VERSION "HNNBNNNYNNNNNNNNNNNNNNNNNNNNNNNNNNNNNNNNNN/4/%%%/4/'%**4NNN///"

NS_ :

BS_:

BU_: BAP_Tester CGS Gateway Gateway_PAG HUD Kombi Kombi_LB Kombi_PAG Waehlhebel_SB

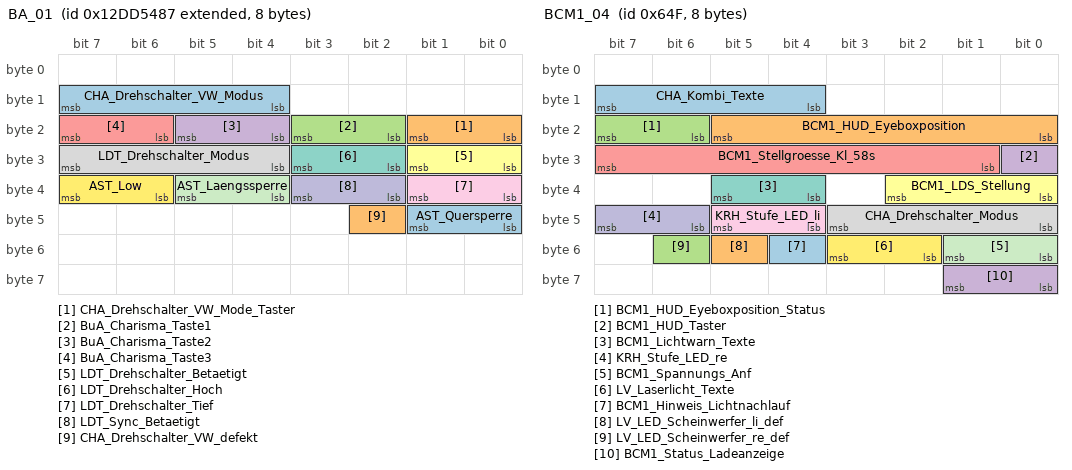
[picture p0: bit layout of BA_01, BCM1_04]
BO_ 2463978631 BA_01: 8 Kombi
 SG_ CHA_Drehschalter_VW_Modus : 12|4@1+ (1.0,0.0) [0.0|15] ""  Gateway,Gateway_PAG
 SG_ CHA_Drehschalter_VW_Mode_Taster : 16|2@1+ (1.0,0.0) [0.0|3] ""  Gateway,Gateway_PAG
 SG_ BuA_Charisma_Taste1 : 18|2@1+ (1.0,0.0) [0.0|3] ""  Gateway,Gateway_PAG
 SG_ BuA_Charisma_Taste2 : 20|2@1+ (1.0,0.0) [0.0|3] ""  Gateway,Gateway_PAG
 SG_ BuA_Charisma_Taste3 : 22|2@1+ (1.0,0.0) [0.0|3] ""  Gateway,Gateway_PAG
 SG_ LDT_Drehschalter_Betaetigt : 24|2@1+ (1.0,0.0) [0.0|3] ""  Gateway,Gateway_PAG
 SG_ LDT_Drehschalter_Hoch : 26|2@1+ (1.0,0.0) [0.0|3] ""  Gateway,Gateway_PAG
 SG_ LDT_Drehschalter_Modus : 28|4@1+ (1.0,0.0) [0.0|15] ""  Gateway,Gateway_PAG
 SG_ LDT_Drehschalter_Tief : 32|2@1+ (1.0,0.0) [0.0|3] ""  Gateway,Gateway_PAG
 SG_ LDT_Sync_Betaetigt : 34|2@1+ (1.0,0.0) [0.0|3] ""  Gateway,Gateway_PAG
 SG_ AST_Laengssperre : 36|2@1+ (1.0,0.0) [0.0|3] ""  Gateway,Gateway_PAG
 SG_ AST_Low : 38|2@1+ (1.0,0.0) [0.0|3] ""  Gateway,Gateway_PAG
 SG_ AST_Quersperre : 40|2@1+ (1.0,0.0) [0.0|3] ""  Gateway,Gateway_PAG
 SG_ CHA_Drehschalter_VW_defekt : 42|1@1+ (1.0,0.0) [0.0|1] ""  Gateway,Gateway_PAG

BO_ 2536703233 BAP_ACC_ASG_02: 8 Kombi
 SG_ BAP_ACC_ASG_02_Header : 0|8@1+ (1.0,0.0) [0.0|255] ""  Gateway,Gateway_PAG

BO_ 2536703248 BAP_ACC_FSG_01: 8 Gateway
 SG_ BAP_ACC_FSG_01_Header : 0|8@1+ (1.0,0.0) [0.0|255] ""  Kombi,Kombi_LB,Kombi_PAG

BO_ 2536722177 BAP_AHC_ASG_02: 8 Kombi_PAG
 SG_ BAP_AHC_ASG_02_Header : 0|8@1+ (1,0) [0|255] "Unit_None"  Gateway,Gateway_PAG

BO_ 2536722192 BAP_AHC_FSG_01: 8 Gateway
 SG_ BAP_AHC_FSG_01_Header : 0|8@1+ (1,0) [0|255] "Unit_None"  Kombi_PAG

BO_ 2536714496 BAP_Audio_ASG_01: 8 Kombi
 SG_ BAP_Audio_ASG_01_Header : 0|8@1+ (1.0,0.0) [0.0|255] ""  Gateway,Gateway_PAG

BO_ 2536714497 BAP_Audio_ASG_02: 8 Kombi
 SG_ BAP_Audio_ASG_02_Header : 0|8@1+ (1.0,0.0) [0.0|255] ""  Gateway,Gateway_PAG

BO_ 2536714498 BAP_Audio_ASG_03: 8 HUD
 SG_ BAP_Audio_ASG_03_Header : 0|8@1+ (1.0,0.0) [0.0|255] ""  Gateway,Gateway_PAG

BO_ 2536714499 BAP_Audio_ASG_04: 8 HUD
 SG_ BAP_Audio_ASG_04_Header : 0|8@1+ (1.0,0.0) [0.0|255] ""  Gateway,Gateway_PAG

BO_ 2536714512 BAP_Audio_FSG_01: 8 Gateway
 SG_ BAP_Audio_FSG_01_Header : 0|8@1+ (1.0,0.0) [0.0|255] ""  HUD,Kombi,Kombi_PAG

BO_ 2536714513 BAP_Audio_FSG_02: 8 Gateway
 SG_ BAP_Audio_FSG_02_Header : 0|8@1+ (1.0,0.0) [0.0|255] ""  HUD,Kombi,Kombi_PAG

BO_ 2536720385 BAP_AWC_ASG_02: 8 Kombi_PAG
 SG_ BAP_AWC_ASG_02_Header : 0|64@1+ (1.0,0.0) [0.0|18446744073709551615] ""  Gateway,Gateway_PAG

BO_ 2536720400 BAP_AWC_FSG_01: 8 Gateway
 SG_ BAP_AWC_FSG_01_Header : 0|8@1+ (1,0) [0|255] "Unit_None"  Kombi_PAG

BO_ 2536711426 BAP_BatteryControl_ASG_03: 8 Kombi
 SG_ BAP_BatteryControl_ASG_03_Header : 0|8@1+ (1.0,0.0) [0.0|255] ""  Gateway,Gateway_PAG

BO_ 2536711429 BAP_BatteryControl_ASG_06: 8 HUD
 SG_ BAP_BatteryControl_ASG_06_Header : 0|8@1+ (1.0,0.0) [0.0|255] ""  Gateway,Gateway_PAG

BO_ 2536711440 BAP_BatteryControl_FSG_01: 8 Gateway
 SG_ BAP_BatteryControl_FSG_01_Header : 0|8@1+ (1.0,0.0) [0.0|255] ""  HUD,Kombi,Kombi_LB,Kombi_PAG

BO_ 2536705792 BAP_BC_ASG_01: 8 Gateway
 SG_ BAP_BC_ASG_01_Header : 0|8@1+ (1.0,0.0) [0.0|255] ""  Kombi,Kombi_LB,Kombi_PAG

BO_ 2536705793 BAP_BC_ASG_02: 8 Gateway
 SG_ BAP_BC_ASG_02_Header : 0|8@1+ (1.0,0.0) [0.0|255] ""  Kombi,Kombi_LB,Kombi_PAG

BO_ 2536705794 BAP_BC_ASG_03: 8 Gateway
 SG_ BAP_BC_ASG_03_Header : 0|8@1+ (1.0,0.0) [0.0|255] ""  Kombi,Kombi_LB,Kombi_PAG

BO_ 2536705795 BAP_BC_ASG_04: 8 Gateway
 SG_ BAP_BC_ASG_04_Header : 0|8@1+ (1.0,0.0) [0.0|255] ""  Kombi,Kombi_LB,Kombi_PAG

BO_ 2536705796 BAP_BC_ASG_05: 8 Gateway_PAG
 SG_ BAP_BC_ASG_05_Header : 0|8@1+ (1,0) [0|255] "Unit_None"  Kombi_PAG

BO_ 2536705797 BAP_BC_ASG_06: 8 HUD
 SG_ BAP_BC_ASG_06_Header : 0|8@1+ (1,0) [0|255] "Unit_None"  Kombi_PAG

BO_ 2536705808 BAP_BC_FSG_01: 8 Kombi
 SG_ BAP_BC_FSG_01_Header : 0|8@1+ (1.0,0.0) [0.0|255] ""  Gateway,Gateway_PAG,HUD

BO_ 2536710912 BAP_BCmE_ASG_01: 8 Kombi
 SG_ BAP_BCmE_ASG_01_Header : 0|8@1+ (1.0,0.0) [0.0|255] ""  Gateway

BO_ 2536710928 BAP_BCmE_FSG_01: 8 Gateway
 SG_ BAP_BCmE_FSG_01_Header : 0|8@1+ (1.0,0.0) [0.0|255] ""  Kombi,Kombi_LB

BO_ 2536711680 BAP_Brake_ASG_01: 8 Gateway
 SG_ BAP_Brake_ASG_01_Header : 0|8@1+ (1.0,0.0) [0.0|255] ""  Kombi_PAG

BO_ 2536711696 BAP_Brake_FSG_01: 8 Kombi_PAG
 SG_ BAP_Brake_FSG_01_Header : 0|8@1+ (1.0,0.0) [0.0|255] ""  Gateway,Gateway_PAG

BO_ 2536707841 BAP_Charisma_ASG_02: 8 Kombi
 SG_ BAP_Charisma_ASG_02_Header : 0|8@1+ (1,0) [0|255] "Unit_None"  Gateway,Gateway_PAG

BO_ 2536707845 BAP_Charisma_ASG_06: 8 HUD
 SG_ BAP_Charisma_ASG_06_Header : 0|8@1+ (1.0,0.0) [0.0|255] ""  Gateway_PAG

BO_ 2536707856 BAP_Charisma_FSG_01: 8 Gateway
 SG_ BAP_Charisma_FSG_01_Header : 0|8@1+ (1.0,0.0) [0.0|255] ""  HUD,Kombi,Kombi_PAG

BO_ 2536767264 BAP_Debug_Cmd: 8 BAP_Tester
 SG_ BAP_Debug_Cmd : 0|16@1+ (1.0,0.0) [0.0|65535] ""  Gateway,Gateway_PAG,HUD,Kombi,Kombi_LB,Kombi_PAG

BO_ 2536767280 BAP_Debug_Data: 8 Gateway
 SG_ BAP_Debug_Data : 0|64@1+ (1.0,0.0) [0.0|18446744073709551615] ""  BAP_Tester

BO_ 2536719616 BAP_DisplayConfig_ASG_01: 8 Gateway
 SG_ BAP_DisplayConfig_ASG_01_Header : 0|8@1+ (1,0) [0|255] "Unit_None"  Kombi,Kombi_PAG

BO_ 2536719617 BAP_DisplayConfig_ASG_02: 8 Gateway
 SG_ BAP_DisplayConfig_ASG_02_Header : 0|64@1+ (1.0,0.0) [0.0|18446744073709551615] ""  Kombi,Kombi_PAG

BO_ 2536719632 BAP_DisplayConfig_FSG_01: 8 Kombi
 SG_ BAP_DisplayConfig_FSG_01_Header : 0|8@1+ (1,0) [0|255] "Unit_None"  Gateway,Gateway_PAG

BO_ 2536705282 BAP_Doorlocking_ASG_03: 8 Kombi
 SG_ BAP_Doorlocking_ASG_03_Header : 0|8@1+ (1.0,0.0) [0.0|255] ""  Gateway,Gateway_PAG

BO_ 2536705296 BAP_Doorlocking_FSG_01: 8 Gateway
 SG_ BAP_Doorlocking_FSG_01_Header : 0|8@1+ (1.0,0.0) [0.0|255] ""  Kombi,Kombi_LB,Kombi_PAG

BO_ 2536706816 BAP_Einheiten_ASG_01: 8 Gateway
 SG_ BAP_Einheiten_ASG_01_Header : 0|8@1+ (1.0,0.0) [0.0|255] ""  Kombi,Kombi_LB,Kombi_PAG

BO_ 2536706817 BAP_Einheiten_ASG_02: 8 Gateway
 SG_ BAP_Einheiten_ASG_02_Header : 0|8@1+ (1.0,0.0) [0.0|255] ""  Kombi_PAG

BO_ 2536706818 BAP_Einheiten_ASG_03: 8 Gateway
 SG_ BAP_Einheiten_ASG_03_Header : 0|8@1+ (1.0,0.0) [0.0|255] ""  Kombi,Kombi_LB,Kombi_PAG

BO_ 2536706819 BAP_Einheiten_ASG_04: 8 Gateway
 SG_ BAP_Einheiten_ASG_04_Header : 0|8@1+ (1,0) [0|255] "Unit_None"  Kombi,Kombi_LB,Kombi_PAG

BO_ 2536706832 BAP_Einheiten_FSG_01: 8 Kombi
 SG_ BAP_Einheiten_FSG_01_Header : 0|8@1+ (1.0,0.0) [0.0|255] ""  Gateway,Gateway_PAG

BO_ 2536702976 BAP_HUD_ASG_01: 8 Gateway
 SG_ BAP_HUD_ASG_01_Header : 0|8@1+ (1.0,0.0) [0.0|255] ""  HUD

BO_ 2536702977 BAP_HUD_ASG_02: 8 Kombi
 SG_ BAP_HUD_ASG_02_Header : 0|8@1+ (1,0) [0|255] "Unit_None"  HUD

BO_ 2536702978 BAP_HUD_ASG_03: 8 Gateway
 SG_ BAP_HUD_ASG_03_Header : 0|8@1+ (1,0) [0|255] "Unit_None"  HUD

BO_ 2536702992 BAP_HUD_FSG_01: 8 HUD
 SG_ BAP_HUD_FSG_01_Header : 0|8@1+ (1.0,0.0) [0.0|255] ""  Gateway,Gateway_PAG,Kombi,Kombi_PAG

BO_ 2536709121 BAP_Hybrid_ASG_02: 8 Kombi
 SG_ BAP_Hybrid_ASG_02_Header : 0|8@1+ (1.0,0.0) [0.0|255] ""  Gateway,Gateway_PAG

BO_ 2536709136 BAP_Hybrid_FSG_01: 8 Gateway
 SG_ BAP_Hybrid_FSG_01_Header : 0|8@1+ (1.0,0.0) [0.0|255] ""  Kombi,Kombi_LB,Kombi_PAG

BO_ 2536722945 BAP_IAA_PSO_ASG_02: 8 Kombi
 SG_ BAP_IAA_PSO_ASG_02_Header : 0|8@1+ (1,0) [0|255] "Unit_None"  Gateway

BO_ 2536722960 BAP_IAA_PSO_FSG_01: 8 Gateway
 SG_ BAP_IAA_PSO_FSG_01_Header : 0|8@1+ (1,0) [0|255] "Unit_None"  Kombi,Kombi_LB

BO_ 2536708353 BAP_LDW_ASG_02: 8 Kombi
 SG_ BAP_LDW_ASG_02_Header : 0|8@1+ (1.0,0.0) [0.0|255] ""  Gateway,Gateway_PAG

BO_ 2536708368 BAP_LDW_FSG_01: 8 Gateway
 SG_ BAP_LDW_FSG_01_Header : 0|8@1+ (1.0,0.0) [0.0|255] ""  Kombi,Kombi_LB,Kombi_PAG

BO_ 2536732672 BAP_LLCC_ASG_01: 8 Gateway
 SG_ BAP_LLCC_ASG_01_Header : 0|8@1+ (1,0) [0|255] "Unit_None"  Kombi_PAG

BO_ 2536732688 BAP_LLCC_FSG_01: 8 Kombi_PAG
 SG_ BAP_LLCC_FSG_01_Header : 0|8@1+ (1,0) [0|255] "Unit_None"  Gateway,Gateway_PAG

BO_ 2536715264 BAP_MFL_ASG_01: 8 Kombi
 SG_ BAP_MFL_ASG_01_Header : 0|8@1+ (1.0,0.0) [0.0|255] ""  Gateway,Gateway_PAG

BO_ 2536715280 BAP_MFL_FSG_01: 8 Gateway
 SG_ BAP_MFL_FSG_01_Header : 0|8@1+ (1.0,0.0) [0.0|255] ""  Kombi,Kombi_PAG

BO_ 2536714752 BAP_Navigation_ASG_01: 8 Kombi
 SG_ BAP_Navigation_ASG_01_Header : 0|8@1+ (1.0,0.0) [0.0|255] ""  Gateway,Gateway_PAG

BO_ 2536714753 BAP_Navigation_ASG_02: 8 Kombi
 SG_ BAP_Navigation_ASG_02_Header : 0|8@1+ (1.0,0.0) [0.0|255] ""  Gateway,Gateway_PAG

BO_ 2536714754 BAP_Navigation_ASG_03: 8 HUD
 SG_ BAP_Navigation_ASG_03_Header : 0|8@1+ (1.0,0.0) [0.0|255] ""  Gateway,Gateway_PAG

BO_ 2536714755 BAP_Navigation_ASG_04: 8 HUD
 SG_ BAP_Navigation_ASG_04_Header : 0|8@1+ (1.0,0.0) [0.0|255] ""  Gateway,Gateway_PAG

BO_ 2536714768 BAP_Navigation_FSG_01: 8 Gateway
 SG_ BAP_Navigation_FSG_01_Header : 0|8@1+ (1.0,0.0) [0.0|255] ""  HUD,Kombi,Kombi_PAG

BO_ 2536714769 BAP_Navigation_FSG_02: 8 Gateway
 SG_ BAP_Navigation_FSG_02_Header : 0|8@1+ (1.0,0.0) [0.0|255] ""  HUD,Kombi,Kombi_PAG

BO_ 2536708097 BAP_Nightvision_ASG_02: 8 Kombi
 SG_ BAP_Nightvision_ASG_02_Header : 0|8@1+ (1.0,0.0) [0.0|255] ""  Gateway,Gateway_PAG

BO_ 2536708112 BAP_Nightvision_FSG_01: 8 Gateway
 SG_ BAP_Nightvision_FSG_01_Header : 0|8@1+ (1.0,0.0) [0.0|255] ""  Kombi

BO_ 2536712704 BAP_OnlineFunctions_ASG_01: 8 Kombi
 SG_ BAP_OnlineFunction_ASG_01_Header : 0|8@1+ (1,0) [0|255] "Unit_None"  Gateway,Gateway_PAG

BO_ 2536712705 BAP_OnlineFunctions_ASG_02: 8 HUD
 SG_ BAP_OnlineFunction_ASG_02_Header : 0|8@1+ (1,0) [0|255] "Unit_None"  Gateway,Gateway_PAG

BO_ 2536712720 BAP_OnlineFunctions_FSG_01: 8 Gateway
 SG_ BAP_OnlineFunction_FSG_01_Header : 0|8@1+ (1,0) [0|255] "Unit_None"  HUD,Kombi,Kombi_PAG

BO_ 2536702723 BAP_ParkHeater_ASG_04: 8 Kombi_PAG
 SG_ BAP_ParkHeater_ASG_04_Header : 0|64@1+ (1.0,0.0) [0.0|18446744073709551615] ""  Gateway,Gateway_PAG

BO_ 2536702736 BAP_ParkHeater_FSG_01: 8 Gateway
 SG_ BAP_ParkHeater_FSG_01_Header : 0|8@1+ (1.0,0.0) [0.0|255] ""  Kombi_PAG

BO_ 2536703745 BAP_RDK_ASG_02: 8 Kombi
 SG_ BAP_RDK_ASG_02_Header : 0|8@1+ (1.0,0.0) [0.0|255] ""  Gateway,Gateway_PAG

BO_ 2536703760 BAP_RDK_FSG_01: 8 Gateway
 SG_ BAP_RDK_FSG_01_Header : 0|8@1+ (1.0,0.0) [0.0|255] ""  Kombi,Kombi_LB,Kombi_PAG

BO_ 2536709889 BAP_RGS_ASG_02: 8 Kombi
 SG_ BAP_RGS_ASG_02_Header : 0|8@1+ (1,0) [0|255] "Unit_None"  Gateway,Gateway_PAG

BO_ 2536709904 BAP_RGS_FSG_01: 8 Gateway
 SG_ BAP_RGS_FSG_01_Header : 0|8@1+ (1.0,0.0) [0.0|255] ""  Kombi,Kombi_LB

BO_ 2536719872 BAP_SDS_ASG_01: 8 Kombi
 SG_ BAP_SDS_ASG_01_Header : 0|8@1+ (1,0) [0|255] "Unit_None"  Gateway,Gateway_PAG

BO_ 2536719888 BAP_SDS_FSG_01: 8 Gateway
 SG_ BAP_SDS_FSG_01_Header : 0|8@1+ (1,0) [0|255] "Unit_None"  Kombi,Kombi_PAG

BO_ 2536706560 BAP_SIA_ASG_01: 8 Gateway
 SG_ BAP_SIA_ASG_01_Header : 0|8@1+ (1.0,0.0) [0.0|255] ""  Kombi,Kombi_LB,Kombi_PAG

BO_ 2536706561 BAP_SIA_ASG_02: 8 Gateway
 SG_ BAP_SIA_ASG_02_Header : 0|8@1+ (1.0,0.0) [0.0|255] ""  Kombi,Kombi_LB,Kombi_PAG

BO_ 2536706562 BAP_SIA_ASG_03: 8 Gateway
 SG_ BAP_SIA_ASG_03_Header : 0|8@1+ (1,0) [0|255] "Unit_None"  Kombi_PAG

BO_ 2536706576 BAP_SIA_FSG_01: 8 Kombi
 SG_ BAP_SIA_FSG_01_Header : 0|8@1+ (1.0,0.0) [0.0|255] ""  Gateway,Gateway_PAG

BO_ 2536720896 BAP_Statistics_ASG_01: 8 Gateway
 SG_ BAP_Statistics_ASG_01_Header : 0|8@1+ (1,0) [0|255] "Unit_None"  Kombi

BO_ 2536720912 BAP_Statistics_FSG_01: 8 Kombi
 SG_ BAP_Statistics_FSG_01_Header : 0|8@1+ (1,0) [0|255] "Unit_None"  Gateway,Gateway_PAG

BO_ 2536703489 BAP_SuspensionControl_ASG_02: 8 Kombi
 SG_ BAP_SuspensionControl_ASG_02_Hea : 0|8@1+ (1.0,0.0) [0.0|255] ""  Gateway,Gateway_PAG

BO_ 2536703504 BAP_SuspensionControl_FSG_01: 8 Gateway
 SG_ BAP_SuspensionControl_FSG_01_Hea : 0|8@1+ (1.0,0.0) [0.0|255] ""  Kombi,Kombi_PAG

BO_ 2536708609 BAP_SWA_ASG_02: 8 Kombi
 SG_ BAP_SWA_ASG_02_Header : 0|8@1+ (1.0,0.0) [0.0|255] ""  Gateway,Gateway_PAG

BO_ 2536708624 BAP_SWA_FSG_01: 8 Gateway
 SG_ BAP_SWA_FSG_01_Header : 0|8@1+ (1.0,0.0) [0.0|255] ""  Kombi,Kombi_LB

BO_ 2536712448 BAP_Telefon2_ASG_01: 8 Kombi
 SG_ BAP_Telefon2_ASG_01_Header : 0|8@1+ (1.0,0.0) [0.0|255] ""  Gateway,Gateway_PAG

BO_ 2536712449 BAP_Telefon2_ASG_02: 8 HUD
 SG_ BAP_Telefon2_ASG_02_Header : 0|8@1+ (1,0) [0|255] "Unit_None"  Gateway,Gateway_PAG

BO_ 2536712464 BAP_Telefon2_FSG_01: 8 Gateway
 SG_ BAP_Telefon2_FSG_01_Header : 0|8@1+ (1.0,0.0) [0.0|255] ""  HUD,Kombi,Kombi_PAG

BO_ 2536712465 BAP_Telefon2_FSG_02: 8 Gateway
 SG_ BAP_Telefon2_FSG_02_Header : 0|8@1+ (1,0) [0|255] "Unit_None"  HUD,Kombi,Kombi_PAG

BO_ 2536712192 BAP_Telefon_ASG_01: 8 Kombi
 SG_ BAP_Telefon_ASG_01_Header : 0|8@1+ (1.0,0.0) [0.0|255] ""  Gateway,Gateway_PAG

BO_ 2536712193 BAP_Telefon_ASG_02: 8 Kombi
 SG_ BAP_Telefon_ASG_02_Header : 0|8@1+ (1.0,0.0) [0.0|255] ""  Gateway,Gateway_PAG

BO_ 2536712194 BAP_Telefon_ASG_03: 8 HUD
 SG_ BAP_Telefon_ASG_03_Header : 0|8@1+ (1,0) [0|255] "Unit_None"  Gateway,Gateway_PAG

BO_ 2536712195 BAP_Telefon_ASG_04: 8 HUD
 SG_ BAP_Telefon_ASG_04_Header : 0|8@1+ (1,0) [0|255] "Unit_None"  Gateway,Gateway_PAG

BO_ 2536712208 BAP_Telefon_FSG_01: 8 Gateway
 SG_ BAP_Telefon_FSG_01_Header : 0|8@1+ (1.0,0.0) [0.0|255] ""  HUD,Kombi,Kombi_PAG

BO_ 2536712209 BAP_Telefon_FSG_02: 8 Gateway
 SG_ BAP_Telefon_FSG_02_Header : 0|8@1+ (1.0,0.0) [0.0|255] ""  HUD,Kombi,Kombi_PAG

BO_ 2536711169 BAP_TiltAngle_ASG_02: 8 Kombi
 SG_ BAP_TiltAngle_ASG_02_Header : 0|8@1+ (1.0,0.0) [0.0|255] ""  Gateway,Gateway_PAG

BO_ 2536711170 BAP_TiltAngle_ASG_03: 8 HUD
 SG_ BAP_TiltAngle_ASG_03_Header : 0|8@1+ (1,0) [0|255] "Unit_None"  Gateway,Gateway_PAG

BO_ 2536711184 BAP_TiltAngle_FSG_01: 8 Gateway
 SG_ BAP_TiltAngle_FSG_01_Header : 0|8@1+ (1.0,0.0) [0.0|255] ""  HUD,Kombi,Kombi_LB

BO_ 2536706304 BAP_Uhrzeit_ASG_01: 8 Gateway
 SG_ BAP_Uhrzeit_ASG_01_Header : 0|8@1+ (1.0,0.0) [0.0|255] ""  Kombi,Kombi_LB,Kombi_PAG

BO_ 2536706305 BAP_Uhrzeit_ASG_02: 8 Gateway
 SG_ BAP_Uhrzeit_ASG_02_Header : 0|8@1+ (1.0,0.0) [0.0|255] ""  Kombi,Kombi_LB,Kombi_PAG

BO_ 2536706306 BAP_Uhrzeit_ASG_03: 8 Gateway
 SG_ BAP_Uhrzeit_ASG_03_Header : 0|8@1+ (1.0,0.0) [0.0|255] ""  Kombi,Kombi_LB,Kombi_PAG

BO_ 2536706308 BAP_Uhrzeit_ASG_05: 8 Gateway
 SG_ BAP_Uhrzeit_ASG_05_Header : 0|8@1+ (1.0,0.0) [0.0|255] ""  Kombi,Kombi_LB,Kombi_PAG

BO_ 2536706309 BAP_Uhrzeit_ASG_06: 8 Gateway
 SG_ BAP_Uhrzeit_ASG_06_Header : 0|8@1+ (1.0,0.0) [0.0|255] ""  Kombi,Kombi_LB,Kombi_PAG

BO_ 2536706310 BAP_Uhrzeit_ASG_07: 8 Gateway
 SG_ BAP_Uhrzeit_ASG_07_Header : 0|64@1+ (1.0,0.0) [0.0|18446744073709551615] ""  Kombi_LB,Kombi_PAG

BO_ 2536706311 BAP_Uhrzeit_ASG_08: 8 HUD
 SG_ BAP_Uhrzeit_ASG_08_Header : 0|8@1+ (1,0) [0|255] "Unit_None"  Kombi_PAG

BO_ 2536706320 BAP_Uhrzeit_FSG_01: 8 Kombi
 SG_ BAP_Uhrzeit_FSG_01_Header : 0|8@1+ (1.0,0.0) [0.0|255] ""  Gateway,Gateway_PAG,HUD

BO_ 2536710401 BAP_VZA_ASG_02: 8 Kombi
 SG_ BAP_VZA_ASG_02_Header : 0|8@1+ (1.0,0.0) [0.0|255] ""  Gateway,Gateway_PAG

BO_ 2536710416 BAP_VZA_FSG_01: 8 Gateway
 SG_ BAP_VZA_FSG_01_Header : 0|8@1+ (1.0,0.0) [0.0|255] ""  Kombi,Kombi_LB,Kombi_PAG

BO_ 1615 BCM1_04: 8 Gateway
 SG_ CHA_Kombi_Texte : 12|4@1+ (1.0,0.0) [0.0|15] ""  Vector__XXX
 SG_ BCM1_HUD_Eyeboxposition : 16|6@1+ (1,0) [0|63] ""  HUD
 SG_ BCM1_HUD_Eyeboxposition_Status : 22|2@1+ (1.0,0.0) [0.0|3] ""  HUD
 SG_ BCM1_HUD_Taster : 24|1@1+ (1.0,0.0) [0.0|1] ""  HUD
 SG_ BCM1_Stellgroesse_Kl_58s : 25|7@1+ (1,0) [0|100] ""  HUD
 SG_ BCM1_LDS_Stellung : 32|3@1+ (1.0,0.0) [0.0|7] ""  Vector__XXX
 SG_ BCM1_Lichtwarn_Texte : 36|2@1+ (1.0,0.0) [0.0|3] ""  Vector__XXX
 SG_ CHA_Drehschalter_Modus : 40|4@1+ (1.0,0.0) [0.0|15] ""  Vector__XXX
 SG_ KRH_Stufe_LED_li : 44|2@1+ (1.0,0.0) [0.0|3] ""  Vector__XXX
 SG_ KRH_Stufe_LED_re : 46|2@1+ (1.0,0.0) [0.0|3] ""  Vector__XXX
 SG_ BCM1_Spannungs_Anf : 48|2@1+ (1.0,0.0) [0.0|3] ""  Vector__XXX
 SG_ LV_Laserlicht_Texte : 50|2@1+ (1.0,0.0) [0.0|3] ""  Kombi,Kombi_LB
 SG_ BCM1_Hinweis_Lichtnachlauf : 52|1@1+ (1.0,0.0) [0.0|1] ""  Vector__XXX
 SG_ LV_LED_Scheinwerfer_li_def : 53|1@1+ (1.0,0.0) [0.0|1] ""  Vector__XXX
 SG_ LV_LED_Scheinwerfer_re_def : 54|1@1+ (1.0,0.0) [0.0|1] ""  Vector__XXX
 SG_ BCM1_Status_Ladeanzeige : 56|2@1+ (1.0,0.0) [0.0|3] ""  Vector__XXX

BO_ 1626 BCM_01: 8 Gateway
 SG_ BCM_Bremsbelag_Sensor : 12|1@1+ (1.0,0.0) [0.0|1] ""  Kombi,Kombi_LB,Kombi_PAG
 SG_ BCM_Bremsfluessigkeit_Sensor : 13|1@1+ (1.0,0.0) [0.0|1] ""  Kombi,Kombi_LB,Kombi_PAG
 SG_ BCM1_Licht_Warn : 14|1@1+ (1.0,0.0) [0.0|1] ""  Vector__XXX
 SG_ BCM_Waschwasser_Sensor : 15|1@1+ (1.0,0.0) [0.0|1] ""  Kombi,Kombi_LB,Kombi_PAG
 SG_ BCM_Kuehlmittel_Sensor : 16|1@1+ (1.0,0.0) [0.0|1] ""  Kombi,Kombi_LB,Kombi_PAG
 SG_ BCM1_Kl_15_HW_erkannt : 17|1@1+ (1.0,0.0) [0.0|1] ""  Vector__XXX
 SG_ BCM1_Kl_15_Sig_HW_erkannt : 18|1@1+ (1.0,0.0) [0.0|1] ""  Vector__XXX
 SG_ BCM_Kuehlmittel_Sensor_02 : 19|1@1+ (1.0,0.0) [0.0|1] ""  Kombi,Kombi_LB,Kombi_PAG
 SG_ BCM1_Hinweis_Lichtnachlauf : 20|1@1+ (1.0,0.0) [0.0|1] ""  Kombi,Kombi_LB,Kombi_PAG
 SG_ BCM_Offroad_Taste : 21|1@1+ (1.0,0.0) [0.0|1] ""  Vector__XXX
 SG_ BCM_Hybrid_StSt_Taste_Fehler : 23|1@1+ (1.0,0.0) [0.0|1] ""  Vector__XXX
 SG_ BCM_Hybrid_StartStopp_Taste : 24|1@1+ (1.0,0.0) [0.0|1] ""  Vector__XXX
 SG_ BCM1_Warnblink_Taster : 25|1@1+ (1.0,0.0) [0.0|1] ""  Vector__XXX
 SG_ BCM1_Valet_Parking_Taster : 26|1@1+ (1.0,0.0) [0.0|1] ""  Vector__XXX
 SG_ BCM1_LDS_Stellung : 27|3@1+ (1.0,0.0) [0.0|7] ""  Vector__XXX
 SG_ BCM1_Rueckfahrlicht_Schalter : 30|1@1+ (1.0,0.0) [0.0|1] ""  Vector__XXX
 SG_ BCM1_MH_Schalter : 31|1@1+ (1.0,0.0) [0.0|1] ""  Kombi,Kombi_LB,Kombi_PAG
 SG_ BCM1_MH_WIV_Schalter : 32|1@1+ (1.0,0.0) [0.0|1] ""  Vector__XXX
 SG_ BCM_Eco_Charisma_Taste : 33|1@1+ (1.0,0.0) [0.0|1] ""  Vector__XXX
 SG_ BCM1_NV_Taster : 34|1@1+ (1.0,0.0) [0.0|1] ""  Kombi,Kombi_LB,Kombi_PAG
 SG_ BCM1_AFS_Lampe : 35|1@1+ (1.0,0.0) [0.0|1] ""  Kombi,Kombi_LB,Kombi_PAG
 SG_ BCM1_Reisemodus_Texte : 36|2@1+ (1.0,0.0) [0.0|3] ""  Kombi,Kombi_LB,Kombi_PAG
 SG_ BCM1_Lichtwarn_Texte : 38|2@1+ (1.0,0.0) [0.0|3] ""  Kombi,Kombi_LB,Kombi_PAG
 SG_ Gong_TFL_Umschaltung : 40|1@1+ (1.0,0.0) [0.0|1] ""  Vector__XXX
 SG_ UGDO_Function_01 : 41|3@1+ (1.0,0.0) [0.0|7] ""  Vector__XXX
 SG_ APS_Tongeber_defekt : 44|1@1+ (1.0,0.0) [0.0|1] ""  Vector__XXX
 SG_ BCM1_EasyEntry_Status : 45|1@1+ (1.0,0.0) [0.0|1] ""  Vector__XXX
 SG_ BCM1_Lenksaeule_aktiv : 46|1@1+ (1.0,0.0) [0.0|1] ""  Vector__XXX
 SG_ BCM1_St_SW_Diebstahl_links : 47|1@1+ (1.0,0.0) [0.0|1] ""  Vector__XXX
 SG_ BCM1_St_SW_Diebstahl_rechts : 48|1@1+ (1.0,0.0) [0.0|1] ""  Vector__XXX
 SG_ ISP_Dimmung_ASP_02 : 49|6@1+ (0.0226,0) [0.0000|1.4012] "Unit_Volt"  Vector__XXX
 SG_ BCM1_Schluesselsuche_Anf : 55|1@1+ (1.0,0.0) [0.0|1] ""  Vector__XXX
 SG_ BCM1_Fahrlicht_Hinweis : 62|1@1+ (1.0,0.0) [0.0|1] ""  Kombi,Kombi_LB,Kombi_PAG
 SG_ BCM_HDF_betaetigt : 63|1@1+ (1.0,0.0) [0.0|1] ""  Vector__XXX

BO_ 672 BCM_02: 8 Gateway
 SG_ BCM_02_CRC : 0|8@1+ (1,0) [0|255] ""  Kombi_PAG
 SG_ BCM_02_BZ : 8|4@1+ (1,0) [0|15] ""  Kombi_PAG
 SG_ BCM2_Crashfall_erkannt : 12|1@1+ (1.0,0.0) [0.0|1] ""  Vector__XXX
 SG_ ZZH_Endlage_oben : 13|1@1+ (1.0,0.0) [0.0|1] ""  Vector__XXX
 SG_ ZZH_Endlage_unplausibel : 14|1@1+ (1.0,0.0) [0.0|1] ""  Vector__XXX
 SG_ ZZH_Endlage_unten : 15|1@1+ (1.0,0.0) [0.0|1] ""  Vector__XXX
 SG_ BCM2_Unterdr_Zuendungsmeldung : 16|1@1+ (1.0,0.0) [0.0|1] ""  Vector__XXX
 SG_ BCM2_SST_gedrueckt : 17|1@1+ (1.0,0.0) [0.0|1] ""  Vector__XXX
 SG_ BCM_Waehlhebel_P_Hinweis : 18|1@1+ (1.0,0.0) [0.0|1] ""  Kombi,Kombi_LB,Kombi_PAG
 SG_ BCM_ValetTaster_Fkts_LED : 19|1@1+ (1.0,0.0) [0.0|1] ""  Kombi,Kombi_LB
 SG_ BCM2_KL15_Absch_FT : 20|1@1+ (1.0,0.0) [0.0|1] ""  Vector__XXX
 SG_ Heckwischer_Status : 21|2@1+ (1.0,0.0) [0.0|3] ""  Vector__XXX
 SG_ BCM2_P_verriegelt : 23|1@1+ (1.0,0.0) [0.0|1] ""  Vector__XXX
 SG_ FSH_LED : 24|1@1+ (1.0,0.0) [0.0|1] ""  Kombi_PAG
 SG_ HSH_LED : 25|1@1+ (1.0,0.0) [0.0|1] ""  Vector__XXX
 SG_ Niveausensor_VL_verbaut : 26|1@1+ (1.0,0.0) [0.0|1] ""  Vector__XXX
 SG_ Niveausensor_HL_verbaut : 27|1@1+ (1.0,0.0) [0.0|1] ""  Vector__XXX
 SG_ FA_Hoehenwert_VL_01 : 28|8@1+ (0.4,0) [0.0|100.0] "Unit_PerCent"  Vector__XXX
 SG_ FA_Hoehenwert_HL_01 : 36|8@1+ (0.4,0) [0.0|100.0] "Unit_PerCent"  Vector__XXX
 SG_ BCM_Anf_Aussenwarnung : 44|1@1+ (1.0,0.0) [0.0|1] ""  Vector__XXX
 SG_ BCM_Aussenwarnung_Konfig : 45|3@1+ (1.0,0.0) [0.0|7] ""  Vector__XXX
 SG_ BCM2_Freigabe_Kofferr_Innenentr : 48|1@1+ (1.0,0.0) [0.0|1] ""  Vector__XXX
 SG_ BCM_RLU_Wakeup_Anforderung : 49|1@1+ (1.0,0.0) [0.0|1] ""  Vector__XXX
 SG_ Heckrollo_Privacy_aktiv : 50|1@1+ (1.0,0.0) [0.0|1] ""  Vector__XXX
 SG_ Heckrollo_Verfahrrichtung : 51|3@1+ (1.0,0.0) [0.0|7] ""  Vector__XXX
 SG_ BCM2_TrunkEntrapment_Warn : 54|1@1+ (1.0,0.0) [0.0|1] ""  Kombi,Kombi_LB,Kombi_PAG
 SG_ BCM2_Quittierung_Warnton_aktiv : 55|1@1+ (1.0,0.0) [0.0|1] ""  Vector__XXX
 SG_ BCM_Handbremse_Hinweis : 56|1@1+ (1.0,0.0) [0.0|1] ""  Kombi,Kombi_LB,Kombi_PAG
 SG_ Remote_Rollo_HBFS_hoch : 57|1@1+ (1.0,0.0) [0.0|1] ""  Vector__XXX
 SG_ Remote_Rollo_HBFS_tief : 58|1@1+ (1.0,0.0) [0.0|1] ""  Vector__XXX
 SG_ Remote_Rollo_HFS_hoch : 59|1@1+ (1.0,0.0) [0.0|1] ""  Vector__XXX
 SG_ Remote_Rollo_HFS_tief : 60|1@1+ (1.0,0.0) [0.0|1] ""  Vector__XXX
 SG_ BCM2_T_Deckel_Vorne : 61|1@1+ (1.0,0.0) [0.0|1] ""  Vector__XXX

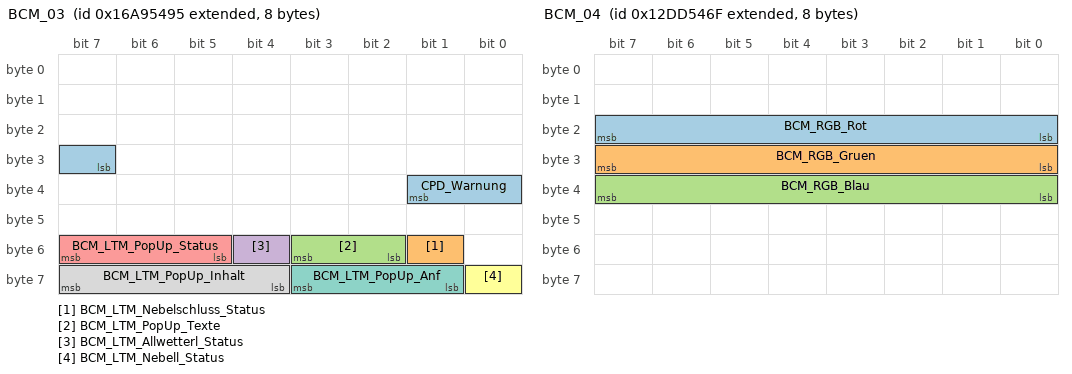
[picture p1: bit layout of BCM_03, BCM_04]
BO_ 2527679637 BCM_03: 8 Gateway
 SG_ CPD_Warnung : 31|3@1+ (1.0,0.0) [0.0|7] ""  Kombi,Kombi_LB,Kombi_PAG
 SG_ BCM_LTM_Nebelschluss_Status : 49|1@1+ (1.0,0.0) [0.0|1] ""  Kombi,Kombi_LB,Kombi_PAG
 SG_ BCM_LTM_PopUp_Texte : 50|2@1+ (1.0,0.0) [0.0|3] ""  Kombi_PAG
 SG_ BCM_LTM_Allwetterl_Status : 52|1@1+ (1.0,0.0) [0.0|1] ""  Kombi,Kombi_LB,Kombi_PAG
 SG_ BCM_LTM_PopUp_Status : 53|3@1+ (1.0,0.0) [0.0|7] ""  Kombi,Kombi_LB,Kombi_PAG
 SG_ BCM_LTM_Nebell_Status : 56|1@1+ (1.0,0.0) [0.0|1] ""  Kombi,Kombi_LB,Kombi_PAG
 SG_ BCM_LTM_PopUp_Anf : 57|3@1+ (1.0,0.0) [0.0|7] ""  Kombi,Kombi_LB,Kombi_PAG
 SG_ BCM_LTM_PopUp_Inhalt : 60|4@1+ (1.0,0.0) [0.0|15] ""  Kombi,Kombi_LB,Kombi_PAG

BO_ 2463978607 BCM_04: 8 Gateway
 SG_ BCM_RGB_Rot : 16|8@1+ (1,0) [0|255] ""  Kombi
 SG_ BCM_RGB_Gruen : 24|8@1+ (1,0) [0|255] ""  Kombi,Kombi_LB
 SG_ BCM_RGB_Blau : 32|8@1+ (1,0) [0|255] ""  Kombi,Kombi_LB

BO_ 870 Blinkmodi_02: 8 Gateway
 SG_ BM_ZV_auf : 12|1@1+ (1.0,0.0) [0.0|1] ""  Vector__XXX
 SG_ BM_ZV_zu : 13|1@1+ (1.0,0.0) [0.0|1] ""  Vector__XXX
 SG_ BM_DWA_ein : 14|1@1+ (1.0,0.0) [0.0|1] ""  Vector__XXX
 SG_ BM_DWA_Alarm : 15|1@1+ (1.0,0.0) [0.0|1] ""  Vector__XXX
 SG_ BM_Crash : 16|1@1+ (1.0,0.0) [0.0|1] ""  Vector__XXX
 SG_ BM_Panik : 17|1@1+ (1.0,0.0) [0.0|1] ""  Vector__XXX
 SG_ BM_Not_Bremsung : 18|1@1+ (1.0,0.0) [0.0|1] ""  Vector__XXX
 SG_ BM_GDO : 19|1@1+ (1.0,0.0) [0.0|1] ""  Vector__XXX
 SG_ BM_Warnblinken : 20|1@1+ (1.0,0.0) [0.0|1] ""  Kombi,Kombi_LB
 SG_ BM_Taxi_Notalarm : 21|1@1+ (1.0,0.0) [0.0|1] ""  Vector__XXX
 SG_ BM_Telematik : 22|1@1+ (1.0,0.0) [0.0|1] ""  Vector__XXX
 SG_ BM_links : 23|1@1+ (1.0,0.0) [0.0|1] ""  Vector__XXX
 SG_ BM_rechts : 24|1@1+ (1.0,0.0) [0.0|1] ""  Vector__XXX
 SG_ Blinken_li_Fzg_Takt : 25|1@1+ (1.0,0.0) [0.0|1] ""  Vector__XXX
 SG_ Blinken_re_Fzg_Takt : 26|1@1+ (1.0,0.0) [0.0|1] ""  Vector__XXX
 SG_ Blinken_li_Kombi_Takt : 27|1@1+ (1.0,0.0) [0.0|1] ""  Kombi,Kombi_LB,Kombi_PAG
 SG_ Blinken_re_Kombi_Takt : 28|1@1+ (1.0,0.0) [0.0|1] ""  Kombi,Kombi_LB,Kombi_PAG
 SG_ BM_NBA_n_codiert_n_aktiv : 29|1@1+ (1.0,0.0) [0.0|1] ""  Vector__XXX
 SG_ BM_NBA_Status : 30|2@1+ (1.0,0.0) [0.0|3] ""  Vector__XXX
 SG_ BM_WBT_Beleuchtung : 32|1@1+ (1.0,0.0) [0.0|1] ""  Vector__XXX
 SG_ BM_HD_Oeffnung_angelernt : 33|1@1+ (1.0,0.0) [0.0|1] ""  Vector__XXX
 SG_ BM_Autobahn : 34|1@1+ (1.0,0.0) [0.0|1] ""  Vector__XXX
 SG_ BM_Rollenmodus_Blinken : 35|1@1+ (1.0,0.0) [0.0|1] ""  Vector__XXX
 SG_ BM_Recas : 36|1@1+ (1.0,0.0) [0.0|1] ""  Vector__XXX
 SG_ BM_Wischblinken : 37|1@1+ (1.0,0.0) [0.0|1] ""  Vector__XXX
 SG_ BM_Telematik_Abbruchgrund : 38|6@1+ (1.0,0.0) [0.0|63] ""  Vector__XXX
 SG_ BM_PiloPa : 44|1@1+ (1.0,0.0) [0.0|1] ""  Vector__XXX
 SG_ DWA_Alarmquelle : 59|5@1+ (1.0,0.0) [0.0|31] ""  Vector__XXX

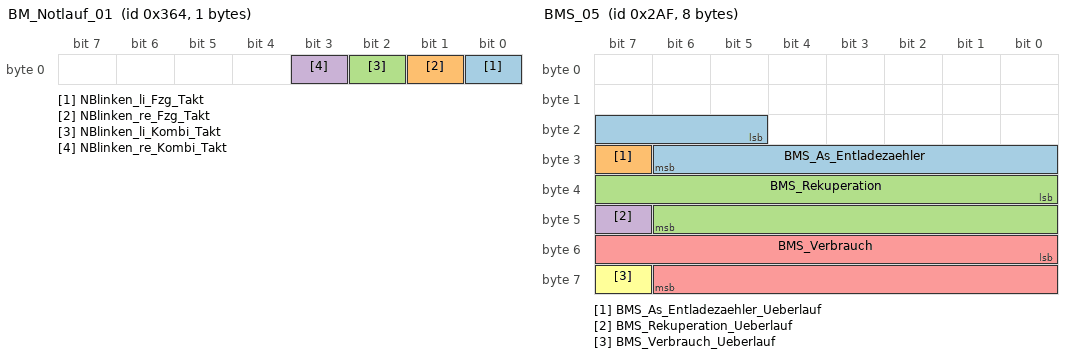
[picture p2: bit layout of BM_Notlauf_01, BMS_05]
BO_ 868 BM_Notlauf_01: 1 Gateway
 SG_ NBlinken_li_Fzg_Takt : 0|1@1+ (1.0,0.0) [0.0|1] ""  Vector__XXX
 SG_ NBlinken_re_Fzg_Takt : 1|1@1+ (1.0,0.0) [0.0|1] ""  Vector__XXX
 SG_ NBlinken_li_Kombi_Takt : 2|1@1+ (1.0,0.0) [0.0|1] ""  Kombi,Kombi_LB,Kombi_PAG
 SG_ NBlinken_re_Kombi_Takt : 3|1@1+ (1.0,0.0) [0.0|1] ""  Kombi,Kombi_LB,Kombi_PAG

BO_ 687 BMS_05: 8 Gateway
 SG_ BMS_As_Entladezaehler : 21|10@1+ (1,0) [0|1023] "Unit_AmperSecon"  Kombi,Kombi_LB,Kombi_PAG
 SG_ BMS_As_Entladezaehler_Ueberlauf : 31|1@1+ (1.0,0.0) [0.0|1] ""  Kombi,Kombi_LB,Kombi_PAG
 SG_ BMS_Rekuperation : 32|15@1+ (10,0) [0|327670] "Unit_WattSecond"  Kombi,Kombi_LB,Kombi_PAG
 SG_ BMS_Rekuperation_Ueberlauf : 47|1@1+ (1.0,0.0) [0.0|1] ""  Kombi,Kombi_LB,Kombi_PAG
 SG_ BMS_Verbrauch : 48|15@1+ (10,0) [0|327670] "Unit_WattSecond"  Kombi,Kombi_LB,Kombi_PAG
 SG_ BMS_Verbrauch_Ueberlauf : 63|1@1+ (1.0,0.0) [0.0|1] ""  Kombi,Kombi_LB,Kombi_PAG

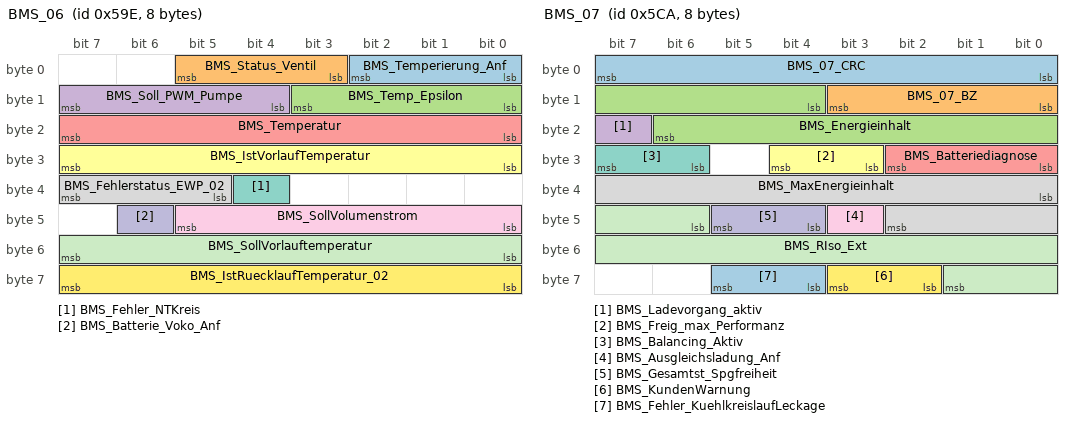
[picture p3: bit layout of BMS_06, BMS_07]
BO_ 1438 BMS_06: 8 Gateway
 SG_ BMS_Temperierung_Anf : 0|3@1+ (1.0,0.0) [0.0|7] ""  Vector__XXX
 SG_ BMS_Status_Ventil : 3|3@1+ (1.0,0.0) [0.0|7] ""  Vector__XXX
 SG_ BMS_Temp_Epsilon : 8|4@1+ (1,-15) [-15|0] "Unit_DegreCelsi"  Vector__XXX
 SG_ BMS_Soll_PWM_Pumpe : 12|4@1+ (10,0) [0|100] "Unit_PerCent"  Vector__XXX
 SG_ BMS_Temperatur : 16|8@1+ (0.5,-40) [-40.0|86.5] "Unit_DegreCelsi"  Kombi,Kombi_LB,Kombi_PAG
 SG_ BMS_IstVorlaufTemperatur : 24|8@1+ (0.5,-40) [-40.0|86.5] "Unit_DegreCelsi"  Vector__XXX
 SG_ BMS_Fehler_NTKreis : 36|1@1+ (1.0,0.0) [0.0|1] ""  Vector__XXX
 SG_ BMS_Fehlerstatus_EWP_02 : 37|3@1+ (1.0,0.0) [0.0|7] ""  Vector__XXX
 SG_ BMS_SollVolumenstrom : 40|6@1+ (1,0) [0|61] "Unit_LiterPerMinut"  Vector__XXX
 SG_ BMS_Batterie_Voko_Anf : 46|1@1+ (1.0,0.0) [0.0|1] ""  Vector__XXX
 SG_ BMS_SollVorlauftemperatur : 48|8@1+ (0.5,-40) [-40.0|86.5] "Unit_DegreCelsi"  Vector__XXX
 SG_ BMS_IstRuecklaufTemperatur_02 : 56|8@1+ (0.5,-40) [-40.0|86.5] "Unit_DegreCelsi"  Vector__XXX

BO_ 1482 BMS_07: 8 Gateway
 SG_ BMS_07_CRC : 0|8@1+ (1,0) [0|255] ""  Vector__XXX
 SG_ BMS_07_BZ : 8|4@1+ (1,0) [0|15] ""  Vector__XXX
 SG_ BMS_Energieinhalt : 12|11@1+ (50,0) [0|102250] "Unit_WattHour"  Kombi,Kombi_LB,Kombi_PAG
 SG_ BMS_Ladevorgang_aktiv : 23|1@1+ (1.0,0.0) [0.0|1] ""  Kombi,Kombi_LB,Kombi_PAG
 SG_ BMS_Batteriediagnose : 24|3@1+ (1.0,0.0) [0.0|7] ""  Kombi,Kombi_LB,Kombi_PAG
 SG_ BMS_Freig_max_Performanz : 27|2@1+ (1.0,0.0) [0.0|3] ""  Vector__XXX
 SG_ BMS_Balancing_Aktiv : 30|2@1+ (1.0,0.0) [0.0|3] ""  Vector__XXX
 SG_ BMS_MaxEnergieinhalt : 32|11@1+ (50,0) [0|102250] "Unit_WattHour"  Kombi,Kombi_LB,Kombi_PAG
 SG_ BMS_Ausgleichsladung_Anf : 43|1@1+ (1.0,0.0) [0.0|1] ""  Vector__XXX
 SG_ BMS_Gesamtst_Spgfreiheit : 44|2@1+ (1.0,0.0) [0.0|3] ""  Vector__XXX
 SG_ BMS_RIso_Ext : 46|12@1+ (5,0) [0|20465] "Unit_KiloOhm"  Vector__XXX
 SG_ BMS_KundenWarnung : 58|2@1+ (1.0,0.0) [0.0|3] ""  Kombi,Kombi_LB,Kombi_PAG
 SG_ BMS_Fehler_KuehlkreislaufLeckage : 60|2@1+ (1.0,0.0) [0.0|3] ""  Vector__XXX

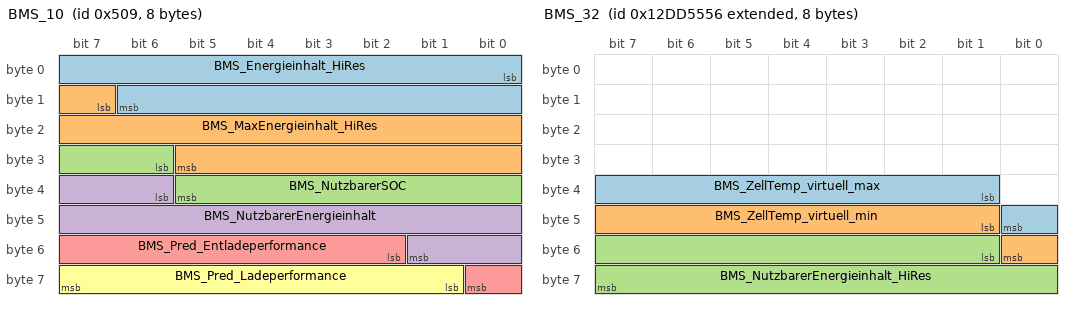
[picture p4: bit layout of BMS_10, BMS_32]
BO_ 1289 BMS_10: 8 Gateway
 SG_ BMS_Energieinhalt_HiRes : 0|15@1+ (4,0) [0|131060] "Unit_WattHour"  Vector__XXX
 SG_ BMS_MaxEnergieinhalt_HiRes : 15|15@1+ (4,0) [0|131060] "Unit_WattHour"  Vector__XXX
 SG_ BMS_NutzbarerSOC : 30|8@1+ (0.5,0) [0.0|100.0] "Unit_PerCent"  Kombi,Kombi_LB,Kombi_PAG
 SG_ BMS_NutzbarerEnergieinhalt : 38|12@1+ (25,0) [0|102325] "Unit_WattHour"  Kombi,Kombi_LB,Kombi_PAG
 SG_ BMS_Pred_Entladeperformance : 50|7@1+ (1,0) [0|100] "Unit_PerCent"  Vector__XXX
 SG_ BMS_Pred_Ladeperformance : 57|7@1+ (1,0) [0|100] "Unit_PerCent"  Vector__XXX

BO_ 2463978838 BMS_32: 8 Gateway
 SG_ BMS_ZellTemp_virtuell_max : 33|8@1+ (0.5,-40) [-40.0|86.0] "Unit_DegreCelsi"  Vector__XXX
 SG_ BMS_ZellTemp_virtuell_min : 41|8@1+ (0.5,-40) [-40.0|86.0] "Unit_DegreCelsi"  Vector__XXX
 SG_ BMS_NutzbarerEnergieinhalt_HiRes : 49|15@1+ (4,-4) [0|131056] "Unit_WattHour"  Kombi,Kombi_LB

BO_ 2589284070 BMS_36: 8 Gateway
 SG_ BMS_ExtLadeleistung : 12|10@1+ (1,0) [0|818] "Unit_KiloWatt"  Kombi,Kombi_PAG

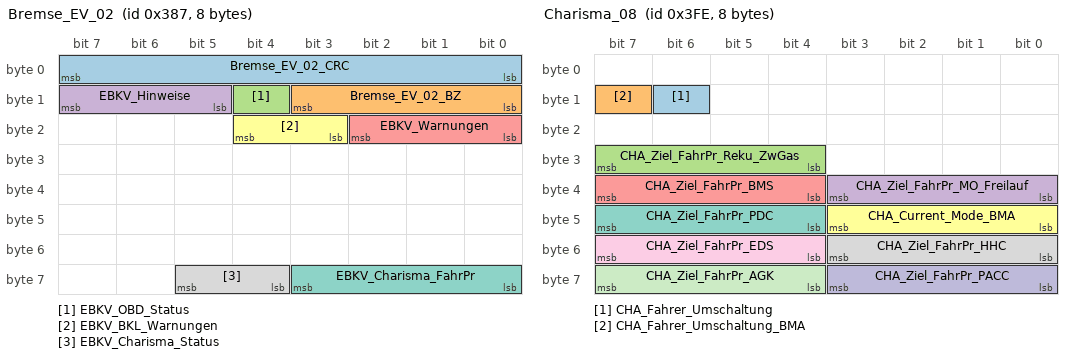
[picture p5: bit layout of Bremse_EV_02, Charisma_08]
BO_ 903 Bremse_EV_02: 8 Gateway
 SG_ Bremse_EV_02_CRC : 0|8@1+ (1,0) [0|255] ""  Kombi,Kombi_LB,Kombi_PAG
 SG_ Bremse_EV_02_BZ : 8|4@1+ (1,0) [0|15] ""  Kombi,Kombi_LB,Kombi_PAG
 SG_ EBKV_OBD_Status : 12|1@1+ (1.0,0.0) [0.0|1] ""  Vector__XXX
 SG_ EBKV_Hinweise : 13|3@1+ (1.0,0.0) [0.0|7] ""  Kombi,Kombi_LB,Kombi_PAG
 SG_ EBKV_Warnungen : 16|3@1+ (1.0,0.0) [0.0|7] ""  Kombi,Kombi_LB,Kombi_PAG
 SG_ EBKV_BKL_Warnungen : 19|2@1+ (1.0,0.0) [0.0|3] ""  Kombi,Kombi_LB,Kombi_PAG
 SG_ EBKV_Charisma_FahrPr : 56|4@1+ (1.0,0.0) [0.0|15] ""  Vector__XXX
 SG_ EBKV_Charisma_Status : 60|2@1+ (1.0,0.0) [0.0|3] ""  Vector__XXX

BO_ 902 Charisma_03: 8 Gateway
 SG_ CHA_Drive_Select1_LED : 10|2@1+ (1.0,0.0) [0.0|3] ""  Vector__XXX
 SG_ CHA_Eco_Charisma_LED : 12|2@1+ (1.0,0.0) [0.0|3] ""  Vector__XXX
 SG_ CHA_Fahrer_Umschaltung : 14|1@1+ (1.0,0.0) [0.0|1] ""  Vector__XXX
 SG_ CHA_EV_LED : 15|1@1+ (1.0,0.0) [0.0|1] ""  Vector__XXX
 SG_ CHA_Ziel_FahrPr_AMB : 16|4@1+ (1.0,0.0) [0.0|15] ""  Vector__XXX
 SG_ CHA_Ziel_FahrPr_IVB : 20|4@1+ (1.0,0.0) [0.0|15] ""  Vector__XXX
 SG_ CHA_Kombi_Texte : 24|4@1+ (1.0,0.0) [0.0|15] ""  Kombi,Kombi_LB,Kombi_PAG
 SG_ CHA_Ziel_FahrPr_KL : 28|4@1+ (1.0,0.0) [0.0|15] ""  Vector__XXX
 SG_ CHA_Ziel_FahrPr_HSP : 32|4@1+ (1.0,0.0) [0.0|15] ""  Vector__XXX
 SG_ CHA_Drehschalter_Istmodus : 36|4@1+ (1.0,0.0) [0.0|15] ""  Vector__XXX
 SG_ CHA_Ziel_FahrPr_RWB : 40|4@1+ (1.0,0.0) [0.0|15] ""  Kombi,Kombi_LB,Kombi_PAG
 SG_ CHA_Ziel_FahrPr_03_01 : 44|4@1+ (1.0,0.0) [0.0|15] ""  Vector__XXX
 SG_ CHA_Ziel_FahrPr_03_02 : 48|4@1+ (1.0,0.0) [0.0|15] ""  Vector__XXX
 SG_ CHA_Current_Mode : 52|4@1+ (1.0,0.0) [0.0|15] ""  HUD,Kombi,Kombi_LB,Kombi_PAG
 SG_ CHA_Charge_LED : 57|1@1+ (1.0,0.0) [0.0|1] ""  Vector__XXX
 SG_ CHA_Offroad_LED : 58|2@1+ (1.0,0.0) [0.0|3] ""  Kombi,Kombi_LB,Kombi_PAG
 SG_ CHA_Kombi_Texte_02 : 60|4@1+ (1.0,0.0) [0.0|15] ""  Kombi,Kombi_LB,Kombi_PAG

BO_ 1022 Charisma_08: 8 Gateway
 SG_ CHA_Fahrer_Umschaltung : 14|1@1+ (1.0,0.0) [0.0|1] ""  Vector__XXX
 SG_ CHA_Fahrer_Umschaltung_BMA : 15|1@1+ (1.0,0.0) [0.0|1] ""  Vector__XXX
 SG_ CHA_Ziel_FahrPr_Reku_ZwGas : 28|4@1+ (1.0,0.0) [0.0|15] ""  Vector__XXX
 SG_ CHA_Ziel_FahrPr_MO_Freilauf : 32|4@1+ (1.0,0.0) [0.0|15] ""  Vector__XXX
 SG_ CHA_Ziel_FahrPr_BMS : 36|4@1+ (1.0,0.0) [0.0|15] ""  Vector__XXX
 SG_ CHA_Current_Mode_BMA : 40|4@1+ (1.0,0.0) [0.0|15] ""  Kombi,Kombi_LB,Kombi_PAG
 SG_ CHA_Ziel_FahrPr_PDC : 44|4@1+ (1.0,0.0) [0.0|15] ""  Vector__XXX
 SG_ CHA_Ziel_FahrPr_HHC : 48|4@1+ (1.0,0.0) [0.0|15] ""  Vector__XXX
 SG_ CHA_Ziel_FahrPr_EDS : 52|4@1+ (1.0,0.0) [0.0|15] ""  Vector__XXX
 SG_ CHA_Ziel_FahrPr_PACC : 56|4@1+ (1.0,0.0) [0.0|15] ""  Vector__XXX
 SG_ CHA_Ziel_FahrPr_AGK : 60|4@1+ (1.0,0.0) [0.0|15] ""  Vector__XXX

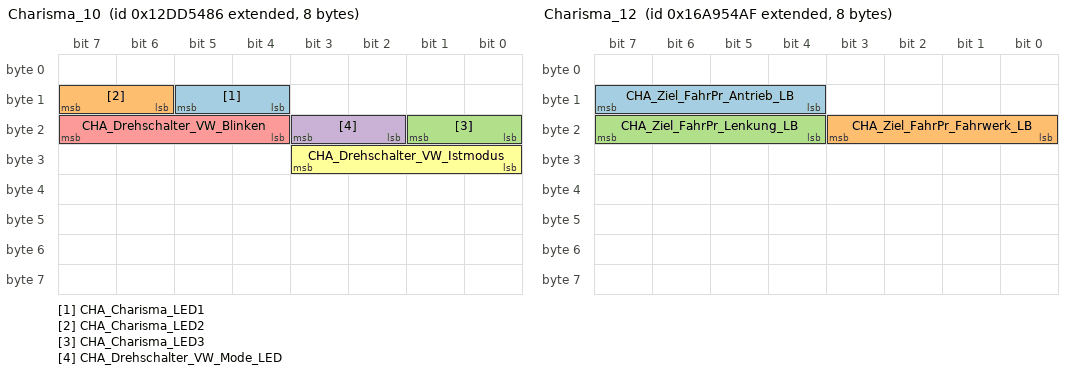
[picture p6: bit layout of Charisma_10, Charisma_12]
BO_ 2463978630 Charisma_10: 8 Gateway
 SG_ CHA_Charisma_LED1 : 12|2@1+ (1.0,0.0) [0.0|3] ""  Kombi
 SG_ CHA_Charisma_LED2 : 14|2@1+ (1.0,0.0) [0.0|3] ""  Kombi
 SG_ CHA_Charisma_LED3 : 16|2@1+ (1.0,0.0) [0.0|3] ""  Kombi
 SG_ CHA_Drehschalter_VW_Mode_LED : 18|2@1+ (1.0,0.0) [0.0|3] ""  Kombi
 SG_ CHA_Drehschalter_VW_Blinken : 20|4@1+ (1.0,0.0) [0.0|15] ""  Kombi
 SG_ CHA_Drehschalter_VW_Istmodus : 24|4@1+ (1.0,0.0) [0.0|15] ""  Kombi

BO_ 2527679663 Charisma_12: 8 Gateway
 SG_ CHA_Ziel_FahrPr_Antrieb_LB : 12|4@1+ (1.0,0.0) [0.0|15] ""  Kombi,Kombi_LB
 SG_ CHA_Ziel_FahrPr_Fahrwerk_LB : 16|4@1+ (1.0,0.0) [0.0|15] ""  Kombi,Kombi_LB
 SG_ CHA_Ziel_FahrPr_Lenkung_LB : 20|4@1+ (1.0,0.0) [0.0|15] ""  Kombi,Kombi_LB

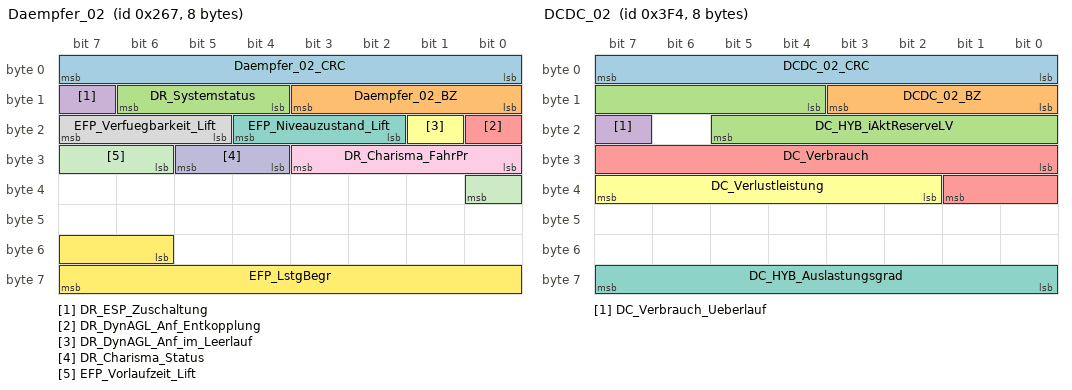
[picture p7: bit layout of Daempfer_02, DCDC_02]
BO_ 615 Daempfer_02: 8 Gateway
 SG_ Daempfer_02_CRC : 0|8@1+ (1,0) [0|255] ""  Vector__XXX
 SG_ Daempfer_02_BZ : 8|4@1+ (1,0) [0|15] ""  Vector__XXX
 SG_ DR_Systemstatus : 12|3@1+ (1.0,0.0) [0.0|7] ""  Kombi_LB
 SG_ DR_ESP_Zuschaltung : 15|1@1+ (1.0,0.0) [0.0|1] ""  Vector__XXX
 SG_ DR_DynAGL_Anf_Entkopplung : 16|1@1+ (1.0,0.0) [0.0|1] ""  Vector__XXX
 SG_ DR_DynAGL_Anf_im_Leerlauf : 17|1@1+ (1.0,0.0) [0.0|1] ""  Vector__XXX
 SG_ EFP_Niveauzustand_Lift : 18|3@1+ (1.0,0.0) [0.0|7] ""  Vector__XXX
 SG_ EFP_Verfuegbarkeit_Lift : 21|3@1+ (1.0,0.0) [0.0|7] ""  Vector__XXX
 SG_ DR_Charisma_FahrPr : 24|4@1+ (1.0,0.0) [0.0|15] ""  Vector__XXX
 SG_ DR_Charisma_Status : 28|2@1+ (1.0,0.0) [0.0|3] ""  Vector__XXX
 SG_ EFP_Vorlaufzeit_Lift : 30|3@1+ (1,3) [3|8] "Unit_Secon"  Vector__XXX
 SG_ EFP_LstgBegr : 54|10@1+ (1,0) [0|1000] "Unit_KiloWatt"  Vector__XXX

BO_ 1012 DCDC_02: 8 Gateway
 SG_ DCDC_02_CRC : 0|8@1+ (1,0) [0|255] ""  Vector__XXX
 SG_ DCDC_02_BZ : 8|4@1+ (1,0) [0|15] ""  Vector__XXX
 SG_ DC_HYB_iAktReserveLV : 12|10@1+ (1,-511) [-511|510] "Unit_Amper"  Vector__XXX
 SG_ DC_Verbrauch_Ueberlauf : 23|1@1+ (1.0,0.0) [0.0|1] ""  Kombi,Kombi_LB,Kombi_PAG
 SG_ DC_Verbrauch : 24|10@1+ (1,0) [0|1023] "Unit_WattSecond"  Kombi,Kombi_LB,Kombi_PAG
 SG_ DC_Verlustleistung : 34|6@1+ (5,0) [0|305] "Unit_Watt"  Vector__XXX
 SG_ DC_HYB_Auslastungsgrad : 56|8@1+ (0.4,0) [0.0|100.0] "Unit_PerCent"  Vector__XXX

BO_ 2617039360 DEV_HUD_Resp_00: 8 HUD
 SG_ DEV_HUD_Resp_00_Data : 0|64@1+ (1.0,0.0) [0.0|18446744073709551615] ""  Vector__XXX

BO_ 2617039615 DEV_HUD_Resp_FF: 8 HUD
 SG_ DEV_HUD_Resp_FF_Data : 0|64@1+ (1.0,0.0) [0.0|18446744073709551615] ""  Vector__XXX

BO_ 2617025024 DEV_Kombi_Resp_00: 8 Kombi
 SG_ DEV_Kombi_Resp_00_Data : 0|64@1+ (1.0,0.0) [0.0|18446744073709551615] ""  Vector__XXX

BO_ 2617025279 DEV_Kombi_Resp_FF: 8 Kombi
 SG_ DEV_Kombi_Resp_FF_Data : 0|64@1+ (1.0,0.0) [0.0|18446744073709551615] ""  Vector__XXX

BO_ 2617154048 DEV_Waehlhebel_Resp_00: 8 CGS
 SG_ DEV_Waehlhebel_Resp_00_Data : 0|64@1+ (1.0,0.0) [0.0|18446744073709551615] ""  Vector__XXX

BO_ 2617154303 DEV_Waehlhebel_Resp_FF: 8 CGS
 SG_ DEV_Waehlhebel_Resp_FF_Data : 0|64@1+ (1.0,0.0) [0.0|18446744073709551615] ""  Vector__XXX

BO_ 2549880747 DIA_SAAM_Req: 8 Gateway
 SG_ DIA_SAAM_Req_Data : 0|64@1+ (1.0,0.0) [0.0|18446744073709551615] ""  Waehlhebel_SB

BO_ 2550011819 DIA_SAAM_Resp: 8 Waehlhebel_SB
 SG_ DIA_SAAM_Resp_Data : 0|64@1+ (1.0,0.0) [0.0|18446744073709551615] ""  Gateway,Gateway_PAG

BO_ 2549880434 DIA_UHR_Req: 8 Gateway
 SG_ DIA_UHR_Req_Data : 0|64@1+ (1.0,0.0) [0.0|18446744073709551615] ""  Kombi_PAG

BO_ 2550011506 DIA_UHR_Resp: 8 Kombi_PAG
 SG_ DIA_UHR_Resp_Data : 0|64@1+ (1.0,0.0) [0.0|18446744073709551615] ""  Gateway,Gateway_PAG

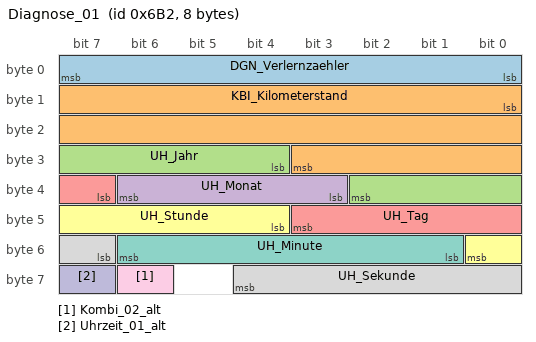
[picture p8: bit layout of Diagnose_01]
BO_ 1714 Diagnose_01: 8 Gateway
 SG_ DGN_Verlernzaehler : 0|8@1+ (1,0) [0|254] ""  CGS,HUD,Kombi,Kombi_LB,Kombi_PAG,Waehlhebel_SB
 SG_ KBI_Kilometerstand : 8|20@1+ (1,0) [0|1048573] "Unit_KiloMeter"  CGS,HUD,Kombi,Kombi_LB,Kombi_PAG,Waehlhebel_SB
 SG_ UH_Jahr : 28|7@1+ (1,2000) [2000|2127] "Unit_Year"  CGS,HUD,Kombi,Kombi_LB,Kombi_PAG,Waehlhebel_SB
 SG_ UH_Monat : 35|4@1+ (1,0) [1|12] "Unit_Month"  CGS,HUD,Kombi,Kombi_LB,Kombi_PAG,Waehlhebel_SB
 SG_ UH_Tag : 39|5@1+ (1,0) [1|31] "Unit_Day"  CGS,HUD,Kombi,Kombi_LB,Kombi_PAG,Waehlhebel_SB
 SG_ UH_Stunde : 44|5@1+ (1,0) [0|23] "Unit_Hours"  CGS,HUD,Kombi,Kombi_LB,Kombi_PAG,Waehlhebel_SB
 SG_ UH_Minute : 49|6@1+ (1,0) [0|59] "Unit_Minut"  CGS,HUD,Kombi,Kombi_LB,Kombi_PAG,Waehlhebel_SB
 SG_ UH_Sekunde : 55|6@1+ (1,0) [0|59] "Unit_Secon"  CGS,HUD,Kombi,Kombi_LB,Kombi_PAG,Waehlhebel_SB
 SG_ Kombi_02_alt : 62|1@1+ (1.0,0.0) [0.0|1] ""  Vector__XXX
 SG_ Uhrzeit_01_alt : 63|1@1+ (1.0,0.0) [0.0|1] ""  Vector__XXX

BO_TX_BU_ 2536703233 :Kombi,Kombi_LB,Kombi_PAG;
BO_TX_BU_ 2536703248 :Gateway,Gateway_PAG;
BO_TX_BU_ 2536722192 :Gateway,Gateway_PAG;
BO_TX_BU_ 2536714496 :Kombi,Kombi_PAG;
BO_TX_BU_ 2536714497 :Kombi,Kombi_PAG;
BO_TX_BU_ 2536714512 :Gateway,Gateway_PAG;
BO_TX_BU_ 2536714513 :Gateway,Gateway_PAG;
BO_TX_BU_ 2536720400 :Gateway,Gateway_PAG;
BO_TX_BU_ 2536711426 :Kombi,Kombi_LB,Kombi_PAG;
BO_TX_BU_ 2536711440 :Gateway,Gateway_PAG;
BO_TX_BU_ 2536705792 :Gateway,Gateway_PAG;
BO_TX_BU_ 2536705793 :Gateway,Gateway_PAG;
BO_TX_BU_ 2536705794 :Gateway,Gateway_PAG;
BO_TX_BU_ 2536705795 :Gateway,Gateway_PAG;
BO_TX_BU_ 2536705808 :Kombi,Kombi_LB,Kombi_PAG;
BO_TX_BU_ 2536710912 :Kombi,Kombi_LB;
BO_TX_BU_ 2536711680 :Gateway,Gateway_PAG;
BO_TX_BU_ 2536707841 :Kombi,Kombi_LB,Kombi_PAG;
BO_TX_BU_ 2536707856 :Gateway,Gateway_PAG;
BO_TX_BU_ 2536767280 :Gateway,Gateway_PAG,HUD,Kombi,Kombi_LB,Kombi_PAG;
BO_TX_BU_ 2536719616 :Gateway,Gateway_PAG;
BO_TX_BU_ 2536719617 :Gateway,Gateway_PAG;
BO_TX_BU_ 2536719632 :Kombi,Kombi_PAG;
BO_TX_BU_ 2536705282 :Kombi,Kombi_LB,Kombi_PAG;
BO_TX_BU_ 2536705296 :Gateway,Gateway_PAG;
BO_TX_BU_ 2536706816 :Gateway,Gateway_PAG;
BO_TX_BU_ 2536706817 :Gateway,Gateway_PAG;
BO_TX_BU_ 2536706818 :Gateway,Gateway_PAG;
BO_TX_BU_ 2536706819 :Gateway,Gateway_PAG;
BO_TX_BU_ 2536706832 :Kombi,Kombi_LB,Kombi_PAG;
BO_TX_BU_ 2536702976 :Gateway,Gateway_PAG;
BO_TX_BU_ 2536702977 :Kombi,Kombi_PAG;
BO_TX_BU_ 2536702978 :Gateway,Gateway_PAG;
BO_TX_BU_ 2536709121 :Kombi,Kombi_LB,Kombi_PAG;
BO_TX_BU_ 2536709136 :Gateway,Gateway_PAG;
BO_TX_BU_ 2536722945 :Kombi,Kombi_LB;
BO_TX_BU_ 2536722960 :Gateway,Gateway_PAG;
BO_TX_BU_ 2536708353 :Kombi,Kombi_LB,Kombi_PAG;
BO_TX_BU_ 2536708368 :Gateway,Gateway_PAG;
BO_TX_BU_ 2536732672 :Gateway,Gateway_PAG;
BO_TX_BU_ 2536715264 :Kombi,Kombi_PAG;
BO_TX_BU_ 2536715280 :Gateway,Gateway_PAG;
BO_TX_BU_ 2536714752 :Kombi,Kombi_PAG;
BO_TX_BU_ 2536714753 :Kombi,Kombi_PAG;
BO_TX_BU_ 2536714768 :Gateway,Gateway_PAG;
BO_TX_BU_ 2536714769 :Gateway,Gateway_PAG;
BO_TX_BU_ 2536708112 :Gateway,Gateway_PAG;
BO_TX_BU_ 2536712704 :Kombi,Kombi_PAG;
BO_TX_BU_ 2536712720 :Gateway,Gateway_PAG;
BO_TX_BU_ 2536702736 :Gateway,Gateway_PAG;
BO_TX_BU_ 2536703745 :Kombi,Kombi_LB,Kombi_PAG;
BO_TX_BU_ 2536703760 :Gateway,Gateway_PAG;
BO_TX_BU_ 2536709889 :Kombi,Kombi_LB;
BO_TX_BU_ 2536709904 :Gateway,Gateway_PAG;
BO_TX_BU_ 2536719872 :Kombi,Kombi_PAG;
BO_TX_BU_ 2536719888 :Gateway,Gateway_PAG;
BO_TX_BU_ 2536706560 :Gateway,Gateway_PAG;
BO_TX_BU_ 2536706561 :Gateway,Gateway_PAG;
BO_TX_BU_ 2536706562 :Gateway,Gateway_PAG;
BO_TX_BU_ 2536706576 :Kombi,Kombi_LB,Kombi_PAG;
BO_TX_BU_ 2536720896 :Gateway,Gateway_PAG;
BO_TX_BU_ 2536703489 :Kombi,Kombi_PAG;
BO_TX_BU_ 2536703504 :Gateway,Gateway_PAG;
BO_TX_BU_ 2536708609 :Kombi,Kombi_LB;
BO_TX_BU_ 2536708624 :Gateway,Gateway_PAG;
BO_TX_BU_ 2536712448 :Kombi,Kombi_PAG;
BO_TX_BU_ 2536712464 :Gateway,Gateway_PAG;
BO_TX_BU_ 2536712465 :Gateway,Gateway_PAG;
BO_TX_BU_ 2536712192 :Kombi,Kombi_PAG;
BO_TX_BU_ 2536712193 :Kombi,Kombi_PAG;
BO_TX_BU_ 2536712208 :Gateway,Gateway_PAG;
BO_TX_BU_ 2536712209 :Gateway,Gateway_PAG;
BO_TX_BU_ 2536711169 :Kombi,Kombi_LB;
BO_TX_BU_ 2536711184 :Gateway,Gateway_PAG;
BO_TX_BU_ 2536706304 :Gateway,Gateway_PAG;
BO_TX_BU_ 2536706305 :Gateway,Gateway_PAG;
BO_TX_BU_ 2536706306 :Gateway,Gateway_PAG;
BO_TX_BU_ 2536706308 :Gateway,Gateway_PAG;
BO_TX_BU_ 2536706309 :Gateway,Gateway_PAG;
BO_TX_BU_ 2536706310 :Gateway,Gateway_PAG;
BO_TX_BU_ 2536706320 :Kombi,Kombi_LB,Kombi_PAG;
BO_TX_BU_ 2536710401 :Kombi,Kombi_LB,Kombi_PAG;
BO_TX_BU_ 2536710416 :Gateway,Gateway_PAG;
BO_TX_BU_ 1615 :Gateway,Gateway_PAG;
BO_TX_BU_ 1626 :Gateway,Gateway_PAG;
BO_TX_BU_ 672 :Gateway,Gateway_PAG;
BO_TX_BU_ 2527679637 :Gateway,Gateway_PAG;
BO_TX_BU_ 2463978607 :Gateway,Gateway_PAG;
BO_TX_BU_ 870 :Gateway,Gateway_PAG;
BO_TX_BU_ 868 :Gateway,Gateway_PAG;
BO_TX_BU_ 687 :Gateway,Gateway_PAG;
BO_TX_BU_ 1438 :Gateway,Gateway_PAG;
BO_TX_BU_ 1482 :Gateway,Gateway_PAG;
BO_TX_BU_ 1289 :Gateway,Gateway_PAG;
BO_TX_BU_ 2463978838 :Gateway,Gateway_PAG;
BO_TX_BU_ 2589284070 :Gateway,Gateway_PAG;
BO_TX_BU_ 903 :Gateway,Gateway_PAG;
BO_TX_BU_ 902 :Gateway,Gateway_PAG;
BO_TX_BU_ 1022 :Gateway,Gateway_PAG;
BO_TX_BU_ 2463978630 :Gateway,Gateway_PAG;
BO_TX_BU_ 2527679663 :Gateway,Gateway_PAG;
BO_TX_BU_ 615 :Gateway,Gateway_PAG;
BO_TX_BU_ 1012 :Gateway,Gateway_PAG;
BO_TX_BU_ 2617025024 :Kombi,Kombi_LB,Kombi_PAG;
BO_TX_BU_ 2617025279 :Kombi,Kombi_LB,Kombi_PAG;
BO_TX_BU_ 2617154048 :CGS,Waehlhebel_SB;
BO_TX_BU_ 2617154303 :CGS,Waehlhebel_SB;
BO_TX_BU_ 2549880747 :Gateway,Gateway_PAG;
BO_TX_BU_ 2549880434 :Gateway,Gateway_PAG;
BO_TX_BU_ 1714 :Gateway,Gateway_PAG;
CM_ BO_ 2536711169 "CAN message for location on I-CAN MLBevo.
BAP connection between BCM and IC (ASG)";
CM_ BO_ 2536711170 "CAN message for location on I-CAN MLBevo.
BAP connection between BCM and IC (ASG)";
CM_ BO_ 870 "Nur die Kombination des statischen und toggelnden Signals ergibt den Blinktakt für die Hell & Dunkelphase";
CM_ BO_ 868 "Botschaft wird vom BCM1 gesendet, wenn BCM2 ausfällt (Fail-Safe) und die Funktion 'Blinken' aktiv ist
";
CM_ BO_ 903 "Schnittstelle EBKV - Kombi";
CM_ BO_ 902 "ab MQB 7.2.1";
CM_ BO_ 2527679663 "Charisma-Signale für Tamburo in Lambo Urus";
CM_ BO_ 2549880747 "DK2F Flash Diagnosezugriff";
CM_ BO_ 2550011819 "DK2F Flash Diagnosezugriff";
CM_ BO_ 2549880434 "LIN Flashen UHR (DK2F)";
CM_ BO_ 2550011506 "LIN Flashen UHR (DK2F)";

CM_ SG_ 2463978631 AST_Laengssperre "Information, ob die Längssperren-Taste des AllradSperrenTasters betätigt wurde

Toggeltaste: 
Bei gesperrter Längssperre führt das Aktivieren zu einem Entsperren
Bei entsperrter Längssperre führt das Aktivieren zu einem Sperren

Ein Zustandswechsel ";
CM_ SG_ 2463978631 AST_Low "Information, ob die Low-Taste des AllradSperrenTasters betätigt wurde

Toggeltaste: 
In Low führt das Aktivieren zu einem Schalten nach High
In High führt das Aktivieren zu einem Schalten nach Low

Ein Zustandswechsel wird für mindestens 3Botschafte";
CM_ SG_ 2463978631 AST_Quersperre "Information, ob die Quersperren-Taste des AllradSperrenTasters betätigt wurde

Toggeltaste: 
Bei gesperrter Quersperre führt das Aktivieren zu einem Entsperren
Bei entsperrter Quersperre führt das Aktivieren zu einem Sperren

Ein Zustandswechsel wir";
CM_ SG_ 2463978631 BuA_Charisma_Taste1 "Information, ob die Taste1 des 3-Taster-Moduls für die Funktion Charisma betätigt wurde.";
CM_ SG_ 2463978631 BuA_Charisma_Taste2 "Information, ob die Taste2 des 3-Taster-Moduls für die Funktion Charisma betätigt wurde.";
CM_ SG_ 2463978631 BuA_Charisma_Taste3 "Information, ob die Taste3 des 3-Taster-Moduls für die Funktion Charisma betätigt wurde.";
CM_ SG_ 2463978631 CHA_Drehschalter_VW_defekt "Slave defekt";
CM_ SG_ 2463978631 CHA_Drehschalter_VW_Mode_Taster "Status Mode Taster";
CM_ SG_ 2463978631 CHA_Drehschalter_VW_Modus "Charisma Drehschalter Modus";
CM_ SG_ 2463978631 LDT_Drehschalter_Betaetigt "Status Betätigung LDT Drehschalter";
CM_ SG_ 2463978631 LDT_Drehschalter_Hoch "Tastersignal zum Anheben des Fahrzeugs bei höhenverstellbaren Fahrzeugen";
CM_ SG_ 2463978631 LDT_Drehschalter_Modus "Sollmodus des Luftfederdrehschalters";
CM_ SG_ 2463978631 LDT_Drehschalter_Tief "Tastersignal zum Absenken des Fahrzeugs bei höhenverstellbaren Fahrzeugen";
CM_ SG_ 2463978631 LDT_Sync_Betaetigt "Status Betätigung LDT Sync Taster";

CM_ SG_ 2536722177 BAP_AHC_ASG_02_Header "Automatic Headlamp Setting. Funktion auf zFAS";

CM_ SG_ 2536722192 BAP_AHC_FSG_01_Header "Automatic Headlamp Setting. Funktion auf zFAS";

CM_ SG_ 2536720385 BAP_AWC_ASG_02_Header "AWC Anzeigesteuergerät (ASG BAP Strecke)";

CM_ SG_ 2536720400 BAP_AWC_FSG_01_Header "AWC Funktionssteuergeraet";

CM_ SG_ 2536711429 BAP_BatteryControl_ASG_06_Header "BatteryControl Anzeigesteuergerät Head-Up Display";

CM_ SG_ 2536705796 BAP_BC_ASG_05_Header "BC Anzeigesteuergeraet";

CM_ SG_ 2536705797 BAP_BC_ASG_06_Header "BAP_BC_MFA  Signal für BAP Strecke zum HUD";

CM_ SG_ 2536707841 BAP_Charisma_ASG_02_Header "Charisma2 Anzeigesteuergeraet";

CM_ SG_ 2536707845 BAP_Charisma_ASG_06_Header "Charisma Anzeigesteuergerät Head-Up Display";

CM_ SG_ 2536719616 BAP_DisplayConfig_ASG_01_Header "Display Config Anzeigesteuergeraet";

CM_ SG_ 2536719617 BAP_DisplayConfig_ASG_02_Header "Display Config Anzeigesteuergeraet";

CM_ SG_ 2536719632 BAP_DisplayConfig_FSG_01_Header "Display Konfiguration Funktionssteuergeraet Kombi";

CM_ SG_ 2536706819 BAP_Einheiten_ASG_04_Header "Einheiten Anzeigesteuergeraet";

CM_ SG_ 2536702977 BAP_HUD_ASG_02_Header "HUD Anzeigesteuergeraet";

CM_ SG_ 2536702978 BAP_HUD_ASG_03_Header "HUD Anzeigesteuergeraet 3";

CM_ SG_ 2536722945 BAP_IAA_PSO_ASG_02_Header "BAP Strecke für IAA & PSO
Anzeigesteuergeräte KI";

CM_ SG_ 2536722960 BAP_IAA_PSO_FSG_01_Header "BAP Strecke für IAA & PSO";

CM_ SG_ 2536732672 BAP_LLCC_ASG_01_Header "Longitudinal and lateral control coordinator (LLCC) Anzeigesteuergeraet";

CM_ SG_ 2536732688 BAP_LLCC_FSG_01_Header "Longitudinal and lateral control coordinator (LLCC) Funktionssteuergeraet";

CM_ SG_ 2536712704 BAP_OnlineFunction_ASG_01_Header "OnlineFunctions Anzeigesteuergeraet";

CM_ SG_ 2536712705 BAP_OnlineFunction_ASG_02_Header "OnlineFunctions Anzeigesteuergeraet";

CM_ SG_ 2536712720 BAP_OnlineFunction_FSG_01_Header "OnlineFunctions Funktionssteuergeraet";

CM_ SG_ 2536702723 BAP_ParkHeater_ASG_04_Header "ParkHeater Anzeigesteuergeraet";

CM_ SG_ 2536709889 BAP_RGS_ASG_02_Header "RGS Anzeigesteuergerät Kombi";

CM_ SG_ 2536719872 BAP_SDS_ASG_01_Header "Sprach-Dialog-System Anzeigesteuergeraet";

CM_ SG_ 2536719888 BAP_SDS_FSG_01_Header "Sprach-Dialog-System
Funktionssteuergeraet";

CM_ SG_ 2536706562 BAP_SIA_ASG_03_Header "SIA Anzeigesteuergeraet 3";

CM_ SG_ 2536720896 BAP_Statistics_ASG_01_Header "Statistics Anzeigesteuergeraet";

CM_ SG_ 2536720912 BAP_Statistics_FSG_01_Header "Statistics Funktionssteuergeraet";

CM_ SG_ 2536703489 BAP_SuspensionControl_ASG_02_Hea "SuspensionControl Anzeigesteuergeraet";

CM_ SG_ 2536712448 BAP_Telefon2_ASG_01_Header "MQB AUDI: keine Verwendung im ZR Entry";

CM_ SG_ 2536712449 BAP_Telefon2_ASG_02_Header "Telefon2 Anzeigesteuergeraet
MMI <-> Head-Up Display";

CM_ SG_ 2536712464 BAP_Telefon2_FSG_01_Header "MQB AUDI: keine Verwendung im ZR Entry";

CM_ SG_ 2536712465 BAP_Telefon2_FSG_02_Header "BAP Strecke Telefon zum Kombi";

CM_ SG_ 2536712192 BAP_Telefon_ASG_01_Header "MQB AUDI: keine Verwendung im ZR Entry";

CM_ SG_ 2536712193 BAP_Telefon_ASG_02_Header "MQB AUDI: keine Verwendung im ZR Entry";

CM_ SG_ 2536712194 BAP_Telefon_ASG_03_Header "Telefon Anzeigesteuergeraet
Head-Up";

CM_ SG_ 2536712195 BAP_Telefon_ASG_04_Header "Telefon Anzeigesteuergeraet
MMI<->Head-Up Display";

CM_ SG_ 2536712208 BAP_Telefon_FSG_01_Header "MQB AUDI: keine Verwendung im ZR Entry";

CM_ SG_ 2536712209 BAP_Telefon_FSG_02_Header "MQB AUDI: keine Verwendung im ZR Entry";

CM_ SG_ 2536711169 BAP_TiltAngle_ASG_02_Header "BAP dummy signal used for communication between BCM (FSG) and IC (ASG)";

CM_ SG_ 2536711170 BAP_TiltAngle_ASG_03_Header "BAP_TiltAngle  Signal für BAP Strecke zum HUD";

CM_ SG_ 2536706310 BAP_Uhrzeit_ASG_07_Header "Uhrzeit Anzeigesteuergeraet AWC";

CM_ SG_ 2536706311 BAP_Uhrzeit_ASG_08_Header "Uhrzeit Anzeigesteuergeraet HUD";

CM_ SG_ 1615 BCM1_Hinweis_Lichtnachlauf "Signal dient der Anzeige eines aktiven Lichtnachlaufes beim automatischen Abschalten der Klemme S und Klemme 15. Der Lichtnachlauf wird gestartet, wenn die Klemme 15 bei aktivem Fahrlicht deaktiviert wird.";
CM_ SG_ 1615 BCM1_HUD_Eyeboxposition "Position des Eyebox Drehgebers";
CM_ SG_ 1615 BCM1_HUD_Eyeboxposition_Status "Status Eyebox Drehgeber";
CM_ SG_ 1615 BCM1_HUD_Taster "Status HUD Taster";
CM_ SG_ 1615 BCM1_LDS_Stellung "Das Signal wird vom AFS / LWR Steuergerät empfangen und dient der Verifizierung der Lichtdrehschalterstellung. Intelligente Lichtfunktionen wie dyn. KL und gleitende Leuchtweite (GLW) nur bei LDS = 'AUTO'.";
CM_ SG_ 1615 BCM1_Lichtwarn_Texte "Anforderung von Lichtwarnungen vom BCM1 zum Kombi
MLB: nur Werte 0..2";
CM_ SG_ 1615 BCM1_Spannungs_Anf "Forderung des BCM1-SG's zur Spannungsanhebung.";
CM_ SG_ 1615 BCM1_Status_Ladeanzeige "Leuchtenstatus zur Anzeige von ChargeCheck
Sendeart = Cyclic, Zykluszeit = 100ms anlog des Signals im MQB (Licht_hinten_01/BCM_Status_Ladeanzeige) auf dem ACAN";
CM_ SG_ 1615 BCM1_Stellgroesse_Kl_58s "Rohwert Dimmpoti";
CM_ SG_ 1615 CHA_Drehschalter_Modus "Charisma Drehschalter Modus";
CM_ SG_ 1615 CHA_Kombi_Texte "Anzeige des aktuellen Charisma-Fahrprofiles im Kombi.
Die Texte werden HUT-Spezifisch in einem Schnittstellen-LAH definiert.";
CM_ SG_ 1615 KRH_Stufe_LED_li "Statusmeldung Kopfraumheizung links";
CM_ SG_ 1615 KRH_Stufe_LED_re "Statusmeldung Kopfraumheizung rechts";
CM_ SG_ 1615 LV_Laserlicht_Texte "Anforderung Kombi-Texte bezüglich Laser-Fernlicht";
CM_ SG_ 1615 LV_LED_Scheinwerfer_li_def "Fehlerstatus LED-Scheinwerfer links
";
CM_ SG_ 1615 LV_LED_Scheinwerfer_re_def "Fehlerstatus LED-Scheinwerfer rechts";

CM_ SG_ 1626 APS_Tongeber_defekt "Status APS-Tongeber zur HMI-Ansteuerng der RCTA-Funktion";
CM_ SG_ 1626 BCM1_AFS_Lampe "Ansteuerung der AFS-Fehlermeldung im Kombi";
CM_ SG_ 1626 BCM1_EasyEntry_Status "Status EasyEntry für Lenksäule (wird auch von IVB verwendet)";
CM_ SG_ 1626 BCM1_Fahrlicht_Hinweis "Signal zum Kombi um den Hinweis 'Bitte Fahrlicht einschalten' anzufordern";
CM_ SG_ 1626 BCM1_Hinweis_Lichtnachlauf "Signal dient der Anzeige eines aktiven Lichtnachlaufes beim automatischen Abschalten der Klemme S und Klemme 15. Der Lichtnachlauf wird gestartet, wenn die Klemme 15 bei aktivem Fahrlicht deaktiviert wird.";
CM_ SG_ 1626 BCM1_Kl_15_HW_erkannt "Erkennung Klemme 15 (Hardware) vom BCM1
";
CM_ SG_ 1626 BCM1_Kl_15_Sig_HW_erkannt "Erkennung Klemme 15 Signal (Hardware) vom BCM1";
CM_ SG_ 1626 BCM1_LDS_Stellung "Das Signal wird vom AFS / LWR Steuergerät empfangen und dient der Verifizierung der Lichtdrehschalterstellung. Intelligente Lichtfunktionen wie dyn. KL und gleitende Leuchtweite (GLW) nur bei LDS = 'AUTO'.";
CM_ SG_ 1626 BCM1_Lenksaeule_aktiv "Lenksaeulenverstellung aktiv";
CM_ SG_ 1626 BCM1_Licht_Warn "Lichtwarnung";
CM_ SG_ 1626 BCM1_Lichtwarn_Texte "Anforderung von Lichtwarnungen vom BCM1 zum Kombi
MLB: nur Werte 0..2";
CM_ SG_ 1626 BCM1_MH_Schalter "Motorhaubenkontakt";
CM_ SG_ 1626 BCM1_MH_WIV_Schalter "Bewerteter Motorhaubenkontakt fuer WIV";
CM_ SG_ 1626 BCM1_NV_Taster "BCM1_NV_Taster gibt an, ob der NightVision-Taster im Lichtdrehschalter-Modul aktuell betaetigt wird.";
CM_ SG_ 1626 BCM1_Reisemodus_Texte "Ansteuerung der Reisemodus-Texte im Kombi";
CM_ SG_ 1626 BCM1_Rueckfahrlicht_Schalter "Rückfahrlichtschalter
ab MQB/ MLBevo: Die Ganginformation wird unentprellt übertragen, im AT-Getriebe wird evtl. kurzzeitig der R-Gang angezeigt. Eine Entprellung muß im Empfänger erfolgen (typisch 400ms).";
CM_ SG_ 1626 BCM1_Schluesselsuche_Anf "Anforderung von BCM1 an BCM2:
Schlüsselpolling aktivieren

Nötig bei z.B. aktiviertem Annäherungslicht";
CM_ SG_ 1626 BCM1_St_SW_Diebstahl_links "Signal zur Anzeige, dass der linke Scheinwerfer gestohlen wurde";
CM_ SG_ 1626 BCM1_St_SW_Diebstahl_rechts "Signal zur Anzeige, dass der rechte Scheinwerfer gestohlen wurde";
CM_ SG_ 1626 BCM1_Valet_Parking_Taster "Valet Parking Taster ";
CM_ SG_ 1626 BCM1_Warnblink_Taster "Warnblinktaster";
CM_ SG_ 1626 BCM_Bremsbelag_Sensor "Sensorsignal der Stromschleife  für Bremsbelagverschleiß aktuell, entstört, unbewertet";
CM_ SG_ 1626 BCM_Bremsfluessigkeit_Sensor "Kontaktsignal des Sensorschalters für die Bremsflüssigkeitsreserve aktuell, entstört, unbewertet";
CM_ SG_ 1626 BCM_Eco_Charisma_Taste "Betätigung Taster ECO alias BlueKey oder Charisma";
CM_ SG_ 1626 BCM_HDF_betaetigt "Betätigung Taster für Heckdeckelfernentriegelung in Mittelkonsole";
CM_ SG_ 1626 BCM_Hybrid_StartStopp_Taste "Betaetigung Taster 'Hybrid' oder alternativ Taster 'Start/Stopp Deaktivierung', je nach Verbau";
CM_ SG_ 1626 BCM_Hybrid_StSt_Taste_Fehler "Fehlerflag, wenn Tasterdiagnose im BCM für den StSt-Taster anschlägt.";
CM_ SG_ 1626 BCM_Kuehlmittel_Sensor "Signal der Sensorelektroden für die Kühlmittelreserve aktuell, entstört, bewertet (OK/Mangel)";
CM_ SG_ 1626 BCM_Kuehlmittel_Sensor_02 "Signal der zweiten Sensorelektroden für die Kühlmittelreserve aktuell, entstört, bewertet (OK/Mangel)";
CM_ SG_ 1626 BCM_Offroad_Taste "Betätigung der Offroad-Taste";
CM_ SG_ 1626 BCM_Waschwasser_Sensor "Signal der Sensorelektroden für die Waschwasserreserve aktuell, entstört, bewertet (OK/Mangel)";
CM_ SG_ 1626 Gong_TFL_Umschaltung "Aktivierung / Deaktivierung des TFL per Affengriff wird mit einem Gong im Kombi quittiert.";
CM_ SG_ 1626 ISP_Dimmung_ASP_02 "Dimmwertvorgabe für Aussenspiegel
Es wird 1:1 die Spannung am Innenspiegel nach außen übertragen.";
CM_ SG_ 1626 UGDO_Function_01 "UGDO_Sender = LIN-Slave BCM1
bei Kl.15 AUS wird für 4s noch der letzte Wert gesendet, danach wird der Wert 7 (= Fehler gesendet)";

CM_ SG_ 672 BCM2_Crashfall_erkannt "Crasherkennung BCM2";
CM_ SG_ 672 BCM2_Freigabe_Kofferr_Innenentr "Freigabe Kofferraum-Innenentriegelung (TrunkEntrapment)

Das iEZS prüft als 2. Instanz die Geschwindigkeit und kann die Ansteuerung der Sekundärverriegelung freigeben (FUSI-Anforderungen).
Das Signal muss über eine E2E-Absicherung verfügen.";
CM_ SG_ 672 BCM2_KL15_Absch_FT "Signalisierung, dass die KL15 über das Verlassen des Fahrzeuges deaktiviert wurde (über Fahrertürtrigger).";
CM_ SG_ 672 BCM2_P_verriegelt "Nicht plausibilisiertes Rohsignal des P-Verriegeltschalters vom Wählhebel zur exklusiven Nutzung für Getriebesteuergeräte:
";
CM_ SG_ 672 BCM2_Quittierung_Warnton_aktiv "Quittierungs-/Warnton Sounder/Einfachhorn aktiv

Info:
- Ausgelöst durch akustische Rückmeldung der Zentralverriegelung
- Aussenwarnung KlSt
- Akustische Rückmeldung bei offenem Alarmkontakt 
- etc.";
CM_ SG_ 672 BCM2_SST_gedrueckt "Betätigung Start-Stop-Taster (Kessy-Fahrzeug)";
CM_ SG_ 672 BCM2_T_Deckel_Vorne "Taster Deckel vorne betätigt";
CM_ SG_ 672 BCM2_TrunkEntrapment_Warn "Das Signal triggert eine Warnmeldung im Kombi zur Anzeige von diagnostizierten schleichenden Fehlern an den Aktoren oder Sensoren von TrunkEntrapment.";
CM_ SG_ 672 BCM2_Unterdr_Zuendungsmeldung "Bei aktivem Signal soll die Zündungsmeldung durch das Kombi unterdrückt werden.";
CM_ SG_ 672 BCM_02_BZ "4bit Botschaftszaehler; wird in jeder Sendebotschaft inkrementiert";
CM_ SG_ 672 BCM_02_CRC "Für MLB:
'Berechnung siehe Lastenheft 'Kommunikationsabsicherung für FlexRay und CAN''

Ab MQB und MLBevo:
'Berechnung siehe Lastenheft 'End-to-End Kommunikationsabsicherung''

Endwerte siehe Begleitdokument 'S-PDU Kennungsfolgen'
";
CM_ SG_ 672 BCM_Anf_Aussenwarnung "Anforderung einer akustischen Aussenwarnung über Hupe an das BCM1";
CM_ SG_ 672 BCM_Aussenwarnung_Konfig "Konfigurationsbyte für die Aussenwarnung
0: Anforderungssignal wird 1:1 übernommen
1..6: Anzahl der Warntöne
7: Sequenz des BCM1 wird solange wiederholt, wie das Anforderungssignal ansteht ";
CM_ SG_ 672 BCM_Handbremse_Hinweis "Infotext fuer das Kombiinstrument zur Oeffnung der elektr. Heckklappe.";
CM_ SG_ 672 BCM_RLU_Wakeup_Anforderung "Anforderung an MIB das Telefonmodul zu aktivieren. Funktion Remote Lock Unlock";
CM_ SG_ 672 BCM_ValetTaster_Fkts_LED "Im MQB beschreibt das Signal nur den Zustand der Funktion Valet Parking (aktiv/ inaktiv)
Im MLBevo wird über das Signal zusätzlich die ValetTaster_Fkts_LED (an/ aus) gesteuert";
CM_ SG_ 672 BCM_Waehlhebel_P_Hinweis "Infotext NAR für die Vorbedingung 'Waehlhebel in P' für Öffnen der Heckklappe über den Fahrerrauminnentaster.";
CM_ SG_ 672 FA_Hoehenwert_HL_01 "Aktueller Höhenwert (Rohwerte) Hinten Links; ungefiltertes Signal
Einheit, Offset und Faktor sind abhänig von 'FA_Hoehenwert_kalibriert'";
CM_ SG_ 672 FA_Hoehenwert_VL_01 "Aktueller Höhenwert (Rohwerte) Vorne Links; ungefiltertes Signal
Einheit, Offset und Faktor sind abhänig von 'FA_Hoehenwert_kalibriert'";
CM_ SG_ 672 FSH_LED "LED Ansteuerung Frontscheibenheizung";
CM_ SG_ 672 Heckrollo_Privacy_aktiv "Anzeige einer aktivierten  Privacy Rollo Funktion";
CM_ SG_ 672 Heckrollo_Verfahrrichtung "Anzeige der aktuellen Heckrolloverfahrrichtung oder der erreichten Endlage.";
CM_ SG_ 672 Heckwischer_Status "Diagnosestatus des Heckwischerausgangs";
CM_ SG_ 672 HSH_LED "LED Ansteuerung Heckscheibenheizung";
CM_ SG_ 672 Niveausensor_HL_verbaut "Signal wird gesetzt, wenn Niveausensor_hinten codiert wird.";
CM_ SG_ 672 Niveausensor_VL_verbaut "Signal wird gesetzt, wenn Niveausensor_vorne codiert wird.";
CM_ SG_ 672 Remote_Rollo_HBFS_hoch "Anforderung für Seitenrollo HBFS in Richtung hoch zu verfahren";
CM_ SG_ 672 Remote_Rollo_HBFS_tief "Anforderung für Seitenrollo HBFS in Richtung tief zu verfahren";
CM_ SG_ 672 Remote_Rollo_HFS_hoch "Anforderung für Seitenrollo HFS in Richtung hoch zu verfahren";
CM_ SG_ 672 Remote_Rollo_HFS_tief "Anforderung für Seitenrollo HFS in Richtung tief zu verfahren";
CM_ SG_ 672 ZZH_Endlage_oben "obere Endlagenerkennung ZZH
";
CM_ SG_ 672 ZZH_Endlage_unplausibel "Erkennungung unplausible Endlage ZZH
";
CM_ SG_ 672 ZZH_Endlage_unten "untere Endlagenerkennung ZZH
";

CM_ SG_ 2527679637 BCM_LTM_Allwetterl_Status "Allwetterlicht Status zur Anzeige im Allwetterlicht-PopUp";
CM_ SG_ 2527679637 BCM_LTM_Nebell_Status "Nebellicht Status zur Anzeige im Nebellicht-PopUp";
CM_ SG_ 2527679637 BCM_LTM_Nebelschluss_Status "Nebelschlusslicht Status zur Anzeige im Nebelschlusslicht-PopUp";
CM_ SG_ 2527679637 BCM_LTM_PopUp_Anf "Anforderung der entsprechenden Anzeige im Kombi bei Aussenlichtsteuerung über LTM (LichtTastenModul)";
CM_ SG_ 2527679637 BCM_LTM_PopUp_Inhalt "Definition Inhalt des PopUps zur Aussenlichtbedienung";
CM_ SG_ 2527679637 BCM_LTM_PopUp_Status "Auswahl der aktiven Aussenlichtfunktion im LTM PopUp";
CM_ SG_ 2527679637 BCM_LTM_PopUp_Texte "Anforderung Kombi-Texte bei Bedienung Aussenlicht über LTM (LichtTastenModul)";
CM_ SG_ 2527679637 CPD_Warnung "Ansteuerung einer Warnung im Kombi/ iID mit Ton oder ohne Ton durch die Fkt. ChildPresenceDetection";

CM_ SG_ 2463978607 BCM_RGB_Blau "Farbanteil 'Blau'";
CM_ SG_ 2463978607 BCM_RGB_Gruen "Farbanteil 'Grün'";
CM_ SG_ 2463978607 BCM_RGB_Rot "Farbanteil 'Rot'";

CM_ SG_ 870 Blinken_li_Fzg_Takt "Fzg-Takt Blinker links

";
CM_ SG_ 870 Blinken_li_Kombi_Takt "Kombi-Takt Blinker links

";
CM_ SG_ 870 Blinken_re_Fzg_Takt "Fzg-Takt Blinker rechts

";
CM_ SG_ 870 Blinken_re_Kombi_Takt "Kombi-Takt Blinker rechts

";
CM_ SG_ 870 BM_Autobahn "Status Autobahnblinken
";
CM_ SG_ 870 BM_Crash "Status Crashblinken
";
CM_ SG_ 870 BM_DWA_Alarm "Status DWA-Alarmblinken
";
CM_ SG_ 870 BM_DWA_ein "Status Quittierungsblinken DWA";
CM_ SG_ 870 BM_GDO "Blinken bei UGDO anlernen

";
CM_ SG_ 870 BM_HD_Oeffnung_angelernt "HD_Rueckmeld_prog eine Blinkerquittierung wird beim BCM2 angefordert.
Wenn die Geschwindigkeit kleiner einer vorgegebenen Schwelle (default 2km/h) ist wird das Signal BM_HD_Öffnung_angelernt versendet und die Blinkerquittierung ausgelöst";
CM_ SG_ 870 BM_links "Richtungsblinken links

";
CM_ SG_ 870 BM_NBA_n_codiert_n_aktiv "Notbremsanzeige nicht codiert/nicht aktiv (Fehler)";
CM_ SG_ 870 BM_NBA_Status "Notbremsanzeige Status nicht aktiv / BRL Dunkelphase / BRL Hellphase";
CM_ SG_ 870 BM_Not_Bremsung "Das Signal BM_Not_Bremsung  zeigt an,  ob ein Warnblinken aufgrund einer vom Bremssystem signalisierten Notbremsung aktiv ist.";
CM_ SG_ 870 BM_Panik "Panikblinken
";
CM_ SG_ 870 BM_PiloPa "Quittierungsblinken bei pilotierten Parkvorgängen";
CM_ SG_ 870 BM_Recas "Blinkermodus RECAS  (RearEndCollisionAlertSignal)";
CM_ SG_ 870 BM_rechts "Richtungsblinken rechts

";
CM_ SG_ 870 BM_Rollenmodus_Blinken "Das Signal wird statisch gesetzt, wenn die Blinkerart Rollenmodus_Blinken aktiv ist.";
CM_ SG_ 870 BM_Taxi_Notalarm "Blinken bei Taxi-Not-Alarm

";
CM_ SG_ 870 BM_Telematik "Telematikblinken
";
CM_ SG_ 870 BM_Telematik_Abbruchgrund "Gibt bei erwaretem aber ausbleibendem Flankenanstieg der BM_Telematik an wieso die Ausführung verhindert wurde. Bei Flankenabfall der BM_Telematik wird angegeben wieso die Ausführung beendet wurde.

Bei nicht bereitem Sender soll 'init' gesendet werden,";
CM_ SG_ 870 BM_Warnblinken "Warnblinken

";
CM_ SG_ 870 BM_WBT_Beleuchtung "Aktivierung Warnblinktasterfunktionsbeleuchtung
Warnblinktasterfunktionsbeleuchtung soll aktiviert werden (statisch auf 1)";
CM_ SG_ 870 BM_Wischblinken "Blinkermodus Wisch_Blinken";
CM_ SG_ 870 BM_ZV_auf "Blinken bei ZV auf

";
CM_ SG_ 870 BM_ZV_zu "Blinken bei ZV zu

";
CM_ SG_ 870 DWA_Alarmquelle "Signalisiert den Auslösegrund der DWA";

CM_ SG_ 868 NBlinken_li_Fzg_Takt "Notlaufblinken, Fhzg-Takt links

";
CM_ SG_ 868 NBlinken_li_Kombi_Takt "Notlaufblinken, Blinkerkontrolllampe links

";
CM_ SG_ 868 NBlinken_re_Fzg_Takt "Notlaufblinken, Fhzg-Takt rechts
";
CM_ SG_ 868 NBlinken_re_Kombi_Takt "Notlaufblinken, Blinkerkontrolllampe rechts

";

CM_ SG_ 687 BMS_As_Entladezaehler "Signal zur Berechnung des Lastprofils durch die RWB";
CM_ SG_ 687 BMS_As_Entladezaehler_Ueberlauf "Wird beim ersten Überlauf von BMS_As_Entladezahler auf 1 gesetzt. Reset über KL15-Wechsel";
CM_ SG_ 687 BMS_Rekuperation "Zähler: Anzeigesignal: Energiezufuhr in die HV-Batterie (Reku). Darf nicht durch Laden der Batterie bedatet werden";
CM_ SG_ 687 BMS_Rekuperation_Ueberlauf "Rekuperationleistungssignal BMS_Rekuperation mindest 1x übergelaufen";
CM_ SG_ 687 BMS_Verbrauch "Zähler: Energieentnahme aus der HV-Batterie";
CM_ SG_ 687 BMS_Verbrauch_Ueberlauf "Verbrauchssignal mindest 1x übergelaufen";

CM_ SG_ 1438 BMS_Batterie_Voko_Anf "Anforderung des BMC die Bauteilvorkonditionierung der HV-Batterie durchzuführen.";
CM_ SG_ 1438 BMS_Fehler_NTKreis "Fehler im NTKreis, HV-Batterie wird nicht klimatisiert
(Fehler, Fehlerfrei) ";
CM_ SG_ 1438 BMS_Fehlerstatus_EWP_02 "Fehlerstatus der elektrischen Wasserpumpe der HV-Batterie";
CM_ SG_ 1438 BMS_IstRuecklaufTemperatur_02 "Aktuelle Ruecklauftemperatur der Batterie";
CM_ SG_ 1438 BMS_IstVorlaufTemperatur "Aktuelle Vorlauftemperatur der Batterie";
CM_ SG_ 1438 BMS_Soll_PWM_Pumpe "Ansteuerungs-Sollwert der Batterie-Kühlmittelpumpe. 
Speziell im MQB PHEV: Istwert der Pumpenansteuerung (Batterie steuert Pumpe selbständig an).";
CM_ SG_ 1438 BMS_SollVolumenstrom "Soll Volumenstrom für Kühlkreislauf Batterie";
CM_ SG_ 1438 BMS_SollVorlauftemperatur "Soll_Vorlauftemperatur_Kühlmedium in °C";
CM_ SG_ 1438 BMS_Status_Ventil "Status des 3-2-Wege-Ventils (betätigt/unbetätigt/Fehler)";
CM_ SG_ 1438 BMS_Temp_Epsilon "Das Signal beschreibt die Differenz zwischen Batterie Soll-Temperatur und Batterie Ist-Temperatur.";
CM_ SG_ 1438 BMS_Temperatur "battery temperature / Momentanwert: Temperatur der Traktionsbatterie";
CM_ SG_ 1438 BMS_Temperierung_Anf "Temperierungsbedarf der HV-Batterie";

CM_ SG_ 1482 BMS_07_CRC "Für MLB:
'Berechnung siehe Lastenheft 'Kommunikationsabsicherung für FlexRay und CAN''

Ab MQB und MLBevo:
'Berechnung siehe Lastenheft 'End-to-End Kommunikationsabsicherung''

Endwerte siehe Begleitdokument 'S-PDU Kennungsfolgen'";
CM_ SG_ 1482 BMS_Ausgleichsladung_Anf "BMS wünscht eine Ausgleichsladung
Flag derzeit ungenutzt, da BalancingModus im Detail noch nicht geklärt.";
CM_ SG_ 1482 BMS_Balancing_Aktiv "Signal zeigt an, ob mindestens eine Zelle der HV Batterie balanciert wird";
CM_ SG_ 1482 BMS_Batteriediagnose "Anzeige von Textwarnungen";
CM_ SG_ 1482 BMS_Energieinhalt "aktuell nutzbarer Energieinhalt der HV-Batterie
(bezogen auf ein definiertes mittleres Belastungsprofil)";
CM_ SG_ 1482 BMS_Fehler_KuehlkreislaufLeckage "Bei einer Leckage im Kühlkreislauf wird dieser Fehler gesetzt.";
CM_ SG_ 1482 BMS_Freig_max_Performanz "Freigabe der Komponente, dass eine maximale Leistung zur Verfügung gestellt werden kann.";
CM_ SG_ 1482 BMS_Gesamtst_Spgfreiheit "0 = Funktion nicht aktiviert
1 = HV-System spannungsfrei (U_Zwkr von BMS, LE und Ladegerät < 20V, DCLadestecker nicht gesteckt und Service Disconnect entriegelt)
2 = HV-System nicht spannungsfrei (U_Zwkr von BMS, LE und Ladegerät >= 20V, Ladestecker ges";
CM_ SG_ 1482 BMS_KundenWarnung "Kunden Warnung aufgrund eines Batteriefehlers";
CM_ SG_ 1482 BMS_Ladevorgang_aktiv "Signalisiert aktiven Ladevorgang, Ladegerät und DC/DC aktiv.
Signal bleibt nach Kl.15 ein aktiv, bis ESP_Stillstandsflag gelöscht.

Abhängigkeit zu BMS_Energieinhalt";
CM_ SG_ 1482 BMS_MaxEnergieinhalt "maximaler nutzbarer Energieinhalt der HV-Batterie (bezogen auf Last KBI_RWDS_Lastprofil bei SOC=100%)
Abhängig von KBI_RWDS_Lastprofil";
CM_ SG_ 1482 BMS_RIso_Ext "Minimum des Isolationswiderstands zwischen Batteriegehäuse und HV+ bzw. Batteriegehäuse und HV- bei geschlossenen Schützen (externe Iso Messung)";

CM_ SG_ 1289 BMS_Energieinhalt_HiRes "aktuell nutzbarer Energieinhalt der HV-Batterie
(bezogen auf ein definiertes mittleres Belastungsprofil)";
CM_ SG_ 1289 BMS_MaxEnergieinhalt_HiRes "maximal nutzbarer Energieinhalt der HV-Batterie
(bezogen auf ein definiertes mittleres Belastungsprofil)";
CM_ SG_ 1289 BMS_NutzbarerEnergieinhalt "Restenergieinhalt der Traktionsbatterie, bezogen auf die Betriebsstrategiegrenzen";
CM_ SG_ 1289 BMS_NutzbarerSOC "Aktueller relativer Ladezustand der HV-Batterie";
CM_ SG_ 1289 BMS_Pred_Entladeperformance "Indikator Stromintegral in Entladerichtung. 
0%     = Start abrampen Peak-Entladestromgrenze auf Dauer-Entladestromgrenze.
100% = Voller Peak-Entladestrom verfügbar";
CM_ SG_ 1289 BMS_Pred_Ladeperformance "Indikator Stromintegral in Laderichtung. 
0%     = Start abrampen Peak-Ladestromgrenze auf Dauer-Ladestromgrenze.
100% = Voller Peak-Ladestrom verfügbar";

CM_ SG_ 2463978838 BMS_NutzbarerEnergieinhalt_HiRes "Restenergieinhalt der Traktionsbatterie, bezogen auf die Betriebsstrategiegrenzen";
CM_ SG_ 2463978838 BMS_ZellTemp_virtuell_max "Maximaler Wert der Zelltemperatur der HVB, Berechnung über Thermomodell";
CM_ SG_ 2463978838 BMS_ZellTemp_virtuell_min "Minimaler Wert der Zelltemperatur der HVB, Berechnung über Thermomodell";

CM_ SG_ 2589284070 BMS_ExtLadeleistung "Prognostizierte Ladeleistung während er Fahrt und im Stand die bei der aktuellen HVB-Temperatur und aktuellem SOC theoretisch maximal möglich ist.";

CM_ SG_ 903 Bremse_EV_02_CRC "Für MLB:
'Berechnung siehe Lastenheft 'Kommunikationsabsicherung für FlexRay und CAN''

Ab MQB und MLBevo:
'Berechnung siehe Lastenheft 'End-to-End Kommunikationsabsicherung''

Endwerte siehe Begleitdokument 'S-PDU Kennungsfolgen'";
CM_ SG_ 903 EBKV_BKL_Warnungen "Ansteuerung der BKL-Lampe";
CM_ SG_ 903 EBKV_Charisma_FahrPr "Aktuell eingestellte Kennlinie EBKV";
CM_ SG_ 903 EBKV_Charisma_Status "Systemstatus des FPA-Teilnehmers EBKV";
CM_ SG_ 903 EBKV_Hinweise "Ansteuerung der Textanzeige";
CM_ SG_ 903 EBKV_OBD_Status "Ansteuerung der MIL-Lampe über den MIL-Master (Motorsteuergerät)";
CM_ SG_ 903 EBKV_Warnungen "Ansteuerung Kombi zur Fahrerwarnung";

CM_ SG_ 902 CHA_Charge_LED "Ansteuerung der LED am Charge-Taster durch Charisma im PHEV";
CM_ SG_ 902 CHA_Current_Mode "Aktuell eingestelltes Charisma Fahrprogramm";
CM_ SG_ 902 CHA_Drehschalter_Istmodus "Aktuell eingestellte Vorgabe für Schalterposition des CHA-Drehschalters";
CM_ SG_ 902 CHA_Drive_Select1_LED "CHA Ansteuer Signal der Funktions LED";
CM_ SG_ 902 CHA_Eco_Charisma_LED "Ansteuerung der Funktions-LED der ECO alias Bluekey Taste bzw. Charisma-Taste.
Der Master der Fahrmodus-Funktion soll die Funktionsleuchte ansteuern, in der MQB Architektur ist der Master im Gateway untergebracht.";
CM_ SG_ 902 CHA_EV_LED "Ansteuerung der LED am EV-Taster durch Charisma im PHEV";
CM_ SG_ 902 CHA_Fahrer_Umschaltung "Die manuelle Umschaltung durch den Fahrer soll signalisiert werden, um zu automatischen Umschaltungen (z.B. Retries) differenzieren zu können.";
CM_ SG_ 902 CHA_Kombi_Texte "Anzeige des aktuellen Charisma-Fahrprofiles im Kombi.
Die Texte werden HUT-Spezifisch in einem Schnittstellen-LAH definiert.";
CM_ SG_ 902 CHA_Kombi_Texte_02 "Anzeige von Hinweistexten bzgl. Charismaumschaltungen im Kombi.
Die Texte werden HUT-Spezifisch in einem Schnittstellen-LAH definiert.";
CM_ SG_ 902 CHA_Offroad_LED "Ansteuerung der Offroad-LED";
CM_ SG_ 902 CHA_Ziel_FahrPr_03_01 "reserviert für Anforderung Ziel-Fahrprogramm";
CM_ SG_ 902 CHA_Ziel_FahrPr_03_02 "reserviert für Anforderung Ziel-Fahrprogramm";
CM_ SG_ 902 CHA_Ziel_FahrPr_AMB "Anforderung Ziel-Fahrprogramm Ambientelichtmodul";
CM_ SG_ 902 CHA_Ziel_FahrPr_HSP "Anforderung Ziel-Fahrprogramm Heckspoiler";
CM_ SG_ 902 CHA_Ziel_FahrPr_IVB "Anforderung Ziel-Fahrprogramm IVB";
CM_ SG_ 902 CHA_Ziel_FahrPr_KL "Anforderung Ziel-Fahrprogramm Klima";
CM_ SG_ 902 CHA_Ziel_FahrPr_RWB "Anforderung Zielfahrprogramm Reichweitenberechnung (RWB)";

CM_ SG_ 1022 CHA_Current_Mode_BMA "Aktuell eingestellter Charisma Betriebsmodus";
CM_ SG_ 1022 CHA_Fahrer_Umschaltung "Die manuelle Umschaltung durch den Fahrer soll signalisiert werden, um zu automatischen Umschaltungen (z.B. Retries) differenzieren zu können.";
CM_ SG_ 1022 CHA_Fahrer_Umschaltung_BMA "Die manuelle Umschaltung der Betriebsmodusauswahl durch den Fahrer soll signalisiert werden, um zu automatischen Umschaltungen (z.B. Retries) differenzieren zu können.";
CM_ SG_ 1022 CHA_Ziel_FahrPr_AGK "Signal zur Ansteuerung des Teilnehmers Abgasklappen durch den Charisma-Koordinator über das Motor-SG";
CM_ SG_ 1022 CHA_Ziel_FahrPr_BMS "Anforderung Ziel-Fahrprogramm BMS (nähere Spezifikation siehe Charisma-LH PAG)";
CM_ SG_ 1022 CHA_Ziel_FahrPr_EDS "Anforderung Ziel-Fahrprogramm Elektronische Differentialsperre";
CM_ SG_ 1022 CHA_Ziel_FahrPr_HHC "Anforderung Ziel-Fahrprogramm Hill Hold Control";
CM_ SG_ 1022 CHA_Ziel_FahrPr_MO_Freilauf "Anforderung Ziel-Fahrprogramm Funktion Freilauf Motor aus";
CM_ SG_ 1022 CHA_Ziel_FahrPr_PACC "Anforderung Ziel-Fahrprogramm InnoDrive (PACCh)";
CM_ SG_ 1022 CHA_Ziel_FahrPr_PDC "Signal zur Ansteuerung des PDC/PLA durch den Charisma-Koordinator";
CM_ SG_ 1022 CHA_Ziel_FahrPr_Reku_ZwGas "Anforderung Ziel-Fahrprogramm für Rekuperation oder Zwischengas";

CM_ SG_ 2463978630 CHA_Charisma_LED1 "Ausleuchtungsvorgabe an Taste1 des 3-Tasten-Moduls für die Funktion Charisma";
CM_ SG_ 2463978630 CHA_Charisma_LED2 "Ausleuchtungsvorgabe an Taste2 des 3-Tasten-Moduls für die Funktion Charisma";
CM_ SG_ 2463978630 CHA_Charisma_LED3 "Ausleuchtungsvorgabe an Taste3 des 3-Tasten-Moduls für die Funktion Charisma";
CM_ SG_ 2463978630 CHA_Drehschalter_VW_Blinken "Ansteuerung der blinkenden Mode-LED im Charisma Drehschalter";
CM_ SG_ 2463978630 CHA_Drehschalter_VW_Istmodus "Aktuell eingestellte Vorgabe für Schalterposition des CHA-Drehschalters";
CM_ SG_ 2463978630 CHA_Drehschalter_VW_Mode_LED "Ansteuerung der Funktions-LED im Charisma Drehschalter";

CM_ SG_ 2527679663 CHA_Ziel_FahrPr_Antrieb_LB "Anzeige der Individual (EGO) Gruppe Antrieb im FPK.";
CM_ SG_ 2527679663 CHA_Ziel_FahrPr_Fahrwerk_LB "Anzeige der Individual (EGO) Gruppe Fahrwerk im FPK.";
CM_ SG_ 2527679663 CHA_Ziel_FahrPr_Lenkung_LB "Anzeige der Individual (EGO) Gruppe Lenkung im FPK.";

CM_ SG_ 615 Daempfer_02_CRC "Für MLB:
'Berechnung siehe Lastenheft 'Kommunikationsabsicherung für FlexRay und CAN''

Ab MQB und MLBevo:
'Berechnung siehe Lastenheft 'End-to-End Kommunikationsabsicherung''

Endwerte siehe Begleitdokument 'S-PDU Kennungsfolgen'";
CM_ SG_ 615 DR_Charisma_FahrPr "MLBevo: Aktuelles Fahrprogramm des Charisma-Teilnehmers (siehe Systemlastenheft Drive Select)
MQB: Istwert der Kennlinie (siehe Systemlastenheft MQB FPA)";
CM_ SG_ 615 DR_Charisma_Status "Charisma Systemstatus des Charisma-Teilnehmers

Wert 0x3 ist nur für Fahrzeuge ab MQB relevant";
CM_ SG_ 615 DR_DynAGL_Anf_Entkopplung "Nur PO44x
Dynamische Aggregatelagerung
Anforderung zusätzliche Entkopplung für Getriebelager";
CM_ SG_ 615 DR_DynAGL_Anf_im_Leerlauf "Nur PO44x
Anforderung zusätzliche Entkopplung des Motorlagers im Leerlauf";
CM_ SG_ 615 DR_ESP_Zuschaltung "Zwangsweise Aktivierung ESP-Funktionalität durch die Dämpferregelung, Anforderung erfolgt auch bei Passivtastung.";
CM_ SG_ 615 DR_Systemstatus "Bei Statusänderung wird der Soll-Zustand ausgegeben. Der Status beschreibt einen Parametersatz: Temporäre Änderung der Dämpfereinstellungen werden hier nicht abgebildet. 
";
CM_ SG_ 615 EFP_LstgBegr "Anzeige der aktuell maximal zur Verfuegung stehend Antriebsleistung bei Eingriff durch Bauteilschutz Bremse";
CM_ SG_ 615 EFP_Niveauzustand_Lift "Rückmeldung Niveauzustand Liftfunktionalität";
CM_ SG_ 615 EFP_Verfuegbarkeit_Lift "Verfuegbarkeit der Liftfunktionalitaet";
CM_ SG_ 615 EFP_Vorlaufzeit_Lift "Vorlaufzeit Heben für Smartlift";

CM_ SG_ 1012 DC_HYB_Auslastungsgrad "Momentanwert: Auslastung DC/DC (DFM Signal), entspricht I_akt / I_max
(Vorhalt für MQB)";
CM_ SG_ 1012 DC_HYB_iAktReserveLV "Momentanwert: Stromreserve vom DC/DC-Wandler in Richtung 12V-Bordnetz
Im MLBevo nur positiver Bereich genutzt

Tiefsetzen - positiv
Hochsetzen - negativ";
CM_ SG_ 1012 DC_Verbrauch "Energieverbrauch vom DCDC für Versorgung 12V-Bordnetz inkl. seines eigenen Wirkungsgrads (bspw.: HV_Strom*HV_Spannung*t)";
CM_ SG_ 1012 DC_Verbrauch_Ueberlauf "Überlauf-Bit für das Signal DC_Verbrauch";
CM_ SG_ 1012 DC_Verlustleistung "Aktuelle Verlustleistung des DC/DC-Wandlers.";
CM_ SG_ 1012 DCDC_02_CRC "Für MLB:
'Berechnung siehe Lastenheft 'Kommunikationsabsicherung für FlexRay und CAN''

Ab MQB und MLBevo:
'Berechnung siehe Lastenheft 'End-to-End Kommunikationsabsicherung''

Endwerte siehe Begleitdokument 'S-PDU Kennungsfolgen'";

CM_ SG_ 2549880747 DIA_SAAM_Req_Data "Diagnose Request Flashen SAAM";

CM_ SG_ 2550011819 DIA_SAAM_Resp_Data "Diagnose Response Flashen SAAM";

CM_ SG_ 2549880434 DIA_UHR_Req_Data "Diagnose Request Flashen UHR";

CM_ SG_ 2550011506 DIA_UHR_Resp_Data "Diagnose Response Flashen UHR";

CM_ SG_ 1714 DGN_Verlernzaehler "wrap around 254 --> 0";
CM_ SG_ 1714 KBI_Kilometerstand "Fehler wird ausgegeben, falls Kilometerstand nicht restaurierbar
";
CM_ SG_ 1714 UH_Minute "0x3C- 0x3f = Werte ungültig";
CM_ SG_ 1714 UH_Monat "0x0D, 0xF =  Werte ungültig
0x0E = Relatives Datum (nur VW)";
CM_ SG_ 1714 UH_Sekunde "0x3C- 0x3f = Werte ungültig";
CM_ SG_ 1714 UH_Stunde "0x18 - 0x1F = Werte ungültig";
CM_ SG_ 1714 UH_Tag "0x0: reserviert bei VW";
CM_ SG_ 1714 Uhrzeit_01_alt "
";
BA_DEF_REL_ BU_SG_REL_  "GenSigTimeoutTime" INT 0 65535;
BA_DEF_ BO_  "DiagRequest" ENUM "No", "Yes";
BA_DEF_ BO_  "DiagResponse" ENUM "No", "Yes";
BA_DEF_ BO_  "DiagState" ENUM "No", "Yes";
BA_DEF_ BO_  "GenMsgChkConstant" HEX 0 4095;
BA_DEF_ BO_  "GenMsgCycleTime" INT 0 65535;
BA_DEF_ BO_  "GenMsgCycleTimeFast" INT 0 65535;
BA_DEF_ BO_  "GenMsgDelayTime" INT 0 100000;
BA_DEF_ BO_  "GenMsgILSupport" ENUM "No", "Yes";
BA_DEF_ BO_  "GenMsgNrOfRepetition" INT 0 100;
BA_DEF_ BO_  "GenMsgPDUConstants" STRING;
BA_DEF_ BO_  "GenMsgSendType" ENUM "Cyclic", "not_used", "not_used", "not_used", "not_used", "not_used", "not_used", "IfActive", "NoMsgSendType";
BA_DEF_ BO_  "GenMsgStartDelayTime" INT 0 100000;
BA_DEF_ BO_  "NmMessage" ENUM "No", "Yes";
BA_DEF_ BO_  "NmhMessage" ENUM "No", "Yes";
BA_DEF_ BO_  "MsgType" ENUM "Application", "NM ", "NMH", "TP2.0", "ISO-TP ", "BAP", "EID", "KS", "XCP_PRE_CONFIGURED", "XCP_RUNTIME_CONFIGURED";
BA_DEF_ BO_  "VAGTP20_API" HEX 0 255;
BA_DEF_ BO_  "VAGTP20_DynConnection" ENUM "No", "Yes";
BA_DEF_ BO_  "VAGTP20_DynSetup" ENUM "No", "Yes";
BA_DEF_ BO_  "VAGTP20_StatConnection" ENUM "No", "Yes";
BA_DEF_ SG_  "GenSigActiveRepetitions" INT -2147483648 2147483647;
BA_DEF_ SG_  "GenSigInactiveValue" INT -2147483648 2147483647;
BA_DEF_ SG_  "GenSigSendType" ENUM "Cyclic", "OnWrite", "OnWriteWithRepetition", "OnChange", "OnChangeWithRepetition", "IfActive", "IfActiveWithRepetition", "NoSigSendType", "OnChangeAndIfActive", "OnChangeAndIfActiveWithRepetition";
BA_DEF_ SG_  "GenSigStartValue" INT -2147483648 2147483647;
BA_DEF_ SG_  "NWM-WakeupAllowed" ENUM "No", "Yes";
BA_DEF_ SG_  "GenSigFuncType" ENUM "NoFunction", "MsgCounter", "CRC-8", "XOR", "XOR-2", "DatedBit", "SW-Kl15", "CHK", "Constant", "Protocol", "CRC-8-SAE_J1850", "CRC-32", "DataLength", "DataID", "MsgCounter16", "SOK-Signatur", "Cluster";
BA_DEF_ SG_  "GenSigSwitchedByIgnition" ENUM "No", "Yes";
BA_DEF_ SG_  "Fehlerwert" HEX 0 2147483647;
BA_DEF_ SG_  "GenSigMissingSourceValue" HEX 0 2147483647;
BA_DEF_DEF_REL_  "GenSigTimeoutTime" 0;
BA_DEF_DEF_  "DiagRequest" "No";
BA_DEF_DEF_  "DiagResponse" "No";
BA_DEF_DEF_  "DiagState" "No";
BA_DEF_DEF_  "GenMsgChkConstant" 0;
BA_DEF_DEF_  "GenMsgCycleTime" 0;
BA_DEF_DEF_  "GenMsgCycleTimeFast" 0;
BA_DEF_DEF_  "GenMsgDelayTime" 0;
BA_DEF_DEF_  "GenMsgILSupport" "No";
BA_DEF_DEF_  "GenMsgNrOfRepetition" 0;
BA_DEF_DEF_  "GenMsgPDUConstants" "";
BA_DEF_DEF_  "GenMsgSendType" "NoMsgSendType";
BA_DEF_DEF_  "GenMsgStartDelayTime" 0;
BA_DEF_DEF_  "NmMessage" "No";
BA_DEF_DEF_  "NmhMessage" "No";
BA_DEF_DEF_  "MsgType" "Application";
BA_DEF_DEF_  "VAGTP20_API" 0;
BA_DEF_DEF_  "VAGTP20_DynConnection" "No";
BA_DEF_DEF_  "VAGTP20_DynSetup" "No";
BA_DEF_DEF_  "VAGTP20_StatConnection" "No";
BA_DEF_DEF_  "GenSigActiveRepetitions" 0;
BA_DEF_DEF_  "GenSigInactiveValue" 0;
BA_DEF_DEF_  "GenSigSendType" "NoSigSendType";
BA_DEF_DEF_  "GenSigStartValue" 0;
BA_DEF_DEF_  "NWM-WakeupAllowed" "No";
BA_DEF_DEF_  "GenSigFuncType" "NoFunction";
BA_DEF_DEF_  "GenSigSwitchedByIgnition" "Yes";
BA_DEF_DEF_  "Fehlerwert" 0;
BA_DEF_DEF_  "GenSigMissingSourceValue" 0;
BA_ "GenMsgCycleTime" BO_ 2463978631 1000;
BA_ "GenMsgDelayTime" BO_ 2463978631 50;
BA_ "GenMsgILSupport" BO_ 2463978631 1;
BA_ "GenMsgSendType" BO_ 2463978631 0;
BA_ "GenMsgStartDelayTime" BO_ 2463978631 50;
BA_ "MsgType" BO_ 2536703233 5;
BA_ "MsgType" BO_ 2536703248 5;
BA_ "MsgType" BO_ 2536722177 5;
BA_ "MsgType" BO_ 2536722192 5;
BA_ "MsgType" BO_ 2536714496 5;
BA_ "MsgType" BO_ 2536714497 5;
BA_ "MsgType" BO_ 2536714498 5;
BA_ "MsgType" BO_ 2536714499 5;
BA_ "MsgType" BO_ 2536714512 5;
BA_ "MsgType" BO_ 2536714513 5;
BA_ "MsgType" BO_ 2536720385 5;
BA_ "MsgType" BO_ 2536720400 5;
BA_ "MsgType" BO_ 2536711426 5;
BA_ "MsgType" BO_ 2536711429 5;
BA_ "MsgType" BO_ 2536711440 5;
BA_ "MsgType" BO_ 2536705792 5;
BA_ "MsgType" BO_ 2536705793 5;
BA_ "MsgType" BO_ 2536705794 5;
BA_ "MsgType" BO_ 2536705795 5;
BA_ "MsgType" BO_ 2536705796 5;
BA_ "MsgType" BO_ 2536705797 5;
BA_ "MsgType" BO_ 2536705808 5;
BA_ "MsgType" BO_ 2536710912 5;
BA_ "MsgType" BO_ 2536710928 5;
BA_ "MsgType" BO_ 2536711680 5;
BA_ "MsgType" BO_ 2536711696 5;
BA_ "MsgType" BO_ 2536707841 5;
BA_ "MsgType" BO_ 2536707845 5;
BA_ "MsgType" BO_ 2536707856 5;
BA_ "MsgType" BO_ 2536767264 5;
BA_ "MsgType" BO_ 2536767280 5;
BA_ "MsgType" BO_ 2536719616 5;
BA_ "MsgType" BO_ 2536719617 5;
BA_ "MsgType" BO_ 2536719632 5;
BA_ "MsgType" BO_ 2536705282 5;
BA_ "MsgType" BO_ 2536705296 5;
BA_ "MsgType" BO_ 2536706816 5;
BA_ "MsgType" BO_ 2536706817 5;
BA_ "MsgType" BO_ 2536706818 5;
BA_ "MsgType" BO_ 2536706819 5;
BA_ "MsgType" BO_ 2536706832 5;
BA_ "MsgType" BO_ 2536702976 5;
BA_ "MsgType" BO_ 2536702977 5;
BA_ "MsgType" BO_ 2536702978 5;
BA_ "MsgType" BO_ 2536702992 5;
BA_ "MsgType" BO_ 2536709121 5;
BA_ "MsgType" BO_ 2536709136 5;
BA_ "MsgType" BO_ 2536722945 5;
BA_ "MsgType" BO_ 2536722960 5;
BA_ "MsgType" BO_ 2536708353 5;
BA_ "MsgType" BO_ 2536708368 5;
BA_ "MsgType" BO_ 2536732672 5;
BA_ "MsgType" BO_ 2536732688 5;
BA_ "MsgType" BO_ 2536715264 5;
BA_ "MsgType" BO_ 2536715280 5;
BA_ "MsgType" BO_ 2536714752 5;
BA_ "MsgType" BO_ 2536714753 5;
BA_ "MsgType" BO_ 2536714754 5;
BA_ "MsgType" BO_ 2536714755 5;
BA_ "MsgType" BO_ 2536714768 5;
BA_ "MsgType" BO_ 2536714769 5;
BA_ "MsgType" BO_ 2536708097 5;
BA_ "MsgType" BO_ 2536708112 5;
BA_ "MsgType" BO_ 2536712704 5;
BA_ "MsgType" BO_ 2536712705 5;
BA_ "MsgType" BO_ 2536712720 5;
BA_ "MsgType" BO_ 2536702723 5;
BA_ "MsgType" BO_ 2536702736 5;
BA_ "MsgType" BO_ 2536703745 5;
BA_ "MsgType" BO_ 2536703760 5;
BA_ "MsgType" BO_ 2536709889 5;
BA_ "MsgType" BO_ 2536709904 5;
BA_ "MsgType" BO_ 2536719872 5;
BA_ "MsgType" BO_ 2536719888 5;
BA_ "MsgType" BO_ 2536706560 5;
BA_ "MsgType" BO_ 2536706561 5;
BA_ "MsgType" BO_ 2536706562 5;
BA_ "MsgType" BO_ 2536706576 5;
BA_ "MsgType" BO_ 2536720896 5;
BA_ "MsgType" BO_ 2536720912 5;
BA_ "MsgType" BO_ 2536703489 5;
BA_ "MsgType" BO_ 2536703504 5;
BA_ "MsgType" BO_ 2536708609 5;
BA_ "MsgType" BO_ 2536708624 5;
BA_ "MsgType" BO_ 2536712448 5;
BA_ "MsgType" BO_ 2536712449 5;
BA_ "MsgType" BO_ 2536712464 5;
BA_ "MsgType" BO_ 2536712465 5;
BA_ "MsgType" BO_ 2536712192 5;
BA_ "MsgType" BO_ 2536712193 5;
BA_ "MsgType" BO_ 2536712194 5;
BA_ "MsgType" BO_ 2536712195 5;
BA_ "MsgType" BO_ 2536712208 5;
BA_ "MsgType" BO_ 2536712209 5;
BA_ "MsgType" BO_ 2536711169 5;
BA_ "MsgType" BO_ 2536711170 5;
BA_ "MsgType" BO_ 2536711184 5;
BA_ "MsgType" BO_ 2536706304 5;
BA_ "MsgType" BO_ 2536706305 5;
BA_ "MsgType" BO_ 2536706306 5;
BA_ "MsgType" BO_ 2536706308 5;
BA_ "MsgType" BO_ 2536706309 5;
BA_ "MsgType" BO_ 2536706310 5;
BA_ "MsgType" BO_ 2536706311 5;
BA_ "MsgType" BO_ 2536706320 5;
BA_ "MsgType" BO_ 2536710401 5;
BA_ "MsgType" BO_ 2536710416 5;
BA_ "GenMsgCycleTime" BO_ 1615 1000;
BA_ "GenMsgDelayTime" BO_ 1615 40;
BA_ "GenMsgILSupport" BO_ 1615 1;
BA_ "GenMsgSendType" BO_ 1615 0;
BA_ "GenMsgCycleTime" BO_ 1626 1000;
BA_ "GenMsgCycleTimeFast" BO_ 1626 100;
BA_ "GenMsgDelayTime" BO_ 1626 50;
BA_ "GenMsgILSupport" BO_ 1626 1;
BA_ "GenMsgNrOfRepetition" BO_ 1626 10;
BA_ "GenMsgSendType" BO_ 1626 0;
BA_ "GenMsgCycleTime" BO_ 672 200;
BA_ "GenMsgCycleTimeFast" BO_ 672 20;
BA_ "GenMsgDelayTime" BO_ 672 20;
BA_ "GenMsgILSupport" BO_ 672 1;
BA_ "GenMsgNrOfRepetition" BO_ 672 5;
BA_ "GenMsgPDUConstants" BO_ 672 "0x6a,0x65,0x16,0x26,0xd9,0x99,0xd1,0x84,0xf3,0x9c,0xa4,0xaa,0x07,0xea,0xc2,0xcb";
BA_ "GenMsgSendType" BO_ 672 0;
BA_ "GenMsgCycleTime" BO_ 2527679637 1000;
BA_ "GenMsgDelayTime" BO_ 2527679637 50;
BA_ "GenMsgILSupport" BO_ 2527679637 1;
BA_ "GenMsgSendType" BO_ 2527679637 0;
BA_ "GenMsgCycleTime" BO_ 2463978607 200;
BA_ "GenMsgDelayTime" BO_ 2463978607 20;
BA_ "GenMsgILSupport" BO_ 2463978607 1;
BA_ "GenMsgSendType" BO_ 2463978607 0;
BA_ "GenMsgCycleTime" BO_ 870 1000;
BA_ "GenMsgCycleTimeFast" BO_ 870 50;
BA_ "GenMsgDelayTime" BO_ 870 10;
BA_ "GenMsgILSupport" BO_ 870 1;
BA_ "GenMsgNrOfRepetition" BO_ 870 5;
BA_ "GenMsgSendType" BO_ 870 0;
BA_ "GenMsgCycleTimeFast" BO_ 868 50;
BA_ "GenMsgDelayTime" BO_ 868 5;
BA_ "GenMsgILSupport" BO_ 868 1;
BA_ "GenMsgNrOfRepetition" BO_ 868 5;
BA_ "GenMsgSendType" BO_ 868 7;
BA_ "GenMsgCycleTime" BO_ 687 50;
BA_ "GenMsgILSupport" BO_ 687 1;
BA_ "GenMsgSendType" BO_ 687 0;
BA_ "GenMsgCycleTime" BO_ 1438 500;
BA_ "GenMsgILSupport" BO_ 1438 1;
BA_ "GenMsgSendType" BO_ 1438 0;
BA_ "GenMsgChkConstant" BO_ 1482 67;
BA_ "GenMsgCycleTime" BO_ 1482 500;
BA_ "GenMsgDelayTime" BO_ 1482 50;
BA_ "GenMsgILSupport" BO_ 1482 1;
BA_ "GenMsgPDUConstants" BO_ 1482 "0x43,0x43,0x43,0x43,0x43,0x43,0x43,0x43,0x43,0x43,0x43,0x43,0x43,0x43,0x43,0x43";
BA_ "GenMsgSendType" BO_ 1482 0;
BA_ "GenMsgCycleTime" BO_ 1289 100;
BA_ "GenMsgILSupport" BO_ 1289 1;
BA_ "GenMsgSendType" BO_ 1289 0;
BA_ "GenMsgCycleTime" BO_ 2463978838 100;
BA_ "GenMsgILSupport" BO_ 2463978838 1;
BA_ "GenMsgSendType" BO_ 2463978838 0;
BA_ "GenMsgCycleTime" BO_ 2589284070 2000;
BA_ "GenMsgILSupport" BO_ 2589284070 1;
BA_ "GenMsgSendType" BO_ 2589284070 0;
BA_ "GenMsgChkConstant" BO_ 903 222;
BA_ "GenMsgCycleTime" BO_ 903 80;
BA_ "GenMsgILSupport" BO_ 903 1;
BA_ "GenMsgPDUConstants" BO_ 903 "0xde,0xde,0xde,0xde,0xde,0xde,0xde,0xde,0xde,0xde,0xde,0xde,0xde,0xde,0xde,0xde";
BA_ "GenMsgSendType" BO_ 903 0;
BA_ "GenMsgCycleTime" BO_ 902 1000;
BA_ "GenMsgDelayTime" BO_ 902 50;
BA_ "GenMsgILSupport" BO_ 902 1;
BA_ "GenMsgSendType" BO_ 902 0;
BA_ "GenMsgStartDelayTime" BO_ 902 50;
BA_ "GenMsgCycleTime" BO_ 1022 1000;
BA_ "GenMsgDelayTime" BO_ 1022 50;
BA_ "GenMsgILSupport" BO_ 1022 1;
BA_ "GenMsgSendType" BO_ 1022 0;
BA_ "GenMsgStartDelayTime" BO_ 1022 50;
BA_ "GenMsgCycleTime" BO_ 2463978630 1000;
BA_ "GenMsgDelayTime" BO_ 2463978630 50;
BA_ "GenMsgILSupport" BO_ 2463978630 1;
BA_ "GenMsgSendType" BO_ 2463978630 0;
BA_ "GenMsgStartDelayTime" BO_ 2463978630 50;
BA_ "GenMsgCycleTime" BO_ 2527679663 1000;
BA_ "GenMsgDelayTime" BO_ 2527679663 50;
BA_ "GenMsgILSupport" BO_ 2527679663 1;
BA_ "GenMsgSendType" BO_ 2527679663 0;
BA_ "GenMsgStartDelayTime" BO_ 2527679663 50;
BA_ "GenMsgCycleTime" BO_ 615 80;
BA_ "GenMsgILSupport" BO_ 615 1;
BA_ "GenMsgPDUConstants" BO_ 615 "0xc7,0x7d,0x4c,0x0e,0x19,0xaf,0x2e,0x0b,0x8d,0x24,0x62,0x58,0x67,0x88,0x93,0x9e";
BA_ "GenMsgSendType" BO_ 615 0;
BA_ "GenMsgCycleTime" BO_ 1012 100;
BA_ "GenMsgILSupport" BO_ 1012 1;
BA_ "GenMsgPDUConstants" BO_ 1012 "0x26,0xe4,0xc5,0x16,0xcf,0x20,0x65,0xad,0xed,0x6a,0xa3,0x49,0x02,0x6b,0xb2,0xbd";
BA_ "GenMsgSendType" BO_ 1012 0;
BA_ "MsgType" BO_ 2617039360 6;
BA_ "MsgType" BO_ 2617039615 6;
BA_ "MsgType" BO_ 2617025024 6;
BA_ "MsgType" BO_ 2617025279 6;
BA_ "MsgType" BO_ 2617154048 6;
BA_ "MsgType" BO_ 2617154303 6;
BA_ "DiagRequest" BO_ 2549880747 1;
BA_ "MsgType" BO_ 2549880747 4;
BA_ "DiagResponse" BO_ 2550011819 1;
BA_ "MsgType" BO_ 2550011819 4;
BA_ "DiagRequest" BO_ 2549880434 1;
BA_ "MsgType" BO_ 2549880434 4;
BA_ "DiagResponse" BO_ 2550011506 1;
BA_ "MsgType" BO_ 2550011506 4;
BA_ "GenMsgCycleTime" BO_ 1714 1000;
BA_ "GenMsgILSupport" BO_ 1714 1;
BA_ "GenMsgSendType" BO_ 1714 0;
BA_ "GenMsgStartDelayTime" BO_ 1714 55;
BA_ "GenSigSendType" SG_ 2463978631 AST_Laengssperre 3;
BA_ "GenSigSwitchedByIgnition" SG_ 2463978631 AST_Laengssperre 0;
BA_ "Fehlerwert" SG_ 2463978631 AST_Laengssperre 3;
BA_ "GenSigSendType" SG_ 2463978631 AST_Low 3;
BA_ "GenSigSwitchedByIgnition" SG_ 2463978631 AST_Low 0;
BA_ "Fehlerwert" SG_ 2463978631 AST_Low 3;
BA_ "GenSigSendType" SG_ 2463978631 AST_Quersperre 3;
BA_ "GenSigSwitchedByIgnition" SG_ 2463978631 AST_Quersperre 0;
BA_ "Fehlerwert" SG_ 2463978631 AST_Quersperre 3;
BA_ "GenSigSendType" SG_ 2463978631 BuA_Charisma_Taste1 3;
BA_ "GenSigSwitchedByIgnition" SG_ 2463978631 BuA_Charisma_Taste1 0;
BA_ "Fehlerwert" SG_ 2463978631 BuA_Charisma_Taste1 3;
BA_ "GenSigSendType" SG_ 2463978631 BuA_Charisma_Taste2 3;
BA_ "GenSigSwitchedByIgnition" SG_ 2463978631 BuA_Charisma_Taste2 0;
BA_ "Fehlerwert" SG_ 2463978631 BuA_Charisma_Taste2 3;
BA_ "GenSigSendType" SG_ 2463978631 BuA_Charisma_Taste3 3;
BA_ "GenSigSwitchedByIgnition" SG_ 2463978631 BuA_Charisma_Taste3 0;
BA_ "Fehlerwert" SG_ 2463978631 BuA_Charisma_Taste3 3;
BA_ "GenSigSendType" SG_ 2463978631 CHA_Drehschalter_VW_defekt 3;
BA_ "GenSigSwitchedByIgnition" SG_ 2463978631 CHA_Drehschalter_VW_defekt 0;
BA_ "Fehlerwert" SG_ 2463978631 CHA_Drehschalter_VW_defekt 1;
BA_ "GenSigSendType" SG_ 2463978631 CHA_Drehschalter_VW_Mode_Taster 3;
BA_ "GenSigSwitchedByIgnition" SG_ 2463978631 CHA_Drehschalter_VW_Mode_Taster 0;
BA_ "GenSigSendType" SG_ 2463978631 CHA_Drehschalter_VW_Modus 3;
BA_ "GenSigSwitchedByIgnition" SG_ 2463978631 CHA_Drehschalter_VW_Modus 0;
BA_ "Fehlerwert" SG_ 2463978631 CHA_Drehschalter_VW_Modus 15;
BA_ "GenSigSendType" SG_ 2463978631 LDT_Drehschalter_Betaetigt 3;
BA_ "GenSigStartValue" SG_ 2463978631 LDT_Drehschalter_Betaetigt 2;
BA_ "GenSigSwitchedByIgnition" SG_ 2463978631 LDT_Drehschalter_Betaetigt 0;
BA_ "Fehlerwert" SG_ 2463978631 LDT_Drehschalter_Betaetigt 3;
BA_ "GenSigSendType" SG_ 2463978631 LDT_Drehschalter_Hoch 3;
BA_ "GenSigStartValue" SG_ 2463978631 LDT_Drehschalter_Hoch 2;
BA_ "GenSigSwitchedByIgnition" SG_ 2463978631 LDT_Drehschalter_Hoch 0;
BA_ "Fehlerwert" SG_ 2463978631 LDT_Drehschalter_Hoch 3;
BA_ "GenSigSendType" SG_ 2463978631 LDT_Drehschalter_Modus 3;
BA_ "GenSigSwitchedByIgnition" SG_ 2463978631 LDT_Drehschalter_Modus 0;
BA_ "GenSigSendType" SG_ 2463978631 LDT_Drehschalter_Tief 3;
BA_ "GenSigStartValue" SG_ 2463978631 LDT_Drehschalter_Tief 2;
BA_ "GenSigSwitchedByIgnition" SG_ 2463978631 LDT_Drehschalter_Tief 0;
BA_ "Fehlerwert" SG_ 2463978631 LDT_Drehschalter_Tief 3;
BA_ "GenSigSendType" SG_ 2463978631 LDT_Sync_Betaetigt 3;
BA_ "GenSigStartValue" SG_ 2463978631 LDT_Sync_Betaetigt 2;
BA_ "GenSigSwitchedByIgnition" SG_ 2463978631 LDT_Sync_Betaetigt 0;
BA_ "Fehlerwert" SG_ 2463978631 LDT_Sync_Betaetigt 3;
BA_ "GenSigSendType" SG_ 2536703233 BAP_ACC_ASG_02_Header 3;
BA_ "GenSigSwitchedByIgnition" SG_ 2536703233 BAP_ACC_ASG_02_Header 0;
BA_ "GenSigSendType" SG_ 2536703248 BAP_ACC_FSG_01_Header 3;
BA_ "GenSigSendType" SG_ 2536722177 BAP_AHC_ASG_02_Header 3;
BA_ "GenSigSwitchedByIgnition" SG_ 2536722177 BAP_AHC_ASG_02_Header 0;
BA_ "GenSigSendType" SG_ 2536722192 BAP_AHC_FSG_01_Header 3;
BA_ "GenSigSwitchedByIgnition" SG_ 2536722192 BAP_AHC_FSG_01_Header 0;
BA_ "GenSigSendType" SG_ 2536714496 BAP_Audio_ASG_01_Header 3;
BA_ "GenSigSwitchedByIgnition" SG_ 2536714496 BAP_Audio_ASG_01_Header 0;
BA_ "GenSigSendType" SG_ 2536714497 BAP_Audio_ASG_02_Header 3;
BA_ "GenSigSwitchedByIgnition" SG_ 2536714497 BAP_Audio_ASG_02_Header 0;
BA_ "GenSigSendType" SG_ 2536714498 BAP_Audio_ASG_03_Header 3;
BA_ "GenSigSwitchedByIgnition" SG_ 2536714498 BAP_Audio_ASG_03_Header 0;
BA_ "GenSigSendType" SG_ 2536714499 BAP_Audio_ASG_04_Header 3;
BA_ "GenSigSwitchedByIgnition" SG_ 2536714499 BAP_Audio_ASG_04_Header 0;
BA_ "GenSigSendType" SG_ 2536714512 BAP_Audio_FSG_01_Header 3;
BA_ "GenSigSwitchedByIgnition" SG_ 2536714512 BAP_Audio_FSG_01_Header 0;
BA_ "GenSigSendType" SG_ 2536714513 BAP_Audio_FSG_02_Header 3;
BA_ "GenSigSwitchedByIgnition" SG_ 2536714513 BAP_Audio_FSG_02_Header 0;
BA_ "GenSigSendType" SG_ 2536720385 BAP_AWC_ASG_02_Header 3;
BA_ "GenSigSwitchedByIgnition" SG_ 2536720385 BAP_AWC_ASG_02_Header 0;
BA_ "GenSigSendType" SG_ 2536720400 BAP_AWC_FSG_01_Header 3;
BA_ "GenSigSwitchedByIgnition" SG_ 2536720400 BAP_AWC_FSG_01_Header 0;
BA_ "GenSigSendType" SG_ 2536711426 BAP_BatteryControl_ASG_03_Header 3;
BA_ "GenSigSwitchedByIgnition" SG_ 2536711426 BAP_BatteryControl_ASG_03_Header 0;
BA_ "GenSigSendType" SG_ 2536711429 BAP_BatteryControl_ASG_06_Header 3;
BA_ "GenSigSwitchedByIgnition" SG_ 2536711429 BAP_BatteryControl_ASG_06_Header 0;
BA_ "GenSigSendType" SG_ 2536711440 BAP_BatteryControl_FSG_01_Header 3;
BA_ "GenSigSwitchedByIgnition" SG_ 2536711440 BAP_BatteryControl_FSG_01_Header 0;
BA_ "GenSigSendType" SG_ 2536705792 BAP_BC_ASG_01_Header 3;
BA_ "GenSigSwitchedByIgnition" SG_ 2536705792 BAP_BC_ASG_01_Header 0;
BA_ "GenSigSendType" SG_ 2536705793 BAP_BC_ASG_02_Header 3;
BA_ "GenSigSwitchedByIgnition" SG_ 2536705793 BAP_BC_ASG_02_Header 0;
BA_ "GenSigSendType" SG_ 2536705794 BAP_BC_ASG_03_Header 3;
BA_ "GenSigSwitchedByIgnition" SG_ 2536705794 BAP_BC_ASG_03_Header 0;
BA_ "GenSigSendType" SG_ 2536705795 BAP_BC_ASG_04_Header 3;
BA_ "GenSigSwitchedByIgnition" SG_ 2536705795 BAP_BC_ASG_04_Header 0;
BA_ "GenSigSendType" SG_ 2536705796 BAP_BC_ASG_05_Header 3;
BA_ "GenSigSwitchedByIgnition" SG_ 2536705796 BAP_BC_ASG_05_Header 0;
BA_ "GenSigSendType" SG_ 2536705797 BAP_BC_ASG_06_Header 3;
BA_ "GenSigSwitchedByIgnition" SG_ 2536705797 BAP_BC_ASG_06_Header 0;
BA_ "GenSigSendType" SG_ 2536705808 BAP_BC_FSG_01_Header 3;
BA_ "GenSigSwitchedByIgnition" SG_ 2536705808 BAP_BC_FSG_01_Header 0;
BA_ "GenSigSendType" SG_ 2536710912 BAP_BCmE_ASG_01_Header 3;
BA_ "GenSigSwitchedByIgnition" SG_ 2536710912 BAP_BCmE_ASG_01_Header 0;
BA_ "GenSigSendType" SG_ 2536710928 BAP_BCmE_FSG_01_Header 3;
BA_ "GenSigSwitchedByIgnition" SG_ 2536710928 BAP_BCmE_FSG_01_Header 0;
BA_ "GenSigSendType" SG_ 2536711680 BAP_Brake_ASG_01_Header 3;
BA_ "GenSigSwitchedByIgnition" SG_ 2536711680 BAP_Brake_ASG_01_Header 0;
BA_ "GenSigSendType" SG_ 2536711696 BAP_Brake_FSG_01_Header 3;
BA_ "GenSigSwitchedByIgnition" SG_ 2536711696 BAP_Brake_FSG_01_Header 0;
BA_ "GenSigSendType" SG_ 2536707841 BAP_Charisma_ASG_02_Header 3;
BA_ "GenSigSwitchedByIgnition" SG_ 2536707841 BAP_Charisma_ASG_02_Header 0;
BA_ "GenSigSendType" SG_ 2536707845 BAP_Charisma_ASG_06_Header 3;
BA_ "GenSigSwitchedByIgnition" SG_ 2536707845 BAP_Charisma_ASG_06_Header 0;
BA_ "GenSigSendType" SG_ 2536707856 BAP_Charisma_FSG_01_Header 3;
BA_ "GenSigSwitchedByIgnition" SG_ 2536707856 BAP_Charisma_FSG_01_Header 0;
BA_ "GenSigSendType" SG_ 2536767264 BAP_Debug_Cmd 3;
BA_ "GenSigSwitchedByIgnition" SG_ 2536767264 BAP_Debug_Cmd 0;
BA_ "GenSigSendType" SG_ 2536767280 BAP_Debug_Data 3;
BA_ "GenSigSwitchedByIgnition" SG_ 2536767280 BAP_Debug_Data 0;
BA_ "GenSigSendType" SG_ 2536719616 BAP_DisplayConfig_ASG_01_Header 3;
BA_ "GenSigSwitchedByIgnition" SG_ 2536719616 BAP_DisplayConfig_ASG_01_Header 0;
BA_ "GenSigSendType" SG_ 2536719617 BAP_DisplayConfig_ASG_02_Header 3;
BA_ "GenSigSwitchedByIgnition" SG_ 2536719617 BAP_DisplayConfig_ASG_02_Header 0;
BA_ "GenSigSendType" SG_ 2536719632 BAP_DisplayConfig_FSG_01_Header 3;
BA_ "GenSigSwitchedByIgnition" SG_ 2536719632 BAP_DisplayConfig_FSG_01_Header 0;
BA_ "GenSigSendType" SG_ 2536705282 BAP_Doorlocking_ASG_03_Header 3;
BA_ "GenSigSwitchedByIgnition" SG_ 2536705282 BAP_Doorlocking_ASG_03_Header 0;
BA_ "GenSigSendType" SG_ 2536705296 BAP_Doorlocking_FSG_01_Header 3;
BA_ "GenSigSwitchedByIgnition" SG_ 2536705296 BAP_Doorlocking_FSG_01_Header 0;
BA_ "GenSigSendType" SG_ 2536706816 BAP_Einheiten_ASG_01_Header 3;
BA_ "GenSigSwitchedByIgnition" SG_ 2536706816 BAP_Einheiten_ASG_01_Header 0;
BA_ "GenSigSendType" SG_ 2536706817 BAP_Einheiten_ASG_02_Header 3;
BA_ "GenSigSwitchedByIgnition" SG_ 2536706817 BAP_Einheiten_ASG_02_Header 0;
BA_ "GenSigSendType" SG_ 2536706818 BAP_Einheiten_ASG_03_Header 3;
BA_ "GenSigSwitchedByIgnition" SG_ 2536706818 BAP_Einheiten_ASG_03_Header 0;
BA_ "GenSigSendType" SG_ 2536706819 BAP_Einheiten_ASG_04_Header 3;
BA_ "GenSigSwitchedByIgnition" SG_ 2536706819 BAP_Einheiten_ASG_04_Header 0;
BA_ "GenSigSendType" SG_ 2536706832 BAP_Einheiten_FSG_01_Header 3;
BA_ "GenSigSwitchedByIgnition" SG_ 2536706832 BAP_Einheiten_FSG_01_Header 0;
BA_ "GenSigSendType" SG_ 2536702976 BAP_HUD_ASG_01_Header 3;
BA_ "GenSigSwitchedByIgnition" SG_ 2536702976 BAP_HUD_ASG_01_Header 0;
BA_ "GenSigSendType" SG_ 2536702977 BAP_HUD_ASG_02_Header 3;
BA_ "GenSigSwitchedByIgnition" SG_ 2536702977 BAP_HUD_ASG_02_Header 0;
BA_ "GenSigSendType" SG_ 2536702978 BAP_HUD_ASG_03_Header 3;
BA_ "GenSigSwitchedByIgnition" SG_ 2536702978 BAP_HUD_ASG_03_Header 0;
BA_ "GenSigSendType" SG_ 2536702992 BAP_HUD_FSG_01_Header 3;
BA_ "GenSigSwitchedByIgnition" SG_ 2536702992 BAP_HUD_FSG_01_Header 0;
BA_ "GenSigSendType" SG_ 2536709121 BAP_Hybrid_ASG_02_Header 3;
BA_ "GenSigSwitchedByIgnition" SG_ 2536709121 BAP_Hybrid_ASG_02_Header 0;
BA_ "GenSigSendType" SG_ 2536709136 BAP_Hybrid_FSG_01_Header 3;
BA_ "GenSigSwitchedByIgnition" SG_ 2536709136 BAP_Hybrid_FSG_01_Header 0;
BA_ "GenSigSendType" SG_ 2536722945 BAP_IAA_PSO_ASG_02_Header 3;
BA_ "GenSigSwitchedByIgnition" SG_ 2536722945 BAP_IAA_PSO_ASG_02_Header 0;
BA_ "GenSigSendType" SG_ 2536722960 BAP_IAA_PSO_FSG_01_Header 3;
BA_ "GenSigSwitchedByIgnition" SG_ 2536722960 BAP_IAA_PSO_FSG_01_Header 0;
BA_ "GenSigSendType" SG_ 2536708353 BAP_LDW_ASG_02_Header 3;
BA_ "GenSigSwitchedByIgnition" SG_ 2536708353 BAP_LDW_ASG_02_Header 0;
BA_ "GenSigSendType" SG_ 2536708368 BAP_LDW_FSG_01_Header 3;
BA_ "GenSigSwitchedByIgnition" SG_ 2536708368 BAP_LDW_FSG_01_Header 0;
BA_ "GenSigSendType" SG_ 2536732672 BAP_LLCC_ASG_01_Header 3;
BA_ "GenSigSwitchedByIgnition" SG_ 2536732672 BAP_LLCC_ASG_01_Header 0;
BA_ "GenSigSendType" SG_ 2536732688 BAP_LLCC_FSG_01_Header 3;
BA_ "GenSigSwitchedByIgnition" SG_ 2536732688 BAP_LLCC_FSG_01_Header 0;
BA_ "GenSigSendType" SG_ 2536715264 BAP_MFL_ASG_01_Header 3;
BA_ "GenSigSwitchedByIgnition" SG_ 2536715264 BAP_MFL_ASG_01_Header 0;
BA_ "GenSigSendType" SG_ 2536715280 BAP_MFL_FSG_01_Header 3;
BA_ "GenSigSwitchedByIgnition" SG_ 2536715280 BAP_MFL_FSG_01_Header 0;
BA_ "GenSigSendType" SG_ 2536714752 BAP_Navigation_ASG_01_Header 3;
BA_ "GenSigSwitchedByIgnition" SG_ 2536714752 BAP_Navigation_ASG_01_Header 0;
BA_ "GenSigSendType" SG_ 2536714753 BAP_Navigation_ASG_02_Header 3;
BA_ "GenSigSwitchedByIgnition" SG_ 2536714753 BAP_Navigation_ASG_02_Header 0;
BA_ "GenSigSendType" SG_ 2536714754 BAP_Navigation_ASG_03_Header 3;
BA_ "GenSigSwitchedByIgnition" SG_ 2536714754 BAP_Navigation_ASG_03_Header 0;
BA_ "GenSigSendType" SG_ 2536714755 BAP_Navigation_ASG_04_Header 3;
BA_ "GenSigSwitchedByIgnition" SG_ 2536714755 BAP_Navigation_ASG_04_Header 0;
BA_ "GenSigSendType" SG_ 2536714768 BAP_Navigation_FSG_01_Header 3;
BA_ "GenSigSwitchedByIgnition" SG_ 2536714768 BAP_Navigation_FSG_01_Header 0;
BA_ "GenSigSendType" SG_ 2536714769 BAP_Navigation_FSG_02_Header 3;
BA_ "GenSigSwitchedByIgnition" SG_ 2536714769 BAP_Navigation_FSG_02_Header 0;
BA_ "GenSigSendType" SG_ 2536708097 BAP_Nightvision_ASG_02_Header 3;
BA_ "GenSigSwitchedByIgnition" SG_ 2536708097 BAP_Nightvision_ASG_02_Header 0;
BA_ "GenSigSendType" SG_ 2536708112 BAP_Nightvision_FSG_01_Header 3;
BA_ "GenSigSendType" SG_ 2536712704 BAP_OnlineFunction_ASG_01_Header 3;
BA_ "GenSigSwitchedByIgnition" SG_ 2536712704 BAP_OnlineFunction_ASG_01_Header 0;
BA_ "GenSigSendType" SG_ 2536712705 BAP_OnlineFunction_ASG_02_Header 3;
BA_ "GenSigSwitchedByIgnition" SG_ 2536712705 BAP_OnlineFunction_ASG_02_Header 0;
BA_ "GenSigSendType" SG_ 2536712720 BAP_OnlineFunction_FSG_01_Header 3;
BA_ "GenSigSwitchedByIgnition" SG_ 2536712720 BAP_OnlineFunction_FSG_01_Header 0;
BA_ "GenSigSendType" SG_ 2536702723 BAP_ParkHeater_ASG_04_Header 3;
BA_ "GenSigSwitchedByIgnition" SG_ 2536702723 BAP_ParkHeater_ASG_04_Header 0;
BA_ "GenSigSendType" SG_ 2536702736 BAP_ParkHeater_FSG_01_Header 3;
BA_ "GenSigSwitchedByIgnition" SG_ 2536702736 BAP_ParkHeater_FSG_01_Header 0;
BA_ "GenSigSendType" SG_ 2536703745 BAP_RDK_ASG_02_Header 3;
BA_ "GenSigSwitchedByIgnition" SG_ 2536703745 BAP_RDK_ASG_02_Header 0;
BA_ "GenSigSendType" SG_ 2536703760 BAP_RDK_FSG_01_Header 3;
BA_ "GenSigSwitchedByIgnition" SG_ 2536703760 BAP_RDK_FSG_01_Header 0;
BA_ "GenSigSendType" SG_ 2536709889 BAP_RGS_ASG_02_Header 3;
BA_ "GenSigSwitchedByIgnition" SG_ 2536709889 BAP_RGS_ASG_02_Header 0;
BA_ "GenSigSendType" SG_ 2536709904 BAP_RGS_FSG_01_Header 3;
BA_ "GenSigSwitchedByIgnition" SG_ 2536709904 BAP_RGS_FSG_01_Header 0;
BA_ "GenSigSendType" SG_ 2536719872 BAP_SDS_ASG_01_Header 3;
BA_ "GenSigSwitchedByIgnition" SG_ 2536719872 BAP_SDS_ASG_01_Header 0;
BA_ "GenSigSendType" SG_ 2536719888 BAP_SDS_FSG_01_Header 3;
BA_ "GenSigSwitchedByIgnition" SG_ 2536719888 BAP_SDS_FSG_01_Header 0;
BA_ "GenSigSendType" SG_ 2536706560 BAP_SIA_ASG_01_Header 3;
BA_ "GenSigSwitchedByIgnition" SG_ 2536706560 BAP_SIA_ASG_01_Header 0;
BA_ "GenSigSendType" SG_ 2536706561 BAP_SIA_ASG_02_Header 3;
BA_ "GenSigSwitchedByIgnition" SG_ 2536706561 BAP_SIA_ASG_02_Header 0;
BA_ "GenSigSendType" SG_ 2536706562 BAP_SIA_ASG_03_Header 3;
BA_ "GenSigSwitchedByIgnition" SG_ 2536706562 BAP_SIA_ASG_03_Header 0;
BA_ "GenSigSendType" SG_ 2536706576 BAP_SIA_FSG_01_Header 3;
BA_ "GenSigSwitchedByIgnition" SG_ 2536706576 BAP_SIA_FSG_01_Header 0;
BA_ "GenSigSendType" SG_ 2536720896 BAP_Statistics_ASG_01_Header 3;
BA_ "GenSigSwitchedByIgnition" SG_ 2536720896 BAP_Statistics_ASG_01_Header 0;
BA_ "GenSigSendType" SG_ 2536720912 BAP_Statistics_FSG_01_Header 3;
BA_ "GenSigSwitchedByIgnition" SG_ 2536720912 BAP_Statistics_FSG_01_Header 0;
BA_ "GenSigSendType" SG_ 2536703489 BAP_SuspensionControl_ASG_02_Hea 3;
BA_ "GenSigSwitchedByIgnition" SG_ 2536703489 BAP_SuspensionControl_ASG_02_Hea 0;
BA_ "GenSigSendType" SG_ 2536703504 BAP_SuspensionControl_FSG_01_Hea 3;
BA_ "GenSigSwitchedByIgnition" SG_ 2536703504 BAP_SuspensionControl_FSG_01_Hea 0;
BA_ "GenSigSendType" SG_ 2536708609 BAP_SWA_ASG_02_Header 3;
BA_ "GenSigSwitchedByIgnition" SG_ 2536708609 BAP_SWA_ASG_02_Header 0;
BA_ "GenSigSendType" SG_ 2536708624 BAP_SWA_FSG_01_Header 3;
BA_ "GenSigSendType" SG_ 2536712448 BAP_Telefon2_ASG_01_Header 3;
BA_ "GenSigSwitchedByIgnition" SG_ 2536712448 BAP_Telefon2_ASG_01_Header 0;
BA_ "GenSigSendType" SG_ 2536712449 BAP_Telefon2_ASG_02_Header 3;
BA_ "GenSigSwitchedByIgnition" SG_ 2536712449 BAP_Telefon2_ASG_02_Header 0;
BA_ "GenSigSendType" SG_ 2536712464 BAP_Telefon2_FSG_01_Header 3;
BA_ "GenSigSwitchedByIgnition" SG_ 2536712464 BAP_Telefon2_FSG_01_Header 0;
BA_ "GenSigSendType" SG_ 2536712465 BAP_Telefon2_FSG_02_Header 3;
BA_ "GenSigSwitchedByIgnition" SG_ 2536712465 BAP_Telefon2_FSG_02_Header 0;
BA_ "GenSigSendType" SG_ 2536712192 BAP_Telefon_ASG_01_Header 3;
BA_ "GenSigSwitchedByIgnition" SG_ 2536712192 BAP_Telefon_ASG_01_Header 0;
BA_ "GenSigSendType" SG_ 2536712193 BAP_Telefon_ASG_02_Header 3;
BA_ "GenSigSwitchedByIgnition" SG_ 2536712193 BAP_Telefon_ASG_02_Header 0;
BA_ "GenSigSendType" SG_ 2536712194 BAP_Telefon_ASG_03_Header 3;
BA_ "GenSigSwitchedByIgnition" SG_ 2536712194 BAP_Telefon_ASG_03_Header 0;
BA_ "GenSigSendType" SG_ 2536712195 BAP_Telefon_ASG_04_Header 3;
BA_ "GenSigSwitchedByIgnition" SG_ 2536712195 BAP_Telefon_ASG_04_Header 0;
BA_ "GenSigSendType" SG_ 2536712208 BAP_Telefon_FSG_01_Header 3;
BA_ "GenSigSwitchedByIgnition" SG_ 2536712208 BAP_Telefon_FSG_01_Header 0;
BA_ "GenSigSendType" SG_ 2536712209 BAP_Telefon_FSG_02_Header 3;
BA_ "GenSigSwitchedByIgnition" SG_ 2536712209 BAP_Telefon_FSG_02_Header 0;
BA_ "GenSigSendType" SG_ 2536711169 BAP_TiltAngle_ASG_02_Header 3;
BA_ "GenSigSwitchedByIgnition" SG_ 2536711169 BAP_TiltAngle_ASG_02_Header 0;
BA_ "GenSigSendType" SG_ 2536711170 BAP_TiltAngle_ASG_03_Header 3;
BA_ "GenSigSwitchedByIgnition" SG_ 2536711170 BAP_TiltAngle_ASG_03_Header 0;
BA_ "GenSigSendType" SG_ 2536711184 BAP_TiltAngle_FSG_01_Header 3;
BA_ "GenSigSwitchedByIgnition" SG_ 2536711184 BAP_TiltAngle_FSG_01_Header 0;
BA_ "GenSigSendType" SG_ 2536706304 BAP_Uhrzeit_ASG_01_Header 3;
BA_ "GenSigSwitchedByIgnition" SG_ 2536706304 BAP_Uhrzeit_ASG_01_Header 0;
BA_ "GenSigSendType" SG_ 2536706305 BAP_Uhrzeit_ASG_02_Header 3;
BA_ "GenSigSwitchedByIgnition" SG_ 2536706305 BAP_Uhrzeit_ASG_02_Header 0;
BA_ "GenSigSendType" SG_ 2536706306 BAP_Uhrzeit_ASG_03_Header 3;
BA_ "GenSigSwitchedByIgnition" SG_ 2536706306 BAP_Uhrzeit_ASG_03_Header 0;
BA_ "GenSigSendType" SG_ 2536706308 BAP_Uhrzeit_ASG_05_Header 3;
BA_ "GenSigSwitchedByIgnition" SG_ 2536706308 BAP_Uhrzeit_ASG_05_Header 0;
BA_ "GenSigSendType" SG_ 2536706309 BAP_Uhrzeit_ASG_06_Header 3;
BA_ "GenSigSwitchedByIgnition" SG_ 2536706309 BAP_Uhrzeit_ASG_06_Header 0;
BA_ "GenSigSendType" SG_ 2536706310 BAP_Uhrzeit_ASG_07_Header 3;
BA_ "GenSigSwitchedByIgnition" SG_ 2536706310 BAP_Uhrzeit_ASG_07_Header 0;
BA_ "GenSigSendType" SG_ 2536706311 BAP_Uhrzeit_ASG_08_Header 3;
BA_ "GenSigSwitchedByIgnition" SG_ 2536706311 BAP_Uhrzeit_ASG_08_Header 0;
BA_ "GenSigSendType" SG_ 2536706320 BAP_Uhrzeit_FSG_01_Header 3;
BA_ "GenSigSwitchedByIgnition" SG_ 2536706320 BAP_Uhrzeit_FSG_01_Header 0;
BA_ "GenSigSendType" SG_ 2536710401 BAP_VZA_ASG_02_Header 3;
BA_ "GenSigSwitchedByIgnition" SG_ 2536710401 BAP_VZA_ASG_02_Header 0;
BA_ "GenSigSendType" SG_ 2536710416 BAP_VZA_FSG_01_Header 3;
BA_ "GenSigSwitchedByIgnition" SG_ 2536710416 BAP_VZA_FSG_01_Header 0;
BA_ "GenSigSendType" SG_ 1615 BCM1_Hinweis_Lichtnachlauf 3;
BA_ "GenSigSwitchedByIgnition" SG_ 1615 BCM1_Hinweis_Lichtnachlauf 0;
BA_ "GenSigSendType" SG_ 1615 BCM1_HUD_Eyeboxposition 3;
BA_ "GenSigSwitchedByIgnition" SG_ 1615 BCM1_HUD_Eyeboxposition 0;
BA_ "GenSigSendType" SG_ 1615 BCM1_HUD_Eyeboxposition_Status 3;
BA_ "GenSigSwitchedByIgnition" SG_ 1615 BCM1_HUD_Eyeboxposition_Status 0;
BA_ "GenSigSendType" SG_ 1615 BCM1_HUD_Taster 3;
BA_ "GenSigSwitchedByIgnition" SG_ 1615 BCM1_HUD_Taster 0;
BA_ "GenSigSendType" SG_ 1615 BCM1_LDS_Stellung 3;
BA_ "GenSigSwitchedByIgnition" SG_ 1615 BCM1_LDS_Stellung 0;
BA_ "Fehlerwert" SG_ 1615 BCM1_LDS_Stellung 7;
BA_ "GenSigSendType" SG_ 1615 BCM1_Lichtwarn_Texte 3;
BA_ "GenSigSwitchedByIgnition" SG_ 1615 BCM1_Lichtwarn_Texte 0;
BA_ "GenSigSendType" SG_ 1615 BCM1_Spannungs_Anf 3;
BA_ "GenSigSwitchedByIgnition" SG_ 1615 BCM1_Spannungs_Anf 0;
BA_ "GenSigSendType" SG_ 1615 BCM1_Status_Ladeanzeige 3;
BA_ "GenSigSwitchedByIgnition" SG_ 1615 BCM1_Status_Ladeanzeige 0;
BA_ "GenSigSendType" SG_ 1615 BCM1_Stellgroesse_Kl_58s 3;
BA_ "GenSigStartValue" SG_ 1615 BCM1_Stellgroesse_Kl_58s 126;
BA_ "GenSigSwitchedByIgnition" SG_ 1615 BCM1_Stellgroesse_Kl_58s 0;
BA_ "Fehlerwert" SG_ 1615 BCM1_Stellgroesse_Kl_58s 127;
BA_ "GenSigSendType" SG_ 1615 CHA_Drehschalter_Modus 3;
BA_ "GenSigSwitchedByIgnition" SG_ 1615 CHA_Drehschalter_Modus 0;
BA_ "Fehlerwert" SG_ 1615 CHA_Drehschalter_Modus 15;
BA_ "GenSigSendType" SG_ 1615 CHA_Kombi_Texte 3;
BA_ "GenSigSwitchedByIgnition" SG_ 1615 CHA_Kombi_Texte 0;
BA_ "GenSigSendType" SG_ 1615 KRH_Stufe_LED_li 3;
BA_ "GenSigSwitchedByIgnition" SG_ 1615 KRH_Stufe_LED_li 0;
BA_ "GenSigSendType" SG_ 1615 KRH_Stufe_LED_re 3;
BA_ "GenSigSwitchedByIgnition" SG_ 1615 KRH_Stufe_LED_re 0;
BA_ "GenSigSendType" SG_ 1615 LV_Laserlicht_Texte 0;
BA_ "GenSigSwitchedByIgnition" SG_ 1615 LV_Laserlicht_Texte 0;
BA_ "GenSigSendType" SG_ 1615 LV_LED_Scheinwerfer_li_def 0;
BA_ "GenSigSwitchedByIgnition" SG_ 1615 LV_LED_Scheinwerfer_li_def 0;
BA_ "GenSigSendType" SG_ 1615 LV_LED_Scheinwerfer_re_def 0;
BA_ "GenSigSwitchedByIgnition" SG_ 1615 LV_LED_Scheinwerfer_re_def 0;
BA_ "GenSigSendType" SG_ 1626 APS_Tongeber_defekt 3;
BA_ "GenSigSwitchedByIgnition" SG_ 1626 APS_Tongeber_defekt 0;
BA_ "GenSigSendType" SG_ 1626 BCM1_AFS_Lampe 3;
BA_ "GenSigSwitchedByIgnition" SG_ 1626 BCM1_AFS_Lampe 0;
BA_ "GenSigSendType" SG_ 1626 BCM1_EasyEntry_Status 3;
BA_ "GenSigSwitchedByIgnition" SG_ 1626 BCM1_EasyEntry_Status 0;
BA_ "GenSigSendType" SG_ 1626 BCM1_Fahrlicht_Hinweis 3;
BA_ "GenSigSwitchedByIgnition" SG_ 1626 BCM1_Fahrlicht_Hinweis 0;
BA_ "GenSigSendType" SG_ 1626 BCM1_Hinweis_Lichtnachlauf 3;
BA_ "GenSigSwitchedByIgnition" SG_ 1626 BCM1_Hinweis_Lichtnachlauf 0;
BA_ "GenSigSendType" SG_ 1626 BCM1_Kl_15_HW_erkannt 3;
BA_ "GenSigSwitchedByIgnition" SG_ 1626 BCM1_Kl_15_HW_erkannt 0;
BA_ "GenSigSendType" SG_ 1626 BCM1_Kl_15_Sig_HW_erkannt 3;
BA_ "GenSigSwitchedByIgnition" SG_ 1626 BCM1_Kl_15_Sig_HW_erkannt 0;
BA_ "GenSigSendType" SG_ 1626 BCM1_LDS_Stellung 3;
BA_ "GenSigSwitchedByIgnition" SG_ 1626 BCM1_LDS_Stellung 0;
BA_ "Fehlerwert" SG_ 1626 BCM1_LDS_Stellung 7;
BA_ "GenSigSendType" SG_ 1626 BCM1_Lenksaeule_aktiv 3;
BA_ "GenSigSwitchedByIgnition" SG_ 1626 BCM1_Lenksaeule_aktiv 0;
BA_ "GenSigSendType" SG_ 1626 BCM1_Licht_Warn 3;
BA_ "GenSigSwitchedByIgnition" SG_ 1626 BCM1_Licht_Warn 0;
BA_ "GenSigSendType" SG_ 1626 BCM1_Lichtwarn_Texte 3;
BA_ "GenSigSwitchedByIgnition" SG_ 1626 BCM1_Lichtwarn_Texte 0;
BA_ "GenSigSendType" SG_ 1626 BCM1_MH_Schalter 3;
BA_ "GenSigSwitchedByIgnition" SG_ 1626 BCM1_MH_Schalter 0;
BA_ "GenSigSendType" SG_ 1626 BCM1_MH_WIV_Schalter 3;
BA_ "GenSigSwitchedByIgnition" SG_ 1626 BCM1_MH_WIV_Schalter 0;
BA_ "GenSigActiveRepetitions" SG_ 1626 BCM1_NV_Taster 10;
BA_ "GenSigSendType" SG_ 1626 BCM1_NV_Taster 4;
BA_ "GenSigSwitchedByIgnition" SG_ 1626 BCM1_NV_Taster 0;
BA_ "GenSigSendType" SG_ 1626 BCM1_Reisemodus_Texte 3;
BA_ "GenSigSwitchedByIgnition" SG_ 1626 BCM1_Reisemodus_Texte 0;
BA_ "GenSigSendType" SG_ 1626 BCM1_Rueckfahrlicht_Schalter 3;
BA_ "GenSigSwitchedByIgnition" SG_ 1626 BCM1_Rueckfahrlicht_Schalter 0;
BA_ "GenSigSendType" SG_ 1626 BCM1_Schluesselsuche_Anf 0;
BA_ "GenSigSwitchedByIgnition" SG_ 1626 BCM1_Schluesselsuche_Anf 0;
BA_ "GenSigSendType" SG_ 1626 BCM1_St_SW_Diebstahl_links 3;
BA_ "GenSigSwitchedByIgnition" SG_ 1626 BCM1_St_SW_Diebstahl_links 0;
BA_ "GenSigSendType" SG_ 1626 BCM1_St_SW_Diebstahl_rechts 3;
BA_ "GenSigSwitchedByIgnition" SG_ 1626 BCM1_St_SW_Diebstahl_rechts 0;
BA_ "GenSigActiveRepetitions" SG_ 1626 BCM1_Valet_Parking_Taster 10;
BA_ "GenSigSendType" SG_ 1626 BCM1_Valet_Parking_Taster 4;
BA_ "GenSigSwitchedByIgnition" SG_ 1626 BCM1_Valet_Parking_Taster 0;
BA_ "GenSigActiveRepetitions" SG_ 1626 BCM1_Warnblink_Taster 10;
BA_ "GenSigSendType" SG_ 1626 BCM1_Warnblink_Taster 4;
BA_ "GenSigSwitchedByIgnition" SG_ 1626 BCM1_Warnblink_Taster 0;
BA_ "GenSigSendType" SG_ 1626 BCM_Bremsbelag_Sensor 3;
BA_ "GenSigSwitchedByIgnition" SG_ 1626 BCM_Bremsbelag_Sensor 0;
BA_ "GenSigSendType" SG_ 1626 BCM_Bremsfluessigkeit_Sensor 3;
BA_ "GenSigSwitchedByIgnition" SG_ 1626 BCM_Bremsfluessigkeit_Sensor 0;
BA_ "GenSigSendType" SG_ 1626 BCM_Eco_Charisma_Taste 3;
BA_ "GenSigSwitchedByIgnition" SG_ 1626 BCM_Eco_Charisma_Taste 0;
BA_ "GenSigSendType" SG_ 1626 BCM_HDF_betaetigt 3;
BA_ "GenSigSwitchedByIgnition" SG_ 1626 BCM_HDF_betaetigt 0;
BA_ "GenSigActiveRepetitions" SG_ 1626 BCM_Hybrid_StartStopp_Taste 10;
BA_ "GenSigSendType" SG_ 1626 BCM_Hybrid_StartStopp_Taste 4;
BA_ "GenSigSwitchedByIgnition" SG_ 1626 BCM_Hybrid_StartStopp_Taste 0;
BA_ "GenSigSendType" SG_ 1626 BCM_Hybrid_StSt_Taste_Fehler 0;
BA_ "GenSigSwitchedByIgnition" SG_ 1626 BCM_Hybrid_StSt_Taste_Fehler 0;
BA_ "GenSigSendType" SG_ 1626 BCM_Kuehlmittel_Sensor 3;
BA_ "GenSigSwitchedByIgnition" SG_ 1626 BCM_Kuehlmittel_Sensor 0;
BA_ "GenSigSendType" SG_ 1626 BCM_Kuehlmittel_Sensor_02 3;
BA_ "GenSigSwitchedByIgnition" SG_ 1626 BCM_Kuehlmittel_Sensor_02 0;
BA_ "GenSigSendType" SG_ 1626 BCM_Offroad_Taste 3;
BA_ "GenSigSwitchedByIgnition" SG_ 1626 BCM_Offroad_Taste 0;
BA_ "GenSigSendType" SG_ 1626 BCM_Waschwasser_Sensor 3;
BA_ "GenSigSwitchedByIgnition" SG_ 1626 BCM_Waschwasser_Sensor 0;
BA_ "GenSigSendType" SG_ 1626 Gong_TFL_Umschaltung 3;
BA_ "GenSigSwitchedByIgnition" SG_ 1626 Gong_TFL_Umschaltung 0;
BA_ "GenSigSendType" SG_ 1626 ISP_Dimmung_ASP_02 3;
BA_ "GenSigSendType" SG_ 1626 UGDO_Function_01 3;
BA_ "Fehlerwert" SG_ 1626 UGDO_Function_01 7;
BA_ "GenSigActiveRepetitions" SG_ 672 BCM2_Crashfall_erkannt 5;
BA_ "GenSigSendType" SG_ 672 BCM2_Crashfall_erkannt 6;
BA_ "GenSigSwitchedByIgnition" SG_ 672 BCM2_Crashfall_erkannt 0;
BA_ "GenSigSendType" SG_ 672 BCM2_Freigabe_Kofferr_Innenentr 0;
BA_ "GenSigSwitchedByIgnition" SG_ 672 BCM2_Freigabe_Kofferr_Innenentr 0;
BA_ "GenSigSendType" SG_ 672 BCM2_KL15_Absch_FT 3;
BA_ "GenSigSwitchedByIgnition" SG_ 672 BCM2_KL15_Absch_FT 0;
BA_ "GenSigSendType" SG_ 672 BCM2_P_verriegelt 3;
BA_ "GenSigSwitchedByIgnition" SG_ 672 BCM2_P_verriegelt 0;
BA_ "GenSigActiveRepetitions" SG_ 672 BCM2_Quittierung_Warnton_aktiv 5;
BA_ "GenSigSendType" SG_ 672 BCM2_Quittierung_Warnton_aktiv 4;
BA_ "GenSigSwitchedByIgnition" SG_ 672 BCM2_Quittierung_Warnton_aktiv 0;
BA_ "GenSigSendType" SG_ 672 BCM2_SST_gedrueckt 3;
BA_ "GenSigSwitchedByIgnition" SG_ 672 BCM2_SST_gedrueckt 0;
BA_ "GenSigActiveRepetitions" SG_ 672 BCM2_T_Deckel_Vorne 11;
BA_ "GenSigSendType" SG_ 672 BCM2_T_Deckel_Vorne 4;
BA_ "GenSigSwitchedByIgnition" SG_ 672 BCM2_T_Deckel_Vorne 0;
BA_ "GenSigSendType" SG_ 672 BCM2_TrunkEntrapment_Warn 0;
BA_ "GenSigSwitchedByIgnition" SG_ 672 BCM2_TrunkEntrapment_Warn 0;
BA_ "GenSigSendType" SG_ 672 BCM2_Unterdr_Zuendungsmeldung 3;
BA_ "GenSigSwitchedByIgnition" SG_ 672 BCM2_Unterdr_Zuendungsmeldung 0;
BA_ "GenSigSendType" SG_ 672 BCM_02_BZ 0;
BA_ "GenSigFuncType" SG_ 672 BCM_02_BZ 1;
BA_ "GenSigSwitchedByIgnition" SG_ 672 BCM_02_BZ 0;
BA_ "GenSigSendType" SG_ 672 BCM_02_CRC 0;
BA_ "GenSigFuncType" SG_ 672 BCM_02_CRC 2;
BA_ "GenSigSwitchedByIgnition" SG_ 672 BCM_02_CRC 0;
BA_ "GenSigActiveRepetitions" SG_ 672 BCM_Anf_Aussenwarnung 5;
BA_ "GenSigSendType" SG_ 672 BCM_Anf_Aussenwarnung 4;
BA_ "GenSigSwitchedByIgnition" SG_ 672 BCM_Anf_Aussenwarnung 0;
BA_ "GenSigSendType" SG_ 672 BCM_Aussenwarnung_Konfig 3;
BA_ "GenSigSwitchedByIgnition" SG_ 672 BCM_Aussenwarnung_Konfig 0;
BA_ "GenSigSendType" SG_ 672 BCM_Handbremse_Hinweis 3;
BA_ "GenSigSwitchedByIgnition" SG_ 672 BCM_Handbremse_Hinweis 0;
BA_ "GenSigSendType" SG_ 672 BCM_RLU_Wakeup_Anforderung 0;
BA_ "GenSigSwitchedByIgnition" SG_ 672 BCM_RLU_Wakeup_Anforderung 0;
BA_ "GenSigSendType" SG_ 672 BCM_ValetTaster_Fkts_LED 3;
BA_ "GenSigSwitchedByIgnition" SG_ 672 BCM_ValetTaster_Fkts_LED 0;
BA_ "GenSigActiveRepetitions" SG_ 672 BCM_Waehlhebel_P_Hinweis 5;
BA_ "GenSigSendType" SG_ 672 BCM_Waehlhebel_P_Hinweis 4;
BA_ "GenSigSwitchedByIgnition" SG_ 672 BCM_Waehlhebel_P_Hinweis 0;
BA_ "GenSigSendType" SG_ 672 FA_Hoehenwert_HL_01 3;
BA_ "GenSigStartValue" SG_ 672 FA_Hoehenwert_HL_01 254;
BA_ "Fehlerwert" SG_ 672 FA_Hoehenwert_HL_01 255;
BA_ "GenSigSendType" SG_ 672 FA_Hoehenwert_VL_01 3;
BA_ "GenSigStartValue" SG_ 672 FA_Hoehenwert_VL_01 254;
BA_ "Fehlerwert" SG_ 672 FA_Hoehenwert_VL_01 255;
BA_ "GenSigSendType" SG_ 672 FSH_LED 3;
BA_ "GenSigSwitchedByIgnition" SG_ 672 FSH_LED 0;
BA_ "GenSigActiveRepetitions" SG_ 672 Heckrollo_Privacy_aktiv 25;
BA_ "GenSigSendType" SG_ 672 Heckrollo_Privacy_aktiv 4;
BA_ "GenSigSwitchedByIgnition" SG_ 672 Heckrollo_Privacy_aktiv 0;
BA_ "GenSigActiveRepetitions" SG_ 672 Heckrollo_Verfahrrichtung 25;
BA_ "GenSigSendType" SG_ 672 Heckrollo_Verfahrrichtung 4;
BA_ "GenSigSwitchedByIgnition" SG_ 672 Heckrollo_Verfahrrichtung 0;
BA_ "GenSigSendType" SG_ 672 Heckwischer_Status 3;
BA_ "GenSigSwitchedByIgnition" SG_ 672 Heckwischer_Status 0;
BA_ "GenSigSendType" SG_ 672 HSH_LED 3;
BA_ "GenSigSwitchedByIgnition" SG_ 672 HSH_LED 0;
BA_ "GenSigSendType" SG_ 672 Niveausensor_HL_verbaut 3;
BA_ "GenSigSwitchedByIgnition" SG_ 672 Niveausensor_HL_verbaut 0;
BA_ "GenSigSendType" SG_ 672 Niveausensor_VL_verbaut 3;
BA_ "GenSigSwitchedByIgnition" SG_ 672 Niveausensor_VL_verbaut 0;
BA_ "GenSigActiveRepetitions" SG_ 672 Remote_Rollo_HBFS_hoch 10;
BA_ "GenSigSendType" SG_ 672 Remote_Rollo_HBFS_hoch 4;
BA_ "GenSigSwitchedByIgnition" SG_ 672 Remote_Rollo_HBFS_hoch 0;
BA_ "GenSigActiveRepetitions" SG_ 672 Remote_Rollo_HBFS_tief 10;
BA_ "GenSigSendType" SG_ 672 Remote_Rollo_HBFS_tief 4;
BA_ "GenSigSwitchedByIgnition" SG_ 672 Remote_Rollo_HBFS_tief 0;
BA_ "GenSigActiveRepetitions" SG_ 672 Remote_Rollo_HFS_hoch 10;
BA_ "GenSigSendType" SG_ 672 Remote_Rollo_HFS_hoch 4;
BA_ "GenSigSwitchedByIgnition" SG_ 672 Remote_Rollo_HFS_hoch 0;
BA_ "GenSigActiveRepetitions" SG_ 672 Remote_Rollo_HFS_tief 10;
BA_ "GenSigSendType" SG_ 672 Remote_Rollo_HFS_tief 4;
BA_ "GenSigSwitchedByIgnition" SG_ 672 Remote_Rollo_HFS_tief 0;
BA_ "GenSigSendType" SG_ 672 ZZH_Endlage_oben 3;
BA_ "GenSigSwitchedByIgnition" SG_ 672 ZZH_Endlage_oben 0;
BA_ "GenSigSendType" SG_ 672 ZZH_Endlage_unplausibel 3;
BA_ "GenSigSwitchedByIgnition" SG_ 672 ZZH_Endlage_unplausibel 0;
BA_ "GenSigSendType" SG_ 672 ZZH_Endlage_unten 3;
BA_ "GenSigSwitchedByIgnition" SG_ 672 ZZH_Endlage_unten 0;
BA_ "GenSigSendType" SG_ 2527679637 BCM_LTM_Allwetterl_Status 3;
BA_ "GenSigSwitchedByIgnition" SG_ 2527679637 BCM_LTM_Allwetterl_Status 0;
BA_ "GenSigSendType" SG_ 2527679637 BCM_LTM_Nebell_Status 3;
BA_ "GenSigSwitchedByIgnition" SG_ 2527679637 BCM_LTM_Nebell_Status 0;
BA_ "GenSigSendType" SG_ 2527679637 BCM_LTM_Nebelschluss_Status 3;
BA_ "GenSigSwitchedByIgnition" SG_ 2527679637 BCM_LTM_Nebelschluss_Status 0;
BA_ "GenSigSendType" SG_ 2527679637 BCM_LTM_PopUp_Anf 3;
BA_ "GenSigSwitchedByIgnition" SG_ 2527679637 BCM_LTM_PopUp_Anf 0;
BA_ "GenSigSendType" SG_ 2527679637 BCM_LTM_PopUp_Inhalt 3;
BA_ "GenSigSwitchedByIgnition" SG_ 2527679637 BCM_LTM_PopUp_Inhalt 0;
BA_ "GenSigSendType" SG_ 2527679637 BCM_LTM_PopUp_Status 3;
BA_ "GenSigSwitchedByIgnition" SG_ 2527679637 BCM_LTM_PopUp_Status 0;
BA_ "GenSigSendType" SG_ 2527679637 BCM_LTM_PopUp_Texte 3;
BA_ "GenSigSwitchedByIgnition" SG_ 2527679637 BCM_LTM_PopUp_Texte 0;
BA_ "GenSigSendType" SG_ 2527679637 CPD_Warnung 3;
BA_ "GenSigSwitchedByIgnition" SG_ 2527679637 CPD_Warnung 0;
BA_ "GenSigSendType" SG_ 2463978607 BCM_RGB_Blau 3;
BA_ "GenSigSwitchedByIgnition" SG_ 2463978607 BCM_RGB_Blau 0;
BA_ "GenSigSendType" SG_ 2463978607 BCM_RGB_Gruen 3;
BA_ "GenSigSwitchedByIgnition" SG_ 2463978607 BCM_RGB_Gruen 0;
BA_ "GenSigSendType" SG_ 2463978607 BCM_RGB_Rot 3;
BA_ "GenSigSwitchedByIgnition" SG_ 2463978607 BCM_RGB_Rot 0;
BA_ "GenSigActiveRepetitions" SG_ 870 Blinken_li_Fzg_Takt 5;
BA_ "GenSigSendType" SG_ 870 Blinken_li_Fzg_Takt 4;
BA_ "GenSigSwitchedByIgnition" SG_ 870 Blinken_li_Fzg_Takt 0;
BA_ "GenSigActiveRepetitions" SG_ 870 Blinken_li_Kombi_Takt 5;
BA_ "GenSigSendType" SG_ 870 Blinken_li_Kombi_Takt 4;
BA_ "GenSigSwitchedByIgnition" SG_ 870 Blinken_li_Kombi_Takt 0;
BA_ "GenSigActiveRepetitions" SG_ 870 Blinken_re_Fzg_Takt 5;
BA_ "GenSigSendType" SG_ 870 Blinken_re_Fzg_Takt 4;
BA_ "GenSigSwitchedByIgnition" SG_ 870 Blinken_re_Fzg_Takt 0;
BA_ "GenSigActiveRepetitions" SG_ 870 Blinken_re_Kombi_Takt 5;
BA_ "GenSigSendType" SG_ 870 Blinken_re_Kombi_Takt 4;
BA_ "GenSigSwitchedByIgnition" SG_ 870 Blinken_re_Kombi_Takt 0;
BA_ "GenSigActiveRepetitions" SG_ 870 BM_Autobahn 5;
BA_ "GenSigSendType" SG_ 870 BM_Autobahn 4;
BA_ "GenSigSwitchedByIgnition" SG_ 870 BM_Autobahn 0;
BA_ "GenSigActiveRepetitions" SG_ 870 BM_Crash 5;
BA_ "GenSigSendType" SG_ 870 BM_Crash 4;
BA_ "GenSigSwitchedByIgnition" SG_ 870 BM_Crash 0;
BA_ "GenSigActiveRepetitions" SG_ 870 BM_DWA_Alarm 5;
BA_ "GenSigSendType" SG_ 870 BM_DWA_Alarm 4;
BA_ "GenSigSwitchedByIgnition" SG_ 870 BM_DWA_Alarm 0;
BA_ "GenSigActiveRepetitions" SG_ 870 BM_DWA_ein 5;
BA_ "GenSigSendType" SG_ 870 BM_DWA_ein 4;
BA_ "GenSigSwitchedByIgnition" SG_ 870 BM_DWA_ein 0;
BA_ "GenSigActiveRepetitions" SG_ 870 BM_GDO 5;
BA_ "GenSigSendType" SG_ 870 BM_GDO 4;
BA_ "GenSigSwitchedByIgnition" SG_ 870 BM_GDO 0;
BA_ "GenSigActiveRepetitions" SG_ 870 BM_HD_Oeffnung_angelernt 5;
BA_ "GenSigSendType" SG_ 870 BM_HD_Oeffnung_angelernt 4;
BA_ "GenSigSwitchedByIgnition" SG_ 870 BM_HD_Oeffnung_angelernt 0;
BA_ "GenSigActiveRepetitions" SG_ 870 BM_links 5;
BA_ "GenSigSendType" SG_ 870 BM_links 4;
BA_ "GenSigSwitchedByIgnition" SG_ 870 BM_links 0;
BA_ "GenSigActiveRepetitions" SG_ 870 BM_NBA_n_codiert_n_aktiv 5;
BA_ "GenSigSendType" SG_ 870 BM_NBA_n_codiert_n_aktiv 4;
BA_ "GenSigStartValue" SG_ 870 BM_NBA_n_codiert_n_aktiv 1;
BA_ "GenSigSwitchedByIgnition" SG_ 870 BM_NBA_n_codiert_n_aktiv 0;
BA_ "GenSigActiveRepetitions" SG_ 870 BM_NBA_Status 5;
BA_ "GenSigSendType" SG_ 870 BM_NBA_Status 4;
BA_ "GenSigSwitchedByIgnition" SG_ 870 BM_NBA_Status 0;
BA_ "GenSigActiveRepetitions" SG_ 870 BM_Not_Bremsung 5;
BA_ "GenSigSendType" SG_ 870 BM_Not_Bremsung 4;
BA_ "GenSigSwitchedByIgnition" SG_ 870 BM_Not_Bremsung 0;
BA_ "GenSigActiveRepetitions" SG_ 870 BM_Panik 5;
BA_ "GenSigSendType" SG_ 870 BM_Panik 4;
BA_ "GenSigSwitchedByIgnition" SG_ 870 BM_Panik 0;
BA_ "GenSigActiveRepetitions" SG_ 870 BM_PiloPa 5;
BA_ "GenSigSendType" SG_ 870 BM_PiloPa 4;
BA_ "GenSigSwitchedByIgnition" SG_ 870 BM_PiloPa 0;
BA_ "GenSigActiveRepetitions" SG_ 870 BM_Recas 5;
BA_ "GenSigSendType" SG_ 870 BM_Recas 4;
BA_ "GenSigSwitchedByIgnition" SG_ 870 BM_Recas 0;
BA_ "GenSigActiveRepetitions" SG_ 870 BM_rechts 5;
BA_ "GenSigSendType" SG_ 870 BM_rechts 4;
BA_ "GenSigSwitchedByIgnition" SG_ 870 BM_rechts 0;
BA_ "GenSigActiveRepetitions" SG_ 870 BM_Rollenmodus_Blinken 5;
BA_ "GenSigSendType" SG_ 870 BM_Rollenmodus_Blinken 4;
BA_ "GenSigSwitchedByIgnition" SG_ 870 BM_Rollenmodus_Blinken 0;
BA_ "GenSigActiveRepetitions" SG_ 870 BM_Taxi_Notalarm 5;
BA_ "GenSigSendType" SG_ 870 BM_Taxi_Notalarm 4;
BA_ "GenSigSwitchedByIgnition" SG_ 870 BM_Taxi_Notalarm 0;
BA_ "GenSigActiveRepetitions" SG_ 870 BM_Telematik 5;
BA_ "GenSigSendType" SG_ 870 BM_Telematik 4;
BA_ "GenSigSwitchedByIgnition" SG_ 870 BM_Telematik 0;
BA_ "GenSigActiveRepetitions" SG_ 870 BM_Telematik_Abbruchgrund 5;
BA_ "GenSigSendType" SG_ 870 BM_Telematik_Abbruchgrund 4;
BA_ "GenSigSwitchedByIgnition" SG_ 870 BM_Telematik_Abbruchgrund 0;
BA_ "GenSigActiveRepetitions" SG_ 870 BM_Warnblinken 5;
BA_ "GenSigSendType" SG_ 870 BM_Warnblinken 4;
BA_ "GenSigSwitchedByIgnition" SG_ 870 BM_Warnblinken 0;
BA_ "GenSigActiveRepetitions" SG_ 870 BM_WBT_Beleuchtung 5;
BA_ "GenSigSendType" SG_ 870 BM_WBT_Beleuchtung 4;
BA_ "GenSigSwitchedByIgnition" SG_ 870 BM_WBT_Beleuchtung 0;
BA_ "GenSigActiveRepetitions" SG_ 870 BM_Wischblinken 5;
BA_ "GenSigSendType" SG_ 870 BM_Wischblinken 4;
BA_ "GenSigSwitchedByIgnition" SG_ 870 BM_Wischblinken 0;
BA_ "GenSigActiveRepetitions" SG_ 870 BM_ZV_auf 5;
BA_ "GenSigSendType" SG_ 870 BM_ZV_auf 4;
BA_ "GenSigSwitchedByIgnition" SG_ 870 BM_ZV_auf 0;
BA_ "GenSigActiveRepetitions" SG_ 870 BM_ZV_zu 5;
BA_ "GenSigSendType" SG_ 870 BM_ZV_zu 4;
BA_ "GenSigSwitchedByIgnition" SG_ 870 BM_ZV_zu 0;
BA_ "GenSigSendType" SG_ 870 DWA_Alarmquelle 3;
BA_ "GenSigStartValue" SG_ 870 DWA_Alarmquelle 30;
BA_ "GenSigSwitchedByIgnition" SG_ 870 DWA_Alarmquelle 0;
BA_ "Fehlerwert" SG_ 870 DWA_Alarmquelle 31;
BA_ "GenSigActiveRepetitions" SG_ 868 NBlinken_li_Fzg_Takt 5;
BA_ "GenSigSendType" SG_ 868 NBlinken_li_Fzg_Takt 6;
BA_ "GenSigSwitchedByIgnition" SG_ 868 NBlinken_li_Fzg_Takt 0;
BA_ "GenSigActiveRepetitions" SG_ 868 NBlinken_li_Kombi_Takt 5;
BA_ "GenSigSendType" SG_ 868 NBlinken_li_Kombi_Takt 6;
BA_ "GenSigSwitchedByIgnition" SG_ 868 NBlinken_li_Kombi_Takt 0;
BA_ "GenSigActiveRepetitions" SG_ 868 NBlinken_re_Fzg_Takt 5;
BA_ "GenSigSendType" SG_ 868 NBlinken_re_Fzg_Takt 6;
BA_ "GenSigSwitchedByIgnition" SG_ 868 NBlinken_re_Fzg_Takt 0;
BA_ "GenSigActiveRepetitions" SG_ 868 NBlinken_re_Kombi_Takt 5;
BA_ "GenSigSendType" SG_ 868 NBlinken_re_Kombi_Takt 6;
BA_ "GenSigSwitchedByIgnition" SG_ 868 NBlinken_re_Kombi_Takt 0;
BA_ "GenSigSendType" SG_ 687 BMS_As_Entladezaehler 0;
BA_ "GenSigSwitchedByIgnition" SG_ 687 BMS_As_Entladezaehler 0;
BA_ "GenSigSendType" SG_ 687 BMS_As_Entladezaehler_Ueberlauf 0;
BA_ "GenSigSwitchedByIgnition" SG_ 687 BMS_As_Entladezaehler_Ueberlauf 0;
BA_ "GenSigSendType" SG_ 687 BMS_Rekuperation 0;
BA_ "GenSigSwitchedByIgnition" SG_ 687 BMS_Rekuperation 0;
BA_ "GenSigSendType" SG_ 687 BMS_Rekuperation_Ueberlauf 0;
BA_ "GenSigSwitchedByIgnition" SG_ 687 BMS_Rekuperation_Ueberlauf 0;
BA_ "GenSigSendType" SG_ 687 BMS_Verbrauch 0;
BA_ "GenSigSwitchedByIgnition" SG_ 687 BMS_Verbrauch 0;
BA_ "GenSigSendType" SG_ 687 BMS_Verbrauch_Ueberlauf 0;
BA_ "GenSigSwitchedByIgnition" SG_ 687 BMS_Verbrauch_Ueberlauf 0;
BA_ "GenSigSendType" SG_ 1438 BMS_Batterie_Voko_Anf 0;
BA_ "GenSigSwitchedByIgnition" SG_ 1438 BMS_Batterie_Voko_Anf 0;
BA_ "GenSigSendType" SG_ 1438 BMS_Fehler_NTKreis 0;
BA_ "GenSigSwitchedByIgnition" SG_ 1438 BMS_Fehler_NTKreis 0;
BA_ "Fehlerwert" SG_ 1438 BMS_Fehler_NTKreis 1;
BA_ "GenSigSendType" SG_ 1438 BMS_Fehlerstatus_EWP_02 0;
BA_ "GenSigSwitchedByIgnition" SG_ 1438 BMS_Fehlerstatus_EWP_02 0;
BA_ "Fehlerwert" SG_ 1438 BMS_Fehlerstatus_EWP_02 7;
BA_ "GenSigSendType" SG_ 1438 BMS_IstRuecklaufTemperatur_02 0;
BA_ "GenSigStartValue" SG_ 1438 BMS_IstRuecklaufTemperatur_02 254;
BA_ "GenSigSwitchedByIgnition" SG_ 1438 BMS_IstRuecklaufTemperatur_02 0;
BA_ "Fehlerwert" SG_ 1438 BMS_IstRuecklaufTemperatur_02 255;
BA_ "GenSigSendType" SG_ 1438 BMS_IstVorlaufTemperatur 0;
BA_ "GenSigStartValue" SG_ 1438 BMS_IstVorlaufTemperatur 254;
BA_ "GenSigSwitchedByIgnition" SG_ 1438 BMS_IstVorlaufTemperatur 0;
BA_ "Fehlerwert" SG_ 1438 BMS_IstVorlaufTemperatur 255;
BA_ "GenSigSendType" SG_ 1438 BMS_Soll_PWM_Pumpe 0;
BA_ "GenSigStartValue" SG_ 1438 BMS_Soll_PWM_Pumpe 15;
BA_ "GenSigSwitchedByIgnition" SG_ 1438 BMS_Soll_PWM_Pumpe 0;
BA_ "Fehlerwert" SG_ 1438 BMS_Soll_PWM_Pumpe 14;
BA_ "GenSigSendType" SG_ 1438 BMS_SollVolumenstrom 0;
BA_ "GenSigStartValue" SG_ 1438 BMS_SollVolumenstrom 62;
BA_ "GenSigSwitchedByIgnition" SG_ 1438 BMS_SollVolumenstrom 0;
BA_ "Fehlerwert" SG_ 1438 BMS_SollVolumenstrom 63;
BA_ "GenSigSendType" SG_ 1438 BMS_SollVorlauftemperatur 0;
BA_ "GenSigStartValue" SG_ 1438 BMS_SollVorlauftemperatur 254;
BA_ "GenSigSwitchedByIgnition" SG_ 1438 BMS_SollVorlauftemperatur 0;
BA_ "Fehlerwert" SG_ 1438 BMS_SollVorlauftemperatur 255;
BA_ "GenSigSendType" SG_ 1438 BMS_Status_Ventil 0;
BA_ "GenSigStartValue" SG_ 1438 BMS_Status_Ventil 6;
BA_ "GenSigSwitchedByIgnition" SG_ 1438 BMS_Status_Ventil 0;
BA_ "Fehlerwert" SG_ 1438 BMS_Status_Ventil 7;
BA_ "GenSigSendType" SG_ 1438 BMS_Temp_Epsilon 0;
BA_ "GenSigSwitchedByIgnition" SG_ 1438 BMS_Temp_Epsilon 0;
BA_ "GenSigSendType" SG_ 1438 BMS_Temperatur 0;
BA_ "GenSigStartValue" SG_ 1438 BMS_Temperatur 254;
BA_ "GenSigSwitchedByIgnition" SG_ 1438 BMS_Temperatur 0;
BA_ "Fehlerwert" SG_ 1438 BMS_Temperatur 255;
BA_ "GenSigSendType" SG_ 1438 BMS_Temperierung_Anf 0;
BA_ "GenSigStartValue" SG_ 1438 BMS_Temperierung_Anf 3;
BA_ "GenSigSwitchedByIgnition" SG_ 1438 BMS_Temperierung_Anf 0;
BA_ "GenSigSendType" SG_ 1482 BMS_07_BZ 0;
BA_ "GenSigFuncType" SG_ 1482 BMS_07_BZ 1;
BA_ "GenSigSwitchedByIgnition" SG_ 1482 BMS_07_BZ 0;
BA_ "GenSigSendType" SG_ 1482 BMS_07_CRC 0;
BA_ "GenSigFuncType" SG_ 1482 BMS_07_CRC 2;
BA_ "GenSigSwitchedByIgnition" SG_ 1482 BMS_07_CRC 0;
BA_ "GenSigSendType" SG_ 1482 BMS_Ausgleichsladung_Anf 0;
BA_ "GenSigSwitchedByIgnition" SG_ 1482 BMS_Ausgleichsladung_Anf 0;
BA_ "GenSigSendType" SG_ 1482 BMS_Balancing_Aktiv 0;
BA_ "GenSigSwitchedByIgnition" SG_ 1482 BMS_Balancing_Aktiv 0;
BA_ "GenSigSendType" SG_ 1482 BMS_Batteriediagnose 3;
BA_ "GenSigStartValue" SG_ 1482 BMS_Batteriediagnose 1;
BA_ "GenSigSwitchedByIgnition" SG_ 1482 BMS_Batteriediagnose 0;
BA_ "Fehlerwert" SG_ 1482 BMS_Batteriediagnose 7;
BA_ "GenSigSendType" SG_ 1482 BMS_Energieinhalt 0;
BA_ "GenSigStartValue" SG_ 1482 BMS_Energieinhalt 2046;
BA_ "GenSigSwitchedByIgnition" SG_ 1482 BMS_Energieinhalt 0;
BA_ "Fehlerwert" SG_ 1482 BMS_Energieinhalt 2047;
BA_ "GenSigSendType" SG_ 1482 BMS_Fehler_KuehlkreislaufLeckage 3;
BA_ "GenSigSwitchedByIgnition" SG_ 1482 BMS_Fehler_KuehlkreislaufLeckage 0;
BA_ "GenSigSendType" SG_ 1482 BMS_Freig_max_Performanz 3;
BA_ "GenSigSwitchedByIgnition" SG_ 1482 BMS_Freig_max_Performanz 0;
BA_ "GenSigSendType" SG_ 1482 BMS_Gesamtst_Spgfreiheit 3;
BA_ "GenSigSwitchedByIgnition" SG_ 1482 BMS_Gesamtst_Spgfreiheit 0;
BA_ "GenSigSendType" SG_ 1482 BMS_KundenWarnung 3;
BA_ "GenSigSwitchedByIgnition" SG_ 1482 BMS_KundenWarnung 0;
BA_ "GenSigSendType" SG_ 1482 BMS_Ladevorgang_aktiv 0;
BA_ "GenSigSwitchedByIgnition" SG_ 1482 BMS_Ladevorgang_aktiv 0;
BA_ "GenSigSendType" SG_ 1482 BMS_MaxEnergieinhalt 0;
BA_ "GenSigStartValue" SG_ 1482 BMS_MaxEnergieinhalt 2046;
BA_ "GenSigSwitchedByIgnition" SG_ 1482 BMS_MaxEnergieinhalt 0;
BA_ "Fehlerwert" SG_ 1482 BMS_MaxEnergieinhalt 2047;
BA_ "GenSigSendType" SG_ 1482 BMS_RIso_Ext 0;
BA_ "GenSigStartValue" SG_ 1482 BMS_RIso_Ext 4094;
BA_ "GenSigSwitchedByIgnition" SG_ 1482 BMS_RIso_Ext 0;
BA_ "Fehlerwert" SG_ 1482 BMS_RIso_Ext 4095;
BA_ "GenSigSendType" SG_ 1289 BMS_Energieinhalt_HiRes 0;
BA_ "GenSigStartValue" SG_ 1289 BMS_Energieinhalt_HiRes 32766;
BA_ "GenSigSwitchedByIgnition" SG_ 1289 BMS_Energieinhalt_HiRes 0;
BA_ "Fehlerwert" SG_ 1289 BMS_Energieinhalt_HiRes 32767;
BA_ "GenSigSendType" SG_ 1289 BMS_MaxEnergieinhalt_HiRes 0;
BA_ "GenSigStartValue" SG_ 1289 BMS_MaxEnergieinhalt_HiRes 32766;
BA_ "GenSigSwitchedByIgnition" SG_ 1289 BMS_MaxEnergieinhalt_HiRes 0;
BA_ "Fehlerwert" SG_ 1289 BMS_MaxEnergieinhalt_HiRes 32767;
BA_ "GenSigSendType" SG_ 1289 BMS_NutzbarerEnergieinhalt 0;
BA_ "GenSigStartValue" SG_ 1289 BMS_NutzbarerEnergieinhalt 4094;
BA_ "GenSigSwitchedByIgnition" SG_ 1289 BMS_NutzbarerEnergieinhalt 0;
BA_ "Fehlerwert" SG_ 1289 BMS_NutzbarerEnergieinhalt 4095;
BA_ "GenSigSendType" SG_ 1289 BMS_NutzbarerSOC 0;
BA_ "GenSigStartValue" SG_ 1289 BMS_NutzbarerSOC 254;
BA_ "GenSigSwitchedByIgnition" SG_ 1289 BMS_NutzbarerSOC 0;
BA_ "Fehlerwert" SG_ 1289 BMS_NutzbarerSOC 255;
BA_ "GenSigSendType" SG_ 1289 BMS_Pred_Entladeperformance 0;
BA_ "GenSigStartValue" SG_ 1289 BMS_Pred_Entladeperformance 126;
BA_ "GenSigSwitchedByIgnition" SG_ 1289 BMS_Pred_Entladeperformance 0;
BA_ "Fehlerwert" SG_ 1289 BMS_Pred_Entladeperformance 127;
BA_ "GenSigSendType" SG_ 1289 BMS_Pred_Ladeperformance 0;
BA_ "GenSigStartValue" SG_ 1289 BMS_Pred_Ladeperformance 126;
BA_ "GenSigSwitchedByIgnition" SG_ 1289 BMS_Pred_Ladeperformance 0;
BA_ "Fehlerwert" SG_ 1289 BMS_Pred_Ladeperformance 127;
BA_ "GenSigSendType" SG_ 2463978838 BMS_NutzbarerEnergieinhalt_HiRes 0;
BA_ "GenSigStartValue" SG_ 2463978838 BMS_NutzbarerEnergieinhalt_HiRes 32766;
BA_ "GenSigSwitchedByIgnition" SG_ 2463978838 BMS_NutzbarerEnergieinhalt_HiRes 0;
BA_ "Fehlerwert" SG_ 2463978838 BMS_NutzbarerEnergieinhalt_HiRes 32767;
BA_ "GenSigSendType" SG_ 2463978838 BMS_ZellTemp_virtuell_max 0;
BA_ "GenSigStartValue" SG_ 2463978838 BMS_ZellTemp_virtuell_max 254;
BA_ "GenSigSwitchedByIgnition" SG_ 2463978838 BMS_ZellTemp_virtuell_max 0;
BA_ "Fehlerwert" SG_ 2463978838 BMS_ZellTemp_virtuell_max 255;
BA_ "GenSigSendType" SG_ 2463978838 BMS_ZellTemp_virtuell_min 0;
BA_ "GenSigStartValue" SG_ 2463978838 BMS_ZellTemp_virtuell_min 254;
BA_ "GenSigSwitchedByIgnition" SG_ 2463978838 BMS_ZellTemp_virtuell_min 0;
BA_ "Fehlerwert" SG_ 2463978838 BMS_ZellTemp_virtuell_min 255;
BA_ "GenSigSendType" SG_ 2589284070 BMS_ExtLadeleistung 0;
BA_ "GenSigStartValue" SG_ 2589284070 BMS_ExtLadeleistung 1022;
BA_ "GenSigSwitchedByIgnition" SG_ 2589284070 BMS_ExtLadeleistung 0;
BA_ "Fehlerwert" SG_ 2589284070 BMS_ExtLadeleistung 1023;
BA_ "GenSigSendType" SG_ 903 Bremse_EV_02_BZ 0;
BA_ "GenSigFuncType" SG_ 903 Bremse_EV_02_BZ 1;
BA_ "GenSigSwitchedByIgnition" SG_ 903 Bremse_EV_02_BZ 0;
BA_ "GenSigSendType" SG_ 903 Bremse_EV_02_CRC 0;
BA_ "GenSigFuncType" SG_ 903 Bremse_EV_02_CRC 2;
BA_ "GenSigSwitchedByIgnition" SG_ 903 Bremse_EV_02_CRC 0;
BA_ "GenSigSendType" SG_ 903 EBKV_BKL_Warnungen 0;
BA_ "GenSigSwitchedByIgnition" SG_ 903 EBKV_BKL_Warnungen 0;
BA_ "GenSigSendType" SG_ 903 EBKV_Charisma_FahrPr 0;
BA_ "GenSigSwitchedByIgnition" SG_ 903 EBKV_Charisma_FahrPr 0;
BA_ "GenSigSendType" SG_ 903 EBKV_Charisma_Status 0;
BA_ "GenSigSwitchedByIgnition" SG_ 903 EBKV_Charisma_Status 0;
BA_ "GenSigSendType" SG_ 903 EBKV_Hinweise 0;
BA_ "GenSigSwitchedByIgnition" SG_ 903 EBKV_Hinweise 0;
BA_ "GenSigSendType" SG_ 903 EBKV_OBD_Status 0;
BA_ "GenSigSwitchedByIgnition" SG_ 903 EBKV_OBD_Status 0;
BA_ "GenSigSendType" SG_ 903 EBKV_Warnungen 0;
BA_ "GenSigSwitchedByIgnition" SG_ 903 EBKV_Warnungen 0;
BA_ "GenSigSendType" SG_ 902 CHA_Charge_LED 3;
BA_ "GenSigSwitchedByIgnition" SG_ 902 CHA_Charge_LED 0;
BA_ "GenSigSendType" SG_ 902 CHA_Current_Mode 3;
BA_ "GenSigSwitchedByIgnition" SG_ 902 CHA_Current_Mode 0;
BA_ "GenSigSendType" SG_ 902 CHA_Drehschalter_Istmodus 3;
BA_ "GenSigSwitchedByIgnition" SG_ 902 CHA_Drehschalter_Istmodus 0;
BA_ "GenSigSendType" SG_ 902 CHA_Drive_Select1_LED 0;
BA_ "GenSigStartValue" SG_ 902 CHA_Drive_Select1_LED 3;
BA_ "GenSigSwitchedByIgnition" SG_ 902 CHA_Drive_Select1_LED 0;
BA_ "GenSigSendType" SG_ 902 CHA_Eco_Charisma_LED 3;
BA_ "GenSigSwitchedByIgnition" SG_ 902 CHA_Eco_Charisma_LED 0;
BA_ "GenSigSendType" SG_ 902 CHA_EV_LED 3;
BA_ "GenSigSwitchedByIgnition" SG_ 902 CHA_EV_LED 0;
BA_ "GenSigSendType" SG_ 902 CHA_Fahrer_Umschaltung 3;
BA_ "GenSigSwitchedByIgnition" SG_ 902 CHA_Fahrer_Umschaltung 0;
BA_ "GenSigSendType" SG_ 902 CHA_Kombi_Texte 3;
BA_ "GenSigSwitchedByIgnition" SG_ 902 CHA_Kombi_Texte 0;
BA_ "GenSigSendType" SG_ 902 CHA_Kombi_Texte_02 3;
BA_ "GenSigSwitchedByIgnition" SG_ 902 CHA_Kombi_Texte_02 0;
BA_ "GenSigSendType" SG_ 902 CHA_Offroad_LED 3;
BA_ "GenSigSwitchedByIgnition" SG_ 902 CHA_Offroad_LED 0;
BA_ "Fehlerwert" SG_ 902 CHA_Offroad_LED 3;
BA_ "GenSigSendType" SG_ 902 CHA_Ziel_FahrPr_03_01 3;
BA_ "GenSigSwitchedByIgnition" SG_ 902 CHA_Ziel_FahrPr_03_01 0;
BA_ "GenSigSendType" SG_ 902 CHA_Ziel_FahrPr_03_02 3;
BA_ "GenSigSwitchedByIgnition" SG_ 902 CHA_Ziel_FahrPr_03_02 0;
BA_ "GenSigSendType" SG_ 902 CHA_Ziel_FahrPr_AMB 3;
BA_ "GenSigSwitchedByIgnition" SG_ 902 CHA_Ziel_FahrPr_AMB 0;
BA_ "GenSigSendType" SG_ 902 CHA_Ziel_FahrPr_HSP 3;
BA_ "GenSigSwitchedByIgnition" SG_ 902 CHA_Ziel_FahrPr_HSP 0;
BA_ "GenSigSendType" SG_ 902 CHA_Ziel_FahrPr_IVB 3;
BA_ "GenSigSwitchedByIgnition" SG_ 902 CHA_Ziel_FahrPr_IVB 0;
BA_ "GenSigSendType" SG_ 902 CHA_Ziel_FahrPr_KL 3;
BA_ "GenSigSwitchedByIgnition" SG_ 902 CHA_Ziel_FahrPr_KL 0;
BA_ "GenSigSendType" SG_ 902 CHA_Ziel_FahrPr_RWB 3;
BA_ "GenSigSwitchedByIgnition" SG_ 902 CHA_Ziel_FahrPr_RWB 0;
BA_ "GenSigSendType" SG_ 1022 CHA_Current_Mode_BMA 3;
BA_ "GenSigSwitchedByIgnition" SG_ 1022 CHA_Current_Mode_BMA 0;
BA_ "GenSigSendType" SG_ 1022 CHA_Fahrer_Umschaltung 3;
BA_ "GenSigSwitchedByIgnition" SG_ 1022 CHA_Fahrer_Umschaltung 0;
BA_ "GenSigSendType" SG_ 1022 CHA_Fahrer_Umschaltung_BMA 3;
BA_ "GenSigSwitchedByIgnition" SG_ 1022 CHA_Fahrer_Umschaltung_BMA 0;
BA_ "GenSigSendType" SG_ 1022 CHA_Ziel_FahrPr_AGK 3;
BA_ "GenSigSwitchedByIgnition" SG_ 1022 CHA_Ziel_FahrPr_AGK 0;
BA_ "GenSigSendType" SG_ 1022 CHA_Ziel_FahrPr_BMS 3;
BA_ "GenSigSwitchedByIgnition" SG_ 1022 CHA_Ziel_FahrPr_BMS 0;
BA_ "GenSigSendType" SG_ 1022 CHA_Ziel_FahrPr_EDS 3;
BA_ "GenSigSwitchedByIgnition" SG_ 1022 CHA_Ziel_FahrPr_EDS 0;
BA_ "GenSigSendType" SG_ 1022 CHA_Ziel_FahrPr_HHC 3;
BA_ "GenSigSwitchedByIgnition" SG_ 1022 CHA_Ziel_FahrPr_HHC 0;
BA_ "GenSigSendType" SG_ 1022 CHA_Ziel_FahrPr_MO_Freilauf 3;
BA_ "GenSigSwitchedByIgnition" SG_ 1022 CHA_Ziel_FahrPr_MO_Freilauf 0;
BA_ "GenSigSendType" SG_ 1022 CHA_Ziel_FahrPr_PACC 3;
BA_ "GenSigSwitchedByIgnition" SG_ 1022 CHA_Ziel_FahrPr_PACC 0;
BA_ "GenSigSendType" SG_ 1022 CHA_Ziel_FahrPr_PDC 3;
BA_ "GenSigSwitchedByIgnition" SG_ 1022 CHA_Ziel_FahrPr_PDC 0;
BA_ "GenSigSendType" SG_ 1022 CHA_Ziel_FahrPr_Reku_ZwGas 3;
BA_ "GenSigSwitchedByIgnition" SG_ 1022 CHA_Ziel_FahrPr_Reku_ZwGas 0;
BA_ "GenSigSendType" SG_ 2463978630 CHA_Charisma_LED1 3;
BA_ "GenSigSwitchedByIgnition" SG_ 2463978630 CHA_Charisma_LED1 0;
BA_ "GenSigSendType" SG_ 2463978630 CHA_Charisma_LED2 3;
BA_ "GenSigSwitchedByIgnition" SG_ 2463978630 CHA_Charisma_LED2 0;
BA_ "GenSigSendType" SG_ 2463978630 CHA_Charisma_LED3 3;
BA_ "GenSigSwitchedByIgnition" SG_ 2463978630 CHA_Charisma_LED3 0;
BA_ "GenSigSendType" SG_ 2463978630 CHA_Drehschalter_VW_Blinken 3;
BA_ "GenSigSwitchedByIgnition" SG_ 2463978630 CHA_Drehschalter_VW_Blinken 0;
BA_ "Fehlerwert" SG_ 2463978630 CHA_Drehschalter_VW_Blinken 15;
BA_ "GenSigSendType" SG_ 2463978630 CHA_Drehschalter_VW_Istmodus 3;
BA_ "GenSigSwitchedByIgnition" SG_ 2463978630 CHA_Drehschalter_VW_Istmodus 0;
BA_ "GenSigSendType" SG_ 2463978630 CHA_Drehschalter_VW_Mode_LED 3;
BA_ "GenSigSwitchedByIgnition" SG_ 2463978630 CHA_Drehschalter_VW_Mode_LED 0;
BA_ "GenSigSendType" SG_ 2527679663 CHA_Ziel_FahrPr_Antrieb_LB 3;
BA_ "GenSigSwitchedByIgnition" SG_ 2527679663 CHA_Ziel_FahrPr_Antrieb_LB 0;
BA_ "GenSigSendType" SG_ 2527679663 CHA_Ziel_FahrPr_Fahrwerk_LB 3;
BA_ "GenSigSwitchedByIgnition" SG_ 2527679663 CHA_Ziel_FahrPr_Fahrwerk_LB 0;
BA_ "GenSigSendType" SG_ 2527679663 CHA_Ziel_FahrPr_Lenkung_LB 3;
BA_ "GenSigSwitchedByIgnition" SG_ 2527679663 CHA_Ziel_FahrPr_Lenkung_LB 0;
BA_ "GenSigSendType" SG_ 615 Daempfer_02_BZ 0;
BA_ "GenSigFuncType" SG_ 615 Daempfer_02_BZ 1;
BA_ "GenSigSendType" SG_ 615 Daempfer_02_CRC 0;
BA_ "GenSigFuncType" SG_ 615 Daempfer_02_CRC 2;
BA_ "GenSigSendType" SG_ 615 DR_Charisma_FahrPr 0;
BA_ "GenSigSendType" SG_ 615 DR_Charisma_Status 0;
BA_ "GenSigSendType" SG_ 615 DR_DynAGL_Anf_Entkopplung 0;
BA_ "GenSigSendType" SG_ 615 DR_DynAGL_Anf_im_Leerlauf 0;
BA_ "GenSigSendType" SG_ 615 DR_ESP_Zuschaltung 0;
BA_ "GenSigSendType" SG_ 615 DR_Systemstatus 0;
BA_ "GenSigSendType" SG_ 615 EFP_LstgBegr 0;
BA_ "GenSigStartValue" SG_ 615 EFP_LstgBegr 1022;
BA_ "GenSigSwitchedByIgnition" SG_ 615 EFP_LstgBegr 0;
BA_ "Fehlerwert" SG_ 615 EFP_LstgBegr 1023;
BA_ "GenSigSendType" SG_ 615 EFP_Niveauzustand_Lift 0;
BA_ "GenSigSwitchedByIgnition" SG_ 615 EFP_Niveauzustand_Lift 0;
BA_ "Fehlerwert" SG_ 615 EFP_Niveauzustand_Lift 5;
BA_ "GenSigSendType" SG_ 615 EFP_Verfuegbarkeit_Lift 0;
BA_ "GenSigSwitchedByIgnition" SG_ 615 EFP_Verfuegbarkeit_Lift 0;
BA_ "GenSigSendType" SG_ 615 EFP_Vorlaufzeit_Lift 0;
BA_ "GenSigSwitchedByIgnition" SG_ 615 EFP_Vorlaufzeit_Lift 0;
BA_ "Fehlerwert" SG_ 615 EFP_Vorlaufzeit_Lift 7;
BA_ "GenSigSendType" SG_ 1012 DC_HYB_Auslastungsgrad 0;
BA_ "GenSigStartValue" SG_ 1012 DC_HYB_Auslastungsgrad 254;
BA_ "Fehlerwert" SG_ 1012 DC_HYB_Auslastungsgrad 255;
BA_ "GenSigSendType" SG_ 1012 DC_HYB_iAktReserveLV 0;
BA_ "GenSigStartValue" SG_ 1012 DC_HYB_iAktReserveLV 1022;
BA_ "GenSigSwitchedByIgnition" SG_ 1012 DC_HYB_iAktReserveLV 0;
BA_ "Fehlerwert" SG_ 1012 DC_HYB_iAktReserveLV 1023;
BA_ "GenSigSendType" SG_ 1012 DC_Verbrauch 0;
BA_ "GenSigSwitchedByIgnition" SG_ 1012 DC_Verbrauch 0;
BA_ "GenSigSendType" SG_ 1012 DC_Verbrauch_Ueberlauf 0;
BA_ "GenSigSwitchedByIgnition" SG_ 1012 DC_Verbrauch_Ueberlauf 0;
BA_ "GenSigSendType" SG_ 1012 DC_Verlustleistung 0;
BA_ "GenSigStartValue" SG_ 1012 DC_Verlustleistung 62;
BA_ "GenSigSwitchedByIgnition" SG_ 1012 DC_Verlustleistung 0;
BA_ "Fehlerwert" SG_ 1012 DC_Verlustleistung 63;
BA_ "GenSigSendType" SG_ 1012 DCDC_02_BZ 0;
BA_ "GenSigFuncType" SG_ 1012 DCDC_02_BZ 1;
BA_ "GenSigSwitchedByIgnition" SG_ 1012 DCDC_02_BZ 0;
BA_ "GenSigSendType" SG_ 1012 DCDC_02_CRC 0;
BA_ "GenSigFuncType" SG_ 1012 DCDC_02_CRC 2;
BA_ "GenSigSwitchedByIgnition" SG_ 1012 DCDC_02_CRC 0;
BA_ "GenSigSwitchedByIgnition" SG_ 2617039360 DEV_HUD_Resp_00_Data 0;
BA_ "GenSigSwitchedByIgnition" SG_ 2617039615 DEV_HUD_Resp_FF_Data 0;
BA_ "GenSigSwitchedByIgnition" SG_ 2617025024 DEV_Kombi_Resp_00_Data 0;
BA_ "GenSigSwitchedByIgnition" SG_ 2617025279 DEV_Kombi_Resp_FF_Data 0;
BA_ "GenSigSwitchedByIgnition" SG_ 2617154048 DEV_Waehlhebel_Resp_00_Data 0;
BA_ "GenSigSwitchedByIgnition" SG_ 2617154303 DEV_Waehlhebel_Resp_FF_Data 0;
BA_ "GenSigSendType" SG_ 2549880747 DIA_SAAM_Req_Data 3;
BA_ "GenSigFuncType" SG_ 2549880747 DIA_SAAM_Req_Data 9;
BA_ "GenSigSwitchedByIgnition" SG_ 2549880747 DIA_SAAM_Req_Data 0;
BA_ "GenSigSendType" SG_ 2550011819 DIA_SAAM_Resp_Data 3;
BA_ "GenSigFuncType" SG_ 2550011819 DIA_SAAM_Resp_Data 9;
BA_ "GenSigSwitchedByIgnition" SG_ 2550011819 DIA_SAAM_Resp_Data 0;
BA_ "GenSigSendType" SG_ 2549880434 DIA_UHR_Req_Data 3;
BA_ "GenSigFuncType" SG_ 2549880434 DIA_UHR_Req_Data 9;
BA_ "GenSigSwitchedByIgnition" SG_ 2549880434 DIA_UHR_Req_Data 0;
BA_ "GenSigSendType" SG_ 2550011506 DIA_UHR_Resp_Data 3;
BA_ "GenSigFuncType" SG_ 2550011506 DIA_UHR_Resp_Data 9;
BA_ "GenSigSwitchedByIgnition" SG_ 2550011506 DIA_UHR_Resp_Data 0;
BA_ "GenSigSendType" SG_ 1714 DGN_Verlernzaehler 0;
BA_ "GenSigSwitchedByIgnition" SG_ 1714 DGN_Verlernzaehler 0;
BA_ "GenSigSendType" SG_ 1714 KBI_Kilometerstand 0;
BA_ "GenSigStartValue" SG_ 1714 KBI_Kilometerstand 1048574;
BA_ "GenSigSwitchedByIgnition" SG_ 1714 KBI_Kilometerstand 0;
BA_ "Fehlerwert" SG_ 1714 KBI_Kilometerstand 1048575;
BA_ "GenSigSendType" SG_ 1714 Kombi_02_alt 0;
BA_ "GenSigStartValue" SG_ 1714 Kombi_02_alt 1;
BA_ "GenSigFuncType" SG_ 1714 Kombi_02_alt 5;
BA_ "GenSigSwitchedByIgnition" SG_ 1714 Kombi_02_alt 0;
BA_ "GenSigSendType" SG_ 1714 UH_Jahr 0;
BA_ "GenSigSwitchedByIgnition" SG_ 1714 UH_Jahr 0;
BA_ "GenSigSendType" SG_ 1714 UH_Minute 0;
BA_ "GenSigSwitchedByIgnition" SG_ 1714 UH_Minute 0;
BA_ "GenSigSendType" SG_ 1714 UH_Monat 0;
BA_ "GenSigSwitchedByIgnition" SG_ 1714 UH_Monat 0;
BA_ "Fehlerwert" SG_ 1714 UH_Monat 15;
BA_ "GenSigSendType" SG_ 1714 UH_Sekunde 0;
BA_ "GenSigSwitchedByIgnition" SG_ 1714 UH_Sekunde 0;
BA_ "GenSigSendType" SG_ 1714 UH_Stunde 0;
BA_ "GenSigSwitchedByIgnition" SG_ 1714 UH_Stunde 0;
BA_ "GenSigSendType" SG_ 1714 UH_Tag 0;
BA_ "GenSigSwitchedByIgnition" SG_ 1714 UH_Tag 0;
BA_ "GenSigSendType" SG_ 1714 Uhrzeit_01_alt 0;
BA_ "GenSigStartValue" SG_ 1714 Uhrzeit_01_alt 1;
BA_ "GenSigFuncType" SG_ 1714 Uhrzeit_01_alt 5;
BA_ "GenSigSwitchedByIgnition" SG_ 1714 Uhrzeit_01_alt 0;
BA_REL_ "GenSigTimeoutTime" BU_SG_REL_ CGS SG_ 1714 DGN_Verlernzaehler 5000;
BA_REL_ "GenSigTimeoutTime" BU_SG_REL_ CGS SG_ 1714 KBI_Kilometerstand 5000;
BA_REL_ "GenSigTimeoutTime" BU_SG_REL_ CGS SG_ 1714 UH_Jahr 5000;
BA_REL_ "GenSigTimeoutTime" BU_SG_REL_ CGS SG_ 1714 UH_Monat 5000;
BA_REL_ "GenSigTimeoutTime" BU_SG_REL_ CGS SG_ 1714 UH_Tag 5000;
BA_REL_ "GenSigTimeoutTime" BU_SG_REL_ CGS SG_ 1714 UH_Stunde 5000;
BA_REL_ "GenSigTimeoutTime" BU_SG_REL_ CGS SG_ 1714 UH_Minute 5000;
BA_REL_ "GenSigTimeoutTime" BU_SG_REL_ CGS SG_ 1714 UH_Sekunde 5000;
BA_REL_ "GenSigTimeoutTime" BU_SG_REL_ Gateway SG_ 2463978631 CHA_Drehschalter_VW_Modus 5000;
BA_REL_ "GenSigTimeoutTime" BU_SG_REL_ Gateway SG_ 2463978631 CHA_Drehschalter_VW_Mode_Taster 5000;
BA_REL_ "GenSigTimeoutTime" BU_SG_REL_ Gateway SG_ 2463978631 BuA_Charisma_Taste1 5000;
BA_REL_ "GenSigTimeoutTime" BU_SG_REL_ Gateway SG_ 2463978631 BuA_Charisma_Taste2 5000;
BA_REL_ "GenSigTimeoutTime" BU_SG_REL_ Gateway SG_ 2463978631 BuA_Charisma_Taste3 5000;
BA_REL_ "GenSigTimeoutTime" BU_SG_REL_ Gateway SG_ 2463978631 CHA_Drehschalter_VW_defekt 5000;
BA_REL_ "GenSigTimeoutTime" BU_SG_REL_ Gateway_PAG SG_ 2463978631 CHA_Drehschalter_VW_Modus 5000;
BA_REL_ "GenSigTimeoutTime" BU_SG_REL_ Gateway_PAG SG_ 2463978631 CHA_Drehschalter_VW_Mode_Taster 5000;
BA_REL_ "GenSigTimeoutTime" BU_SG_REL_ Gateway_PAG SG_ 2463978631 BuA_Charisma_Taste1 5000;
BA_REL_ "GenSigTimeoutTime" BU_SG_REL_ Gateway_PAG SG_ 2463978631 BuA_Charisma_Taste2 5000;
BA_REL_ "GenSigTimeoutTime" BU_SG_REL_ Gateway_PAG SG_ 2463978631 BuA_Charisma_Taste3 5000;
BA_REL_ "GenSigTimeoutTime" BU_SG_REL_ Gateway_PAG SG_ 2463978631 CHA_Drehschalter_VW_defekt 5000;
BA_REL_ "GenSigTimeoutTime" BU_SG_REL_ HUD SG_ 1615 BCM1_HUD_Eyeboxposition 5000;
BA_REL_ "GenSigTimeoutTime" BU_SG_REL_ HUD SG_ 1615 BCM1_HUD_Eyeboxposition_Status 5000;
BA_REL_ "GenSigTimeoutTime" BU_SG_REL_ HUD SG_ 1615 BCM1_HUD_Taster 5000;
BA_REL_ "GenSigTimeoutTime" BU_SG_REL_ HUD SG_ 1615 BCM1_Stellgroesse_Kl_58s 5000;
BA_REL_ "GenSigTimeoutTime" BU_SG_REL_ HUD SG_ 902 CHA_Current_Mode 5000;
BA_REL_ "GenSigTimeoutTime" BU_SG_REL_ HUD SG_ 1714 DGN_Verlernzaehler 5000;
BA_REL_ "GenSigTimeoutTime" BU_SG_REL_ HUD SG_ 1714 KBI_Kilometerstand 5000;
BA_REL_ "GenSigTimeoutTime" BU_SG_REL_ HUD SG_ 1714 UH_Jahr 5000;
BA_REL_ "GenSigTimeoutTime" BU_SG_REL_ HUD SG_ 1714 UH_Monat 5000;
BA_REL_ "GenSigTimeoutTime" BU_SG_REL_ HUD SG_ 1714 UH_Tag 5000;
BA_REL_ "GenSigTimeoutTime" BU_SG_REL_ HUD SG_ 1714 UH_Stunde 5000;
BA_REL_ "GenSigTimeoutTime" BU_SG_REL_ HUD SG_ 1714 UH_Minute 5000;
BA_REL_ "GenSigTimeoutTime" BU_SG_REL_ HUD SG_ 1714 UH_Sekunde 5000;
BA_REL_ "GenSigTimeoutTime" BU_SG_REL_ Kombi SG_ 1615 LV_Laserlicht_Texte 5000;
BA_REL_ "GenSigTimeoutTime" BU_SG_REL_ Kombi SG_ 1626 BCM_Bremsbelag_Sensor 5000;
BA_REL_ "GenSigTimeoutTime" BU_SG_REL_ Kombi SG_ 1626 BCM_Bremsfluessigkeit_Sensor 5000;
BA_REL_ "GenSigTimeoutTime" BU_SG_REL_ Kombi SG_ 1626 BCM_Waschwasser_Sensor 5000;
BA_REL_ "GenSigTimeoutTime" BU_SG_REL_ Kombi SG_ 1626 BCM_Kuehlmittel_Sensor 5000;
BA_REL_ "GenSigTimeoutTime" BU_SG_REL_ Kombi SG_ 1626 BCM_Kuehlmittel_Sensor_02 5000;
BA_REL_ "GenSigTimeoutTime" BU_SG_REL_ Kombi SG_ 1626 BCM1_Hinweis_Lichtnachlauf 5000;
BA_REL_ "GenSigTimeoutTime" BU_SG_REL_ Kombi SG_ 1626 BCM1_MH_Schalter 5000;
BA_REL_ "GenSigTimeoutTime" BU_SG_REL_ Kombi SG_ 1626 BCM1_NV_Taster 5000;
BA_REL_ "GenSigTimeoutTime" BU_SG_REL_ Kombi SG_ 1626 BCM1_AFS_Lampe 5000;
BA_REL_ "GenSigTimeoutTime" BU_SG_REL_ Kombi SG_ 1626 BCM1_Reisemodus_Texte 5000;
BA_REL_ "GenSigTimeoutTime" BU_SG_REL_ Kombi SG_ 1626 BCM1_Lichtwarn_Texte 5000;
BA_REL_ "GenSigTimeoutTime" BU_SG_REL_ Kombi SG_ 1626 BCM1_Fahrlicht_Hinweis 5000;
BA_REL_ "GenSigTimeoutTime" BU_SG_REL_ Kombi SG_ 672 BCM_Waehlhebel_P_Hinweis 2000;
BA_REL_ "GenSigTimeoutTime" BU_SG_REL_ Kombi SG_ 672 BCM_ValetTaster_Fkts_LED 2000;
BA_REL_ "GenSigTimeoutTime" BU_SG_REL_ Kombi SG_ 672 BCM2_TrunkEntrapment_Warn 2000;
BA_REL_ "GenSigTimeoutTime" BU_SG_REL_ Kombi SG_ 672 BCM_Handbremse_Hinweis 2000;
BA_REL_ "GenSigTimeoutTime" BU_SG_REL_ Kombi SG_ 2527679637 CPD_Warnung 5000;
BA_REL_ "GenSigTimeoutTime" BU_SG_REL_ Kombi SG_ 2527679637 BCM_LTM_Nebelschluss_Status 5000;
BA_REL_ "GenSigTimeoutTime" BU_SG_REL_ Kombi SG_ 2527679637 BCM_LTM_Allwetterl_Status 5000;
BA_REL_ "GenSigTimeoutTime" BU_SG_REL_ Kombi SG_ 2527679637 BCM_LTM_PopUp_Status 5000;
BA_REL_ "GenSigTimeoutTime" BU_SG_REL_ Kombi SG_ 2527679637 BCM_LTM_Nebell_Status 5000;
BA_REL_ "GenSigTimeoutTime" BU_SG_REL_ Kombi SG_ 2527679637 BCM_LTM_PopUp_Anf 5000;
BA_REL_ "GenSigTimeoutTime" BU_SG_REL_ Kombi SG_ 2527679637 BCM_LTM_PopUp_Inhalt 5000;
BA_REL_ "GenSigTimeoutTime" BU_SG_REL_ Kombi SG_ 2463978607 BCM_RGB_Rot 2000;
BA_REL_ "GenSigTimeoutTime" BU_SG_REL_ Kombi SG_ 2463978607 BCM_RGB_Gruen 2000;
BA_REL_ "GenSigTimeoutTime" BU_SG_REL_ Kombi SG_ 2463978607 BCM_RGB_Blau 2000;
BA_REL_ "GenSigTimeoutTime" BU_SG_REL_ Kombi SG_ 870 BM_Warnblinken 5000;
BA_REL_ "GenSigTimeoutTime" BU_SG_REL_ Kombi SG_ 870 Blinken_li_Kombi_Takt 5000;
BA_REL_ "GenSigTimeoutTime" BU_SG_REL_ Kombi SG_ 870 Blinken_re_Kombi_Takt 5000;
BA_REL_ "GenSigTimeoutTime" BU_SG_REL_ Kombi SG_ 868 NBlinken_li_Kombi_Takt 500;
BA_REL_ "GenSigTimeoutTime" BU_SG_REL_ Kombi SG_ 868 NBlinken_re_Kombi_Takt 500;
BA_REL_ "GenSigTimeoutTime" BU_SG_REL_ Kombi SG_ 687 BMS_As_Entladezaehler 500;
BA_REL_ "GenSigTimeoutTime" BU_SG_REL_ Kombi SG_ 687 BMS_As_Entladezaehler_Ueberlauf 500;
BA_REL_ "GenSigTimeoutTime" BU_SG_REL_ Kombi SG_ 687 BMS_Rekuperation 500;
BA_REL_ "GenSigTimeoutTime" BU_SG_REL_ Kombi SG_ 687 BMS_Rekuperation_Ueberlauf 500;
BA_REL_ "GenSigTimeoutTime" BU_SG_REL_ Kombi SG_ 687 BMS_Verbrauch 500;
BA_REL_ "GenSigTimeoutTime" BU_SG_REL_ Kombi SG_ 687 BMS_Verbrauch_Ueberlauf 500;
BA_REL_ "GenSigTimeoutTime" BU_SG_REL_ Kombi SG_ 1438 BMS_Temperatur 5000;
BA_REL_ "GenSigTimeoutTime" BU_SG_REL_ Kombi SG_ 1482 BMS_Energieinhalt 5000;
BA_REL_ "GenSigTimeoutTime" BU_SG_REL_ Kombi SG_ 1482 BMS_Ladevorgang_aktiv 5000;
BA_REL_ "GenSigTimeoutTime" BU_SG_REL_ Kombi SG_ 1482 BMS_Batteriediagnose 5000;
BA_REL_ "GenSigTimeoutTime" BU_SG_REL_ Kombi SG_ 1482 BMS_MaxEnergieinhalt 5000;
BA_REL_ "GenSigTimeoutTime" BU_SG_REL_ Kombi SG_ 1482 BMS_KundenWarnung 5000;
BA_REL_ "GenSigTimeoutTime" BU_SG_REL_ Kombi SG_ 1289 BMS_NutzbarerSOC 1000;
BA_REL_ "GenSigTimeoutTime" BU_SG_REL_ Kombi SG_ 1289 BMS_NutzbarerEnergieinhalt 1000;
BA_REL_ "GenSigTimeoutTime" BU_SG_REL_ Kombi SG_ 2463978838 BMS_NutzbarerEnergieinhalt_HiRes 1000;
BA_REL_ "GenSigTimeoutTime" BU_SG_REL_ Kombi SG_ 2589284070 BMS_ExtLadeleistung 5000;
BA_REL_ "GenSigTimeoutTime" BU_SG_REL_ Kombi SG_ 903 Bremse_EV_02_CRC 800;
BA_REL_ "GenSigTimeoutTime" BU_SG_REL_ Kombi SG_ 903 Bremse_EV_02_BZ 800;
BA_REL_ "GenSigTimeoutTime" BU_SG_REL_ Kombi SG_ 903 EBKV_Hinweise 800;
BA_REL_ "GenSigTimeoutTime" BU_SG_REL_ Kombi SG_ 903 EBKV_Warnungen 800;
BA_REL_ "GenSigTimeoutTime" BU_SG_REL_ Kombi SG_ 903 EBKV_BKL_Warnungen 800;
BA_REL_ "GenSigTimeoutTime" BU_SG_REL_ Kombi SG_ 902 CHA_Kombi_Texte 5000;
BA_REL_ "GenSigTimeoutTime" BU_SG_REL_ Kombi SG_ 902 CHA_Ziel_FahrPr_RWB 5000;
BA_REL_ "GenSigTimeoutTime" BU_SG_REL_ Kombi SG_ 902 CHA_Current_Mode 5000;
BA_REL_ "GenSigTimeoutTime" BU_SG_REL_ Kombi SG_ 902 CHA_Offroad_LED 5000;
BA_REL_ "GenSigTimeoutTime" BU_SG_REL_ Kombi SG_ 902 CHA_Kombi_Texte_02 5000;
BA_REL_ "GenSigTimeoutTime" BU_SG_REL_ Kombi SG_ 1022 CHA_Current_Mode_BMA 5000;
BA_REL_ "GenSigTimeoutTime" BU_SG_REL_ Kombi SG_ 2527679663 CHA_Ziel_FahrPr_Antrieb_LB 5000;
BA_REL_ "GenSigTimeoutTime" BU_SG_REL_ Kombi SG_ 2527679663 CHA_Ziel_FahrPr_Fahrwerk_LB 5000;
BA_REL_ "GenSigTimeoutTime" BU_SG_REL_ Kombi SG_ 2527679663 CHA_Ziel_FahrPr_Lenkung_LB 5000;
BA_REL_ "GenSigTimeoutTime" BU_SG_REL_ Kombi SG_ 1012 DC_Verbrauch_Ueberlauf 1000;
BA_REL_ "GenSigTimeoutTime" BU_SG_REL_ Kombi SG_ 1012 DC_Verbrauch 1000;
BA_REL_ "GenSigTimeoutTime" BU_SG_REL_ Kombi SG_ 1714 DGN_Verlernzaehler 5000;
BA_REL_ "GenSigTimeoutTime" BU_SG_REL_ Kombi SG_ 1714 KBI_Kilometerstand 5000;
BA_REL_ "GenSigTimeoutTime" BU_SG_REL_ Kombi SG_ 1714 UH_Jahr 5000;
BA_REL_ "GenSigTimeoutTime" BU_SG_REL_ Kombi SG_ 1714 UH_Monat 5000;
BA_REL_ "GenSigTimeoutTime" BU_SG_REL_ Kombi SG_ 1714 UH_Tag 5000;
BA_REL_ "GenSigTimeoutTime" BU_SG_REL_ Kombi SG_ 1714 UH_Stunde 5000;
BA_REL_ "GenSigTimeoutTime" BU_SG_REL_ Kombi SG_ 1714 UH_Minute 5000;
BA_REL_ "GenSigTimeoutTime" BU_SG_REL_ Kombi SG_ 1714 UH_Sekunde 5000;
BA_REL_ "GenSigTimeoutTime" BU_SG_REL_ Kombi_LB SG_ 1615 LV_Laserlicht_Texte 5000;
BA_REL_ "GenSigTimeoutTime" BU_SG_REL_ Kombi_LB SG_ 1626 BCM_Bremsbelag_Sensor 5000;
BA_REL_ "GenSigTimeoutTime" BU_SG_REL_ Kombi_LB SG_ 1626 BCM_Bremsfluessigkeit_Sensor 5000;
BA_REL_ "GenSigTimeoutTime" BU_SG_REL_ Kombi_LB SG_ 1626 BCM_Waschwasser_Sensor 5000;
BA_REL_ "GenSigTimeoutTime" BU_SG_REL_ Kombi_LB SG_ 1626 BCM_Kuehlmittel_Sensor 5000;
BA_REL_ "GenSigTimeoutTime" BU_SG_REL_ Kombi_LB SG_ 1626 BCM_Kuehlmittel_Sensor_02 5000;
BA_REL_ "GenSigTimeoutTime" BU_SG_REL_ Kombi_LB SG_ 1626 BCM1_Hinweis_Lichtnachlauf 5000;
BA_REL_ "GenSigTimeoutTime" BU_SG_REL_ Kombi_LB SG_ 1626 BCM1_MH_Schalter 5000;
BA_REL_ "GenSigTimeoutTime" BU_SG_REL_ Kombi_LB SG_ 1626 BCM1_NV_Taster 5000;
BA_REL_ "GenSigTimeoutTime" BU_SG_REL_ Kombi_LB SG_ 1626 BCM1_AFS_Lampe 5000;
BA_REL_ "GenSigTimeoutTime" BU_SG_REL_ Kombi_LB SG_ 1626 BCM1_Reisemodus_Texte 5000;
BA_REL_ "GenSigTimeoutTime" BU_SG_REL_ Kombi_LB SG_ 1626 BCM1_Lichtwarn_Texte 5000;
BA_REL_ "GenSigTimeoutTime" BU_SG_REL_ Kombi_LB SG_ 1626 BCM1_Fahrlicht_Hinweis 5000;
BA_REL_ "GenSigTimeoutTime" BU_SG_REL_ Kombi_LB SG_ 672 BCM_Waehlhebel_P_Hinweis 2000;
BA_REL_ "GenSigTimeoutTime" BU_SG_REL_ Kombi_LB SG_ 672 BCM_ValetTaster_Fkts_LED 2000;
BA_REL_ "GenSigTimeoutTime" BU_SG_REL_ Kombi_LB SG_ 672 BCM2_TrunkEntrapment_Warn 2000;
BA_REL_ "GenSigTimeoutTime" BU_SG_REL_ Kombi_LB SG_ 672 BCM_Handbremse_Hinweis 2000;
BA_REL_ "GenSigTimeoutTime" BU_SG_REL_ Kombi_LB SG_ 2527679637 CPD_Warnung 5000;
BA_REL_ "GenSigTimeoutTime" BU_SG_REL_ Kombi_LB SG_ 2527679637 BCM_LTM_Nebelschluss_Status 5000;
BA_REL_ "GenSigTimeoutTime" BU_SG_REL_ Kombi_LB SG_ 2527679637 BCM_LTM_Allwetterl_Status 5000;
BA_REL_ "GenSigTimeoutTime" BU_SG_REL_ Kombi_LB SG_ 2527679637 BCM_LTM_PopUp_Status 5000;
BA_REL_ "GenSigTimeoutTime" BU_SG_REL_ Kombi_LB SG_ 2527679637 BCM_LTM_Nebell_Status 5000;
BA_REL_ "GenSigTimeoutTime" BU_SG_REL_ Kombi_LB SG_ 2527679637 BCM_LTM_PopUp_Anf 5000;
BA_REL_ "GenSigTimeoutTime" BU_SG_REL_ Kombi_LB SG_ 2527679637 BCM_LTM_PopUp_Inhalt 5000;
BA_REL_ "GenSigTimeoutTime" BU_SG_REL_ Kombi_LB SG_ 2463978607 BCM_RGB_Gruen 2000;
BA_REL_ "GenSigTimeoutTime" BU_SG_REL_ Kombi_LB SG_ 2463978607 BCM_RGB_Blau 2000;
BA_REL_ "GenSigTimeoutTime" BU_SG_REL_ Kombi_LB SG_ 870 BM_Warnblinken 5000;
BA_REL_ "GenSigTimeoutTime" BU_SG_REL_ Kombi_LB SG_ 870 Blinken_li_Kombi_Takt 5000;
BA_REL_ "GenSigTimeoutTime" BU_SG_REL_ Kombi_LB SG_ 870 Blinken_re_Kombi_Takt 5000;
BA_REL_ "GenSigTimeoutTime" BU_SG_REL_ Kombi_LB SG_ 868 NBlinken_li_Kombi_Takt 500;
BA_REL_ "GenSigTimeoutTime" BU_SG_REL_ Kombi_LB SG_ 868 NBlinken_re_Kombi_Takt 500;
BA_REL_ "GenSigTimeoutTime" BU_SG_REL_ Kombi_LB SG_ 687 BMS_As_Entladezaehler 500;
BA_REL_ "GenSigTimeoutTime" BU_SG_REL_ Kombi_LB SG_ 687 BMS_As_Entladezaehler_Ueberlauf 500;
BA_REL_ "GenSigTimeoutTime" BU_SG_REL_ Kombi_LB SG_ 687 BMS_Rekuperation 500;
BA_REL_ "GenSigTimeoutTime" BU_SG_REL_ Kombi_LB SG_ 687 BMS_Rekuperation_Ueberlauf 500;
BA_REL_ "GenSigTimeoutTime" BU_SG_REL_ Kombi_LB SG_ 687 BMS_Verbrauch 500;
BA_REL_ "GenSigTimeoutTime" BU_SG_REL_ Kombi_LB SG_ 687 BMS_Verbrauch_Ueberlauf 500;
BA_REL_ "GenSigTimeoutTime" BU_SG_REL_ Kombi_LB SG_ 1438 BMS_Temperatur 5000;
BA_REL_ "GenSigTimeoutTime" BU_SG_REL_ Kombi_LB SG_ 1482 BMS_Energieinhalt 5000;
BA_REL_ "GenSigTimeoutTime" BU_SG_REL_ Kombi_LB SG_ 1482 BMS_Ladevorgang_aktiv 5000;
BA_REL_ "GenSigTimeoutTime" BU_SG_REL_ Kombi_LB SG_ 1482 BMS_Batteriediagnose 5000;
BA_REL_ "GenSigTimeoutTime" BU_SG_REL_ Kombi_LB SG_ 1482 BMS_MaxEnergieinhalt 5000;
BA_REL_ "GenSigTimeoutTime" BU_SG_REL_ Kombi_LB SG_ 1482 BMS_KundenWarnung 5000;
BA_REL_ "GenSigTimeoutTime" BU_SG_REL_ Kombi_LB SG_ 1289 BMS_NutzbarerSOC 1000;
BA_REL_ "GenSigTimeoutTime" BU_SG_REL_ Kombi_LB SG_ 1289 BMS_NutzbarerEnergieinhalt 1000;
BA_REL_ "GenSigTimeoutTime" BU_SG_REL_ Kombi_LB SG_ 2463978838 BMS_NutzbarerEnergieinhalt_HiRes 1000;
BA_REL_ "GenSigTimeoutTime" BU_SG_REL_ Kombi_LB SG_ 903 Bremse_EV_02_CRC 800;
BA_REL_ "GenSigTimeoutTime" BU_SG_REL_ Kombi_LB SG_ 903 Bremse_EV_02_BZ 800;
BA_REL_ "GenSigTimeoutTime" BU_SG_REL_ Kombi_LB SG_ 903 EBKV_Hinweise 800;
BA_REL_ "GenSigTimeoutTime" BU_SG_REL_ Kombi_LB SG_ 903 EBKV_Warnungen 800;
BA_REL_ "GenSigTimeoutTime" BU_SG_REL_ Kombi_LB SG_ 903 EBKV_BKL_Warnungen 800;
BA_REL_ "GenSigTimeoutTime" BU_SG_REL_ Kombi_LB SG_ 902 CHA_Kombi_Texte 5000;
BA_REL_ "GenSigTimeoutTime" BU_SG_REL_ Kombi_LB SG_ 902 CHA_Ziel_FahrPr_RWB 5000;
BA_REL_ "GenSigTimeoutTime" BU_SG_REL_ Kombi_LB SG_ 902 CHA_Current_Mode 5000;
BA_REL_ "GenSigTimeoutTime" BU_SG_REL_ Kombi_LB SG_ 902 CHA_Offroad_LED 5000;
BA_REL_ "GenSigTimeoutTime" BU_SG_REL_ Kombi_LB SG_ 902 CHA_Kombi_Texte_02 5000;
BA_REL_ "GenSigTimeoutTime" BU_SG_REL_ Kombi_LB SG_ 1022 CHA_Current_Mode_BMA 5000;
BA_REL_ "GenSigTimeoutTime" BU_SG_REL_ Kombi_LB SG_ 2527679663 CHA_Ziel_FahrPr_Antrieb_LB 5000;
BA_REL_ "GenSigTimeoutTime" BU_SG_REL_ Kombi_LB SG_ 2527679663 CHA_Ziel_FahrPr_Fahrwerk_LB 5000;
BA_REL_ "GenSigTimeoutTime" BU_SG_REL_ Kombi_LB SG_ 2527679663 CHA_Ziel_FahrPr_Lenkung_LB 5000;
BA_REL_ "GenSigTimeoutTime" BU_SG_REL_ Kombi_LB SG_ 615 DR_Systemstatus 800;
BA_REL_ "GenSigTimeoutTime" BU_SG_REL_ Kombi_LB SG_ 1012 DC_Verbrauch_Ueberlauf 1000;
BA_REL_ "GenSigTimeoutTime" BU_SG_REL_ Kombi_LB SG_ 1012 DC_Verbrauch 1000;
BA_REL_ "GenSigTimeoutTime" BU_SG_REL_ Kombi_LB SG_ 1714 DGN_Verlernzaehler 5000;
BA_REL_ "GenSigTimeoutTime" BU_SG_REL_ Kombi_LB SG_ 1714 KBI_Kilometerstand 5000;
BA_REL_ "GenSigTimeoutTime" BU_SG_REL_ Kombi_LB SG_ 1714 UH_Jahr 5000;
BA_REL_ "GenSigTimeoutTime" BU_SG_REL_ Kombi_LB SG_ 1714 UH_Monat 5000;
BA_REL_ "GenSigTimeoutTime" BU_SG_REL_ Kombi_LB SG_ 1714 UH_Tag 5000;
BA_REL_ "GenSigTimeoutTime" BU_SG_REL_ Kombi_LB SG_ 1714 UH_Stunde 5000;
BA_REL_ "GenSigTimeoutTime" BU_SG_REL_ Kombi_LB SG_ 1714 UH_Minute 5000;
BA_REL_ "GenSigTimeoutTime" BU_SG_REL_ Kombi_LB SG_ 1714 UH_Sekunde 5000;
BA_REL_ "GenSigTimeoutTime" BU_SG_REL_ Kombi_PAG SG_ 1626 BCM_Bremsbelag_Sensor 5000;
BA_REL_ "GenSigTimeoutTime" BU_SG_REL_ Kombi_PAG SG_ 1626 BCM_Bremsfluessigkeit_Sensor 5000;
BA_REL_ "GenSigTimeoutTime" BU_SG_REL_ Kombi_PAG SG_ 1626 BCM_Waschwasser_Sensor 5000;
BA_REL_ "GenSigTimeoutTime" BU_SG_REL_ Kombi_PAG SG_ 1626 BCM_Kuehlmittel_Sensor 5000;
BA_REL_ "GenSigTimeoutTime" BU_SG_REL_ Kombi_PAG SG_ 1626 BCM_Kuehlmittel_Sensor_02 5000;
BA_REL_ "GenSigTimeoutTime" BU_SG_REL_ Kombi_PAG SG_ 1626 BCM1_Hinweis_Lichtnachlauf 5000;
BA_REL_ "GenSigTimeoutTime" BU_SG_REL_ Kombi_PAG SG_ 1626 BCM1_MH_Schalter 5000;
BA_REL_ "GenSigTimeoutTime" BU_SG_REL_ Kombi_PAG SG_ 1626 BCM1_NV_Taster 5000;
BA_REL_ "GenSigTimeoutTime" BU_SG_REL_ Kombi_PAG SG_ 1626 BCM1_AFS_Lampe 5000;
BA_REL_ "GenSigTimeoutTime" BU_SG_REL_ Kombi_PAG SG_ 1626 BCM1_Reisemodus_Texte 5000;
BA_REL_ "GenSigTimeoutTime" BU_SG_REL_ Kombi_PAG SG_ 1626 BCM1_Lichtwarn_Texte 5000;
BA_REL_ "GenSigTimeoutTime" BU_SG_REL_ Kombi_PAG SG_ 1626 BCM1_Fahrlicht_Hinweis 5000;
BA_REL_ "GenSigTimeoutTime" BU_SG_REL_ Kombi_PAG SG_ 672 BCM_02_CRC 2000;
BA_REL_ "GenSigTimeoutTime" BU_SG_REL_ Kombi_PAG SG_ 672 BCM_02_BZ 2000;
BA_REL_ "GenSigTimeoutTime" BU_SG_REL_ Kombi_PAG SG_ 672 BCM_Waehlhebel_P_Hinweis 2000;
BA_REL_ "GenSigTimeoutTime" BU_SG_REL_ Kombi_PAG SG_ 672 FSH_LED 2000;
BA_REL_ "GenSigTimeoutTime" BU_SG_REL_ Kombi_PAG SG_ 672 BCM2_TrunkEntrapment_Warn 2000;
BA_REL_ "GenSigTimeoutTime" BU_SG_REL_ Kombi_PAG SG_ 672 BCM_Handbremse_Hinweis 2000;
BA_REL_ "GenSigTimeoutTime" BU_SG_REL_ Kombi_PAG SG_ 2527679637 CPD_Warnung 5000;
BA_REL_ "GenSigTimeoutTime" BU_SG_REL_ Kombi_PAG SG_ 2527679637 BCM_LTM_Nebelschluss_Status 5000;
BA_REL_ "GenSigTimeoutTime" BU_SG_REL_ Kombi_PAG SG_ 2527679637 BCM_LTM_PopUp_Texte 5000;
BA_REL_ "GenSigTimeoutTime" BU_SG_REL_ Kombi_PAG SG_ 2527679637 BCM_LTM_Allwetterl_Status 5000;
BA_REL_ "GenSigTimeoutTime" BU_SG_REL_ Kombi_PAG SG_ 2527679637 BCM_LTM_PopUp_Status 5000;
BA_REL_ "GenSigTimeoutTime" BU_SG_REL_ Kombi_PAG SG_ 2527679637 BCM_LTM_Nebell_Status 5000;
BA_REL_ "GenSigTimeoutTime" BU_SG_REL_ Kombi_PAG SG_ 2527679637 BCM_LTM_PopUp_Anf 5000;
BA_REL_ "GenSigTimeoutTime" BU_SG_REL_ Kombi_PAG SG_ 2527679637 BCM_LTM_PopUp_Inhalt 5000;
BA_REL_ "GenSigTimeoutTime" BU_SG_REL_ Kombi_PAG SG_ 870 Blinken_li_Kombi_Takt 5000;
BA_REL_ "GenSigTimeoutTime" BU_SG_REL_ Kombi_PAG SG_ 870 Blinken_re_Kombi_Takt 5000;
BA_REL_ "GenSigTimeoutTime" BU_SG_REL_ Kombi_PAG SG_ 868 NBlinken_li_Kombi_Takt 500;
BA_REL_ "GenSigTimeoutTime" BU_SG_REL_ Kombi_PAG SG_ 868 NBlinken_re_Kombi_Takt 500;
BA_REL_ "GenSigTimeoutTime" BU_SG_REL_ Kombi_PAG SG_ 687 BMS_As_Entladezaehler 500;
BA_REL_ "GenSigTimeoutTime" BU_SG_REL_ Kombi_PAG SG_ 687 BMS_As_Entladezaehler_Ueberlauf 500;
BA_REL_ "GenSigTimeoutTime" BU_SG_REL_ Kombi_PAG SG_ 687 BMS_Rekuperation 500;
BA_REL_ "GenSigTimeoutTime" BU_SG_REL_ Kombi_PAG SG_ 687 BMS_Rekuperation_Ueberlauf 500;
BA_REL_ "GenSigTimeoutTime" BU_SG_REL_ Kombi_PAG SG_ 687 BMS_Verbrauch 500;
BA_REL_ "GenSigTimeoutTime" BU_SG_REL_ Kombi_PAG SG_ 687 BMS_Verbrauch_Ueberlauf 500;
BA_REL_ "GenSigTimeoutTime" BU_SG_REL_ Kombi_PAG SG_ 1438 BMS_Temperatur 5000;
BA_REL_ "GenSigTimeoutTime" BU_SG_REL_ Kombi_PAG SG_ 1482 BMS_Energieinhalt 5000;
BA_REL_ "GenSigTimeoutTime" BU_SG_REL_ Kombi_PAG SG_ 1482 BMS_Ladevorgang_aktiv 5000;
BA_REL_ "GenSigTimeoutTime" BU_SG_REL_ Kombi_PAG SG_ 1482 BMS_Batteriediagnose 5000;
BA_REL_ "GenSigTimeoutTime" BU_SG_REL_ Kombi_PAG SG_ 1482 BMS_MaxEnergieinhalt 5000;
BA_REL_ "GenSigTimeoutTime" BU_SG_REL_ Kombi_PAG SG_ 1482 BMS_KundenWarnung 5000;
BA_REL_ "GenSigTimeoutTime" BU_SG_REL_ Kombi_PAG SG_ 1289 BMS_NutzbarerSOC 1000;
BA_REL_ "GenSigTimeoutTime" BU_SG_REL_ Kombi_PAG SG_ 1289 BMS_NutzbarerEnergieinhalt 1000;
BA_REL_ "GenSigTimeoutTime" BU_SG_REL_ Kombi_PAG SG_ 2589284070 BMS_ExtLadeleistung 5000;
BA_REL_ "GenSigTimeoutTime" BU_SG_REL_ Kombi_PAG SG_ 903 Bremse_EV_02_CRC 800;
BA_REL_ "GenSigTimeoutTime" BU_SG_REL_ Kombi_PAG SG_ 903 Bremse_EV_02_BZ 800;
BA_REL_ "GenSigTimeoutTime" BU_SG_REL_ Kombi_PAG SG_ 903 EBKV_Hinweise 800;
BA_REL_ "GenSigTimeoutTime" BU_SG_REL_ Kombi_PAG SG_ 903 EBKV_Warnungen 800;
BA_REL_ "GenSigTimeoutTime" BU_SG_REL_ Kombi_PAG SG_ 903 EBKV_BKL_Warnungen 800;
BA_REL_ "GenSigTimeoutTime" BU_SG_REL_ Kombi_PAG SG_ 902 CHA_Kombi_Texte 5000;
BA_REL_ "GenSigTimeoutTime" BU_SG_REL_ Kombi_PAG SG_ 902 CHA_Ziel_FahrPr_RWB 5000;
BA_REL_ "GenSigTimeoutTime" BU_SG_REL_ Kombi_PAG SG_ 902 CHA_Current_Mode 5000;
BA_REL_ "GenSigTimeoutTime" BU_SG_REL_ Kombi_PAG SG_ 902 CHA_Offroad_LED 5000;
BA_REL_ "GenSigTimeoutTime" BU_SG_REL_ Kombi_PAG SG_ 902 CHA_Kombi_Texte_02 5000;
BA_REL_ "GenSigTimeoutTime" BU_SG_REL_ Kombi_PAG SG_ 1022 CHA_Current_Mode_BMA 5000;
BA_REL_ "GenSigTimeoutTime" BU_SG_REL_ Kombi_PAG SG_ 1012 DC_Verbrauch_Ueberlauf 1000;
BA_REL_ "GenSigTimeoutTime" BU_SG_REL_ Kombi_PAG SG_ 1012 DC_Verbrauch 1000;
BA_REL_ "GenSigTimeoutTime" BU_SG_REL_ Kombi_PAG SG_ 1714 DGN_Verlernzaehler 5000;
BA_REL_ "GenSigTimeoutTime" BU_SG_REL_ Kombi_PAG SG_ 1714 KBI_Kilometerstand 5000;
BA_REL_ "GenSigTimeoutTime" BU_SG_REL_ Kombi_PAG SG_ 1714 UH_Jahr 5000;
BA_REL_ "GenSigTimeoutTime" BU_SG_REL_ Kombi_PAG SG_ 1714 UH_Monat 5000;
BA_REL_ "GenSigTimeoutTime" BU_SG_REL_ Kombi_PAG SG_ 1714 UH_Tag 5000;
BA_REL_ "GenSigTimeoutTime" BU_SG_REL_ Kombi_PAG SG_ 1714 UH_Stunde 5000;
BA_REL_ "GenSigTimeoutTime" BU_SG_REL_ Kombi_PAG SG_ 1714 UH_Minute 5000;
BA_REL_ "GenSigTimeoutTime" BU_SG_REL_ Kombi_PAG SG_ 1714 UH_Sekunde 5000;
BA_REL_ "GenSigTimeoutTime" BU_SG_REL_ Waehlhebel_SB SG_ 1714 DGN_Verlernzaehler 5000;
BA_REL_ "GenSigTimeoutTime" BU_SG_REL_ Waehlhebel_SB SG_ 1714 KBI_Kilometerstand 5000;
BA_REL_ "GenSigTimeoutTime" BU_SG_REL_ Waehlhebel_SB SG_ 1714 UH_Jahr 5000;
BA_REL_ "GenSigTimeoutTime" BU_SG_REL_ Waehlhebel_SB SG_ 1714 UH_Monat 5000;
BA_REL_ "GenSigTimeoutTime" BU_SG_REL_ Waehlhebel_SB SG_ 1714 UH_Tag 5000;
BA_REL_ "GenSigTimeoutTime" BU_SG_REL_ Waehlhebel_SB SG_ 1714 UH_Stunde 5000;
BA_REL_ "GenSigTimeoutTime" BU_SG_REL_ Waehlhebel_SB SG_ 1714 UH_Minute 5000;
BA_REL_ "GenSigTimeoutTime" BU_SG_REL_ Waehlhebel_SB SG_ 1714 UH_Sekunde 5000;
VAL_ 2463978631 CHA_Drehschalter_VW_Modus 0 "Init_oder_kein_modus_gewaehlt" 1 "Modus_1" 2 "Modus_2" 3 "Modus_3" 4 "Modus_4" 5 "Modus_5" 6 "Modus_6" 7 "Modus_7" 8 "Modus_8" 9 "Modus_9" 10 "Modus_10" 11 "Modus_11" 12 "Modus_12" 13 "Modus_13" 14 "Modus_14" 15 "Fehler" ;
VAL_ 2463978631 CHA_Drehschalter_VW_Mode_Taster 0 "Taste_unbetaetigt" 1 "Taste_betaetigt" 2 "Taste_nicht_verbaut" ;
VAL_ 2463978631 BuA_Charisma_Taste1 0 "Nicht_betaetigt" 1 "Betaetigt" 3 "Fehler" ;
VAL_ 2463978631 BuA_Charisma_Taste2 0 "Nicht_betaetigt" 1 "Betaetigt" 3 "Fehler" ;
VAL_ 2463978631 BuA_Charisma_Taste3 0 "Nicht_betaetigt" 1 "Betaetigt" 3 "Fehler" ;
VAL_ 2463978631 LDT_Drehschalter_Betaetigt 0 "Taste_nicht_betaetigt" 1 "Taste_entprellt_betaetigt" 2 "Init_oder_nicht_verbaut" 3 "Fehler" ;
VAL_ 2463978631 LDT_Drehschalter_Hoch 0 "Taste_nicht_betaetigt" 1 "Taste_entprellt_betaetigt" 2 "Init_oder_nicht_verbaut" 3 "Fehler" ;
VAL_ 2463978631 LDT_Drehschalter_Modus 0 "Init" 1 "Ladelevel" 2 "Strassenlevel" 3 "Offroadlevel" 4 "XtraLevel" 5 "Reserve" 6 "Reserve" 7 "Reserve" 8 "Reserve" 9 "Reserve" 10 "Reserve" 11 "Reserve" 12 "Reserve" 13 "Reserve" 14 "Reserve" 15 "Reserve" ;
VAL_ 2463978631 LDT_Drehschalter_Tief 0 "Taste_nicht_betaetigt" 1 "Taste_entprellt_betaetigt" 2 "Init_oder_nicht_verbaut" 3 "Fehler" ;
VAL_ 2463978631 LDT_Sync_Betaetigt 0 "Taste_nicht_betaetigt" 1 "Taste_entprellt_betaetigt" 2 "Init_oder_nicht_verbaut" 3 "Fehler" ;
VAL_ 2463978631 AST_Laengssperre 0 "Nicht_betaetigt" 1 "Betaetigt" 3 "Fehler" ;
VAL_ 2463978631 AST_Low 0 "Nicht_betaetigt" 1 "Betaetigt" 3 "Fehler" ;
VAL_ 2463978631 AST_Quersperre 0 "Nicht_betaetigt" 1 "Betaetigt" 3 "Fehler" ;
VAL_ 2463978631 CHA_Drehschalter_VW_defekt 0 "kein_Fehler" 1 "Fehler" ;
VAL_ 1615 CHA_Kombi_Texte 0 "keine_Anzeige" 1 "Text_1" 2 "Text_2" 3 "Text_3" 4 "Text_4" 5 "Text_5" 6 "Text_6" 7 "Text_7" 8 "Text_8" 9 "Text_9" 10 "Text_10" 11 "Text_11" 12 "Text_12" 13 "Text_13" 14 "Text_14" 15 "Text_15" ;
VAL_ 1615 BCM1_HUD_Eyeboxposition_Status 0 "Position_gueltig_keine_Aenderung" 1 "Drehung_im_Uhrzeigersinn" 2 "Drehung_entgegen_dem_Uhrzeigersinn" 3 "Position_ungueltig" ;
VAL_ 1615 BCM1_HUD_Taster 0 "Taster_nicht_betaetigt" 1 "Taster_betaetigt" ;
VAL_ 1615 BCM1_Stellgroesse_Kl_58s 125 "Nicht_verbaut" 126 "Init" 127 "Fehler" ;
VAL_ 1615 BCM1_LDS_Stellung 0 "Init" 1 "Stellung_0" 2 "Auto" 3 "Standlicht" 4 "Abblendlicht" 7 "Fehler" ;
VAL_ 1615 BCM1_Lichtwarn_Texte 0 "keine_Warnung" 1 "Standlichtwarnung" 2 "Parklichtwarnung" 3 "Nebelschlusslichtwarnung" ;
VAL_ 1615 CHA_Drehschalter_Modus 0 "Init_oder_kein_modus_gewaehlt" 1 "Modus_1" 2 "Modus_2" 3 "Modus_3" 4 "Modus_4" 5 "Modus_5" 6 "Modus_6" 7 "Modus_7" 8 "Modus_8" 9 "Modus_9" 10 "Modus_10" 11 "Modus_11" 12 "Modus_12" 13 "Modus_13" 14 "Modus_14" 15 "Fehler" ;
VAL_ 1615 KRH_Stufe_LED_li 0 "Aus" 1 "Stufe_1" 2 "Stufe_2" 3 "Stufe_3" ;
VAL_ 1615 KRH_Stufe_LED_re 0 "Aus" 1 "Stufe_1" 2 "Stufe_2" 3 "Stufe_3" ;
VAL_ 1615 BCM1_Spannungs_Anf 0 "keine_Anforderung" 1 "Anforderung_Stufe_1" 2 "Anforderung_Stufe_2" 3 "Anforderung_Stufe_3" ;
VAL_ 1615 LV_Laserlicht_Texte 0 "keine_Anzeige" 1 "temporaerer_Fehler" 2 "Systemfehler" ;
VAL_ 1615 BCM1_Hinweis_Lichtnachlauf 0 "inaktiv" 1 "aktiv" ;
VAL_ 1615 LV_LED_Scheinwerfer_li_def 0 "OK" 1 "defekt" ;
VAL_ 1615 LV_LED_Scheinwerfer_re_def 0 "OK" 1 "defekt" ;
VAL_ 1615 BCM1_Status_Ladeanzeige 0 "Anzeige_aktuell_nicht_moeglich" 1 "Anzeige_moeglich" 2 "Anzeige_aktiv" ;
VAL_ 1626 BCM_Bremsbelag_Sensor 0 "OK" 1 "Bremsbelag_unter_min" ;
VAL_ 1626 BCM_Bremsfluessigkeit_Sensor 0 "OK" 1 "Bremsfluessigkeit_unter_min" ;
VAL_ 1626 BCM1_Licht_Warn 0 "OK" 1 "Lichtwarnung_aktiv" ;
VAL_ 1626 BCM_Waschwasser_Sensor 0 "OK" 1 "Waschwasser_unter_min" ;
VAL_ 1626 BCM_Kuehlmittel_Sensor 0 "OK" 1 "Kuehlmittel_unter_min" ;
VAL_ 1626 BCM1_Kl_15_HW_erkannt 1 "Klemme 15 erkannt" ;
VAL_ 1626 BCM1_Kl_15_Sig_HW_erkannt 0 "KL15_HW_Signal_von_BCM1_nicht_erkannt" 1 "KL15_HW_Signal_von_BCM1_erkannt" ;
VAL_ 1626 BCM_Kuehlmittel_Sensor_02 0 "OK" 1 "Kuehlmittel_unter_min" ;
VAL_ 1626 BCM1_Hinweis_Lichtnachlauf 0 "inaktiv" 1 "aktiv" ;
VAL_ 1626 BCM_Offroad_Taste 0 "Taster_nicht_betaetigt" 1 "Taster_betaetigt" ;
VAL_ 1626 BCM_Hybrid_StSt_Taste_Fehler 0 "kein_Fehler_StSt_Taster" 1 "Fehler_StSt_Taster" ;
VAL_ 1626 BCM_Hybrid_StartStopp_Taste 0 "nicht_betaetigt" 1 "betaetigt" ;
VAL_ 1626 BCM1_Warnblink_Taster 0 "nicht_betaetigt" 1 "betaetigt" ;
VAL_ 1626 BCM1_Valet_Parking_Taster 0 "nicht_betaetigt" 1 "betaetigt" ;
VAL_ 1626 BCM1_LDS_Stellung 0 "Init" 1 "Stellung_0" 2 "Auto" 3 "Standlicht" 4 "Abblendlicht" 7 "Fehler" ;
VAL_ 1626 BCM1_Rueckfahrlicht_Schalter 0 "nicht_betaetigt" 1 "betaetigt" ;
VAL_ 1626 BCM1_MH_Schalter 0 "MH_geschlossen" 1 "MH_offen" ;
VAL_ 1626 BCM1_MH_WIV_Schalter 0 "MH_geschlossen" 1 "MH_offen" ;
VAL_ 1626 BCM_Eco_Charisma_Taste 0 "nicht_betaetigt" 1 "betaetigt" ;
VAL_ 1626 BCM1_NV_Taster 0 "Taster_nicht_betaetigt" 1 "Taster_betaetigt" ;
VAL_ 1626 BCM1_AFS_Lampe 0 "Aus" 1 "Ein" ;
VAL_ 1626 BCM1_Reisemodus_Texte 0 "keine_Anzeige" 1 "Umschaltung_auf_Linksverkehr_aktiv" 2 "Umschaltung_auf_Rechtsverkehr_aktiv" ;
VAL_ 1626 BCM1_Lichtwarn_Texte 0 "keine_Warnung" 1 "Standlichtwarnung" 2 "Parklichtwarnung" 3 "Nebelschlusslichtwarnung" ;
VAL_ 1626 Gong_TFL_Umschaltung 0 "kein_Gong" 1 "Gong_einmalig" ;
VAL_ 1626 UGDO_Function_01 0 "LED Function" 1 "Transceiver locked" 2 "reserviert" 3 "reserviert" 4 "Successful learned" 5 "reserviert" 6 "Timeout learning" 7 "Fehler" ;
VAL_ 1626 APS_Tongeber_defekt 0 "iO" 1 "defekt" ;
VAL_ 1626 BCM1_EasyEntry_Status 0 "Aus" 1 "Ein" ;
VAL_ 1626 BCM1_Lenksaeule_aktiv 0 "Lenksaeulenverstellung nicht aktiv" 1 "Lenksaeulenverstellung aktiv" ;
VAL_ 1626 BCM1_St_SW_Diebstahl_links 0 "Kein DIebstahl erkannt" 1 "Diebstahl erkannt" ;
VAL_ 1626 BCM1_St_SW_Diebstahl_rechts 0 "Kein DIebstahl erkannt" 1 "Diebstahl erkannt" ;
VAL_ 1626 BCM1_Schluesselsuche_Anf 0 "Anforderung_nicht_aktiv" 1 "Anforderung_aktiv" ;
VAL_ 1626 BCM1_Fahrlicht_Hinweis 0 "kein_Fahrlicht_Hinweis" 1 "Fahrlicht_Hinweis" ;
VAL_ 1626 BCM_HDF_betaetigt 0 "nicht_betaetigt" 1 "betaetigt" ;
VAL_ 672 BCM2_Crashfall_erkannt 0 "kein_Crashfall_erkannt" 1 "Crashfall_erkannt" ;
VAL_ 672 ZZH_Endlage_oben 0 "ZZH_nicht_in_oberer_Endlage" 1 "ZZH in Endlage oben" ;
VAL_ 672 ZZH_Endlage_unplausibel 0 "Endlage_ZZH_plausibel" 1 "unplausible Endlage der ZZH erkannt" ;
VAL_ 672 ZZH_Endlage_unten 0 "ZZH_nicht_in_unterer_Endlage" 1 "ZZH in Endlage unten" ;
VAL_ 672 BCM2_Unterdr_Zuendungsmeldung 0 "keine_Unterdr_der_Zuendungsmeldung" 1 "Unterdr_der_Zuendungsmeldung_aktiv" ;
VAL_ 672 BCM2_SST_gedrueckt 1 "SST gedrueckt" ;
VAL_ 672 BCM_Waehlhebel_P_Hinweis 0 "inaktiv" 1 "aktiv" ;
VAL_ 672 BCM_ValetTaster_Fkts_LED 0 "LED_aus" 1 "LED_ein" ;
VAL_ 672 BCM2_KL15_Absch_FT 0 "Zuendung_wurde_bei_Verl_nicht_deaktiviert" 1 "Zuendung_wurde_bei_Verl_deaktiviert" ;
VAL_ 672 Heckwischer_Status 0 "Init (kein Fehler, keine Ansteuerung)" 1 "Fehler / keine Ansteuerung" 2 "kein Fehler/ Ansteuerung aktiv" 3 "Fehler/ Ansteuerung aktiv" ;
VAL_ 672 BCM2_P_verriegelt 0 "WH nicht in Stellung P" 1 "WH in Stellung P" ;
VAL_ 672 FSH_LED 0 "Aus" 1 "Ein" ;
VAL_ 672 HSH_LED 0 "Aus" 1 "Ein" ;
VAL_ 672 Niveausensor_VL_verbaut 0 "nicht_verbaut" 1 "verbaut" ;
VAL_ 672 Niveausensor_HL_verbaut 0 "nicht_verbaut" 1 "verbaut" ;
VAL_ 672 FA_Hoehenwert_VL_01 254 "nicht initialisiert" 255 "Fehler" ;
VAL_ 672 FA_Hoehenwert_HL_01 254 "nicht initialisiert" 255 "Fehler" ;
VAL_ 672 BCM_Anf_Aussenwarnung 0 "nicht_angefordert" 1 "angefordert" ;
VAL_ 672 BCM_Aussenwarnung_Konfig 0 "Anforderungssignal wird 1:1 übernommen" 1 "1 Warnton" 2 "2 Warntöne" 3 "3 Warntöne" 4 "4 Warntöne" 5 "5 Warntöne" 6 "6 Warntöne" 7 "dauerhafte Sequenz bei aktivem Anforderungssignal" ;
VAL_ 672 BCM2_Freigabe_Kofferr_Innenentr 0 "keine_Freigabe" 1 "Freigabe" ;
VAL_ 672 BCM_RLU_Wakeup_Anforderung 0 "inaktiv" 1 "aktiv" ;
VAL_ 672 Heckrollo_Privacy_aktiv 0 "inaktiv" 1 "aktiv" ;
VAL_ 672 Heckrollo_Verfahrrichtung 0 "Init" 1 "Ruhe_unten" 2 "Heben" 3 "Senken" 4 "Ruhe_oben" 5 "reserviert" 6 "reserviert" 7 "reserviert" ;
VAL_ 672 BCM2_TrunkEntrapment_Warn 0 "Anzeige_Aus" 1 "Anzeige_Ein" ;
VAL_ 672 BCM2_Quittierung_Warnton_aktiv 0 "keine_Quittierung_Warnton_aktiv" 1 "Quittierung_Warnton_aktiv" ;
VAL_ 672 BCM_Handbremse_Hinweis 0 "inaktiv" 1 "aktiv" ;
VAL_ 672 Remote_Rollo_HBFS_hoch 0 "inaktiv" 1 "aktiv" ;
VAL_ 672 Remote_Rollo_HBFS_tief 0 "inaktiv" 1 "aktiv" ;
VAL_ 672 Remote_Rollo_HFS_hoch 0 "inaktiv" 1 "aktiv" ;
VAL_ 672 Remote_Rollo_HFS_tief 0 "inaktiv" 1 "aktiv" ;
VAL_ 672 BCM2_T_Deckel_Vorne 0 "nicht_betaetigt" 1 "betaetigt" ;
VAL_ 2527679637 CPD_Warnung 0 "keine_Warnung" 1 "Warnung_mit_Ton" 2 "Warnung_ohne_Ton" ;
VAL_ 2527679637 BCM_LTM_Nebelschluss_Status 0 "nicht_aktiv" 1 "aktiv" ;
VAL_ 2527679637 BCM_LTM_PopUp_Texte 0 "keine_Anzeige" 1 "Ausschalt_Hinweis" 2 "Ausschalt_Quittierung" ;
VAL_ 2527679637 BCM_LTM_Allwetterl_Status 0 "nicht_aktiv" 1 "aktiv" ;
VAL_ 2527679637 BCM_LTM_PopUp_Status 0 "Init" 1 "AUTO" 2 "Abblendlicht" 3 "Standlicht" 4 "OFF" ;
VAL_ 2527679637 BCM_LTM_Nebell_Status 0 "nicht_aktiv" 1 "aktiv" ;
VAL_ 2527679637 BCM_LTM_PopUp_Anf 0 "keine_Anforderung" 1 "Licht_PopUp" 2 "Nebellicht_PopUp" 3 "Allwetterlicht_PopUp" 4 "Nebelschlusslicht_PopUp" ;
VAL_ 2527679637 BCM_LTM_PopUp_Inhalt 0 "Init" 1 "AUTO" 2 "Abblendlicht" 4 "Standlicht" 8 "OFF" ;
VAL_ 870 BM_ZV_auf 0 "inaktiv" 1 "aktiv" ;
VAL_ 870 BM_ZV_zu 0 "inaktiv" 1 "aktiv" ;
VAL_ 870 BM_DWA_ein 0 "inaktiv" 1 "aktiv" ;
VAL_ 870 BM_DWA_Alarm 0 "inaktiv" 1 "aktiv" ;
VAL_ 870 BM_Crash 0 "inaktiv" 1 "aktiv" ;
VAL_ 870 BM_Panik 0 "inaktiv" 1 "aktiv" ;
VAL_ 870 BM_Not_Bremsung 0 "kein_blinken" 1 "Notbremswarnblinken_aktiv" ;
VAL_ 870 BM_GDO 0 "inaktiv" 1 "aktiv" ;
VAL_ 870 BM_Warnblinken 0 "inaktiv" 1 "aktiv" ;
VAL_ 870 BM_Taxi_Notalarm 0 "inaktiv" 1 "aktiv" ;
VAL_ 870 BM_Telematik 0 "inaktiv" 1 "aktiv" ;
VAL_ 870 BM_links 0 "inaktiv" 1 "aktiv" ;
VAL_ 870 BM_rechts 0 "inaktiv" 1 "aktiv" ;
VAL_ 870 Blinken_li_Fzg_Takt 0 "Blinker_links_ausgeschaltet" 1 "Blinker_links_eingeschaltet" ;
VAL_ 870 Blinken_re_Fzg_Takt 0 "Blinker_rechts_ausgeschaltet" 1 "Blinker_rechts_eingeschaltet" ;
VAL_ 870 Blinken_li_Kombi_Takt 0 "Blinkerkontrolllampe_links_ausgeschaltet" 1 "Blinkerkontrolllampe_links_eingeschaltet" ;
VAL_ 870 Blinken_re_Kombi_Takt 0 "Blinkerkontrolllampe_rechts_ausgeschaltet" 1 "Blinkerkontrolllampe_rechts_eingeschaltet" ;
VAL_ 870 BM_NBA_n_codiert_n_aktiv 0 "codiert_AND_kein_Fehler" 1 "nicht_codiert_OR_Fehler_erkannt" ;
VAL_ 870 BM_NBA_Status 0 "NBA_nicht_aktiv" 1 "BRL_Dunkelphase" 3 "BRL_Hellphase" ;
VAL_ 870 BM_WBT_Beleuchtung 0 "inaktiv" 1 "aktiv" ;
VAL_ 870 BM_HD_Oeffnung_angelernt 0 "keine_Quittierung" 1 "Quittierung" ;
VAL_ 870 BM_Autobahn 0 "inaktiv" 1 "aktiv" ;
VAL_ 870 BM_Rollenmodus_Blinken 0 "inaktiv" 1 "aktiv" ;
VAL_ 870 BM_Recas 0 "kein_blinken" 1 "Recasblinken_aktiv" ;
VAL_ 870 BM_Wischblinken 0 "inaktiv" 1 "aktiv" ;
VAL_ 870 BM_Telematik_Abbruchgrund 0 "Init" 1 "speed_out_of_range" 2 "defect" 3 "clamp_s_on" 4 "clamp_15_on" 5 "door_open" 6 "engine_hood_open" 7 "trunk_open" 8 "convertible_top_not_locked" 9 "horn_activated_by_user" 10 "Higher_Prioritiy_Function_active" 11 "Central_Lock_status_changed" 12 "Request_Dropped_by_Requester" 13 "Service_Duration_Expired" 14 "not_possible_due_to_coding" 15 "no_reason_or_unknown_timeout" ;
VAL_ 870 BM_PiloPa 0 "PiloPa_Blinkerquittierung_inaktiv" 1 "PiloPa_Blinkerquittierung_aktiv" ;
VAL_ 870 DWA_Alarmquelle 0 "kein_Ausloesegrund" 1 "Tuerkontakt_Fahrertuer" 2 "Tuerkontakt_Beifahrertuer" 3 "Tuerkontakt_hinten_links" 4 "Tuerkontakt_hinten_rechts" 5 "Motorhaubenkontakt_vorne" 6 "Kofferraum_hinten" 7 "Masseschleife_der_Heckscheibe" 8 "Innenraumueberwachung" 9 "Alarm_durch_Noteinstieg" 10 "Sounder" 11 "Neigungssensor" 12 "TSG_FT_am_CAN_Bus" 13 "TSG_BT_am_CAN_Bus" 14 "TSG_HFS_am_CAN_Bus" 15 "TSG_HBFS_am_CAN_Bus" 16 "Klemme_15" 17 "Klemme_15sig" 18 "frei" 19 "Anhaengerueberwachung" 20 "Scheinwerferueberwachung_links" 21 "Scheinwerferueberwachung_rechts" 22 "Handschuhkasten" 23 "Verdeckueberwachung" 24 "OBD_Alarm" 25 "Power_on_Reset" 30 "Init" 31 "Fehler" ;
VAL_ 868 NBlinken_li_Fzg_Takt 0 "Blinker_links_ausgeschaltet" 1 "Blinker links eingeschaltet" ;
VAL_ 868 NBlinken_re_Fzg_Takt 0 "Blinker rechts ausgeschaltet" 1 "Blinker rechts eingeschaltet" ;
VAL_ 868 NBlinken_li_Kombi_Takt 0 "Blinkerkontrolllampe_links_ausgeschaltet" 1 "Blinkerkontrolllampe_links_eingeschaltet" ;
VAL_ 868 NBlinken_re_Kombi_Takt 0 "Blinkerkontrolllampe rechts ausgeschaltet" 1 "Blinkerkontrolllampe rechts eingeschaltet" ;
VAL_ 687 BMS_As_Entladezaehler_Ueberlauf 0 "kein_Ueberlauf" 1 "Ueberlauf" ;
VAL_ 687 BMS_Rekuperation_Ueberlauf 0 "kein_Ueberlauf" 1 "Ueberlauf" ;
VAL_ 687 BMS_Verbrauch_Ueberlauf 0 "kein_Ueberlauf" 1 "Ueberlauf" ;
VAL_ 1438 BMS_Temperierung_Anf 0 "hoher_Kuehlbedarf" 1 "mittlerer_Kuehlbedarf" 2 "niedriger_Kuehlbedarf" 3 "kein_Temperierungsbedarf_Init" 4 "niedriger_Heizbedarf" 5 "mittlerer_Heizbedarf" 6 "hoher_Heizbedarf" 7 "Umwaelzungsbedarf" ;
VAL_ 1438 BMS_Status_Ventil 0 "Ventil_nicht_angesteuert" 1 "Ventil_angesteuert" 2 "reserviert" 3 "reserviert" 4 "reserviert" 5 "Ventil_nicht_verbaut" 6 "Init" 7 "Fehler" ;
VAL_ 1438 BMS_Soll_PWM_Pumpe 14 "Fehler" 15 "Init" ;
VAL_ 1438 BMS_Temperatur 254 "Init" 255 "Fehler" ;
VAL_ 1438 BMS_IstVorlaufTemperatur 254 "Init" 255 "Fehler" ;
VAL_ 1438 BMS_Fehler_NTKreis 0 "kein_Fehler" 1 "Fehler" ;
VAL_ 1438 BMS_Fehlerstatus_EWP_02 0 "Diagnose_nicht_durchgefuehrt" 1 "Pumpe_iO" 2 "Diagnose_laeuft" 3 "Pumpe_iO_Diagnose_laeuft" 4 "Blockade_Trockenlauf" 5 "Pumpe_stromlos" 6 "Blockade_Trockenlauf_Diag_laeuft" 7 "Fehler" ;
VAL_ 1438 BMS_SollVolumenstrom 62 "Init" 63 "Fehler" ;
VAL_ 1438 BMS_Batterie_Voko_Anf 0 "keine_Voko_angefordert" 1 "Voko_angefordert" ;
VAL_ 1438 BMS_SollVorlauftemperatur 254 "Init" 255 "Fehler" ;
VAL_ 1438 BMS_IstRuecklaufTemperatur_02 254 "Init" 255 "Fehler" ;
VAL_ 1482 BMS_Energieinhalt 2046 "Init" 2047 "Fehler" ;
VAL_ 1482 BMS_Ladevorgang_aktiv 0 "inaktiv" 1 "aktiv" ;
VAL_ 1482 BMS_Batteriediagnose 1 "Anzeige_Batterie" 4 "Anzeige_Batterie_OK" 5 "Anzeige_Batterie_Laden" 6 "Anzeige_Batterie_Pruefen" 7 "Fehler" ;
VAL_ 1482 BMS_Freig_max_Performanz 0 "Init" 1 "verfuegbar" 2 "nicht_verfuegbar" 3 "eingeschraenkt_verfuegbar" ;
VAL_ 1482 BMS_Balancing_Aktiv 0 "Init" 1 "aktiv" 2 "nicht_aktiv" ;
VAL_ 1482 BMS_MaxEnergieinhalt 2046 "Init" 2047 "Fehler" ;
VAL_ 1482 BMS_Ausgleichsladung_Anf 1 "Balancing_Request" ;
VAL_ 1482 BMS_Gesamtst_Spgfreiheit 0 "Funktion_nicht_aktiviert" 1 "HV_System_spannungsfrei" 2 "HV_System_nicht_spannungsfrei" 3 "Fehler_nicht_spannungsfrei" ;
VAL_ 1482 BMS_RIso_Ext 4094 "Init" 4095 "Fehler" ;
VAL_ 1482 BMS_KundenWarnung 0 "keine_Warnung" 1 "Warnung_Temperatur_Level1" 2 "Warnung_Temperatur_Level2" ;
VAL_ 1482 BMS_Fehler_KuehlkreislaufLeckage 0 "kein_Fehler" 1 "Fehler_KuehlkreislaufLeckage" ;
VAL_ 1289 BMS_Energieinhalt_HiRes 32766 "Init" 32767 "Fehler" ;
VAL_ 1289 BMS_MaxEnergieinhalt_HiRes 32766 "Init" 32767 "Fehler" ;
VAL_ 1289 BMS_NutzbarerSOC 254 "Init" 255 "Fehler" ;
VAL_ 1289 BMS_NutzbarerEnergieinhalt 4094 "Init" 4095 "Fehler" ;
VAL_ 1289 BMS_Pred_Entladeperformance 126 "Init" 127 "Fehler" ;
VAL_ 1289 BMS_Pred_Ladeperformance 126 "Init" 127 "Fehler" ;
VAL_ 2463978838 BMS_ZellTemp_virtuell_max 253 "Nicht_verfuegbar" 254 "Init" 255 "Fehler" ;
VAL_ 2463978838 BMS_ZellTemp_virtuell_min 253 "Nicht_verfuegbar" 254 "Init" 255 "Fehler" ;
VAL_ 2463978838 BMS_NutzbarerEnergieinhalt_HiRes 0 "nicht_verbaut" 32766 "Init" 32767 "Fehler" ;
VAL_ 2589284070 BMS_ExtLadeleistung 1022 "Init" 1023 "Fehler" ;
VAL_ 903 EBKV_OBD_Status 0 "MIL_aus" 1 "MIL_ein" ;
VAL_ 903 EBKV_Hinweise 0 "i_O_System" 1 "Werkstattdiagnose" 2 "Rollenmodes" 3 "Uebernahme_Feststellbremse" ;
VAL_ 903 EBKV_Warnungen 0 "i_O_System" 1 "Ausfall_2nd_Aktuator" 2 "Reduktion_Bremsverstaerkung" 3 "Ausfall_eBKV_ohne_HBV" 4 "Ausfall_Stillstandsmanagement" ;
VAL_ 903 EBKV_BKL_Warnungen 0 "i_O_System" 1 "Lampen_Pruefung" 2 "Ausfall_eBKV_und_HBV" ;
VAL_ 903 EBKV_Charisma_FahrPr 0 "keine_Funktion" 1 "Programm_1" 2 "Programm_2" 3 "Programm_3" 4 "Programm_4" 5 "Programm_5" 6 "Programm_6" 7 "Programm_7" 8 "Programm_8" 9 "Programm_9" 10 "Programm_10" 11 "Programm_11" 12 "Programm_12" 13 "Programm_13" 14 "Programm_14" 15 "Programm_15" ;
VAL_ 903 EBKV_Charisma_Status 0 "Init" 1 "verfuegbar" 2 "nicht_verfuegbar" 3 "asynchron_durch_Fahrerwunsch" ;
VAL_ 902 CHA_Drive_Select1_LED 0 "LED_aus" 1 "LED_ein" 2 "LED_blinken" 3 "init" ;
VAL_ 902 CHA_Eco_Charisma_LED 0 "LED_aus_und_Blinken_aus" 1 "LED_ein_und_Blinken_aus" 2 "LED_ein_und_Blinken_ein_50_percent" 3 "reserviert" ;
VAL_ 902 CHA_Fahrer_Umschaltung 0 "keine_oder_automatische_Umschaltung" 1 "manuelle_Umschaltung" ;
VAL_ 902 CHA_EV_LED 0 "LED_aus" 1 "LED_an" ;
VAL_ 902 CHA_Ziel_FahrPr_AMB 0 "keine_Funktion" 1 "Programm_1" 2 "Programm_2" 3 "Programm_3" 4 "Programm_4" 5 "Programm_5" 6 "Programm_6" 7 "Programm_7" 8 "Programm_8" 9 "Programm_9" 10 "Programm_10" 11 "Programm_11" 12 "Programm_12" 13 "Programm_13" 14 "Programm_14" 15 "Programm_15" ;
VAL_ 902 CHA_Ziel_FahrPr_IVB 0 "keine_Funktion" 1 "Programm_1" 2 "Programm_2" 3 "Programm_3" 4 "Programm_4" 5 "Programm_5" 6 "Programm_6" 7 "Programm_7" 8 "Programm_8" 9 "Programm_9" 10 "Programm_10" 11 "Programm_11" 12 "Programm_12" 13 "Programm_13" 14 "Programm_14" 15 "Programm_15" ;
VAL_ 902 CHA_Kombi_Texte 0 "keine_Anzeige" 1 "Text_1" 2 "Text_2" 3 "Text_3" 4 "Text_4" 5 "Text_5" 6 "Text_6" 7 "Text_7" 8 "Text_8" 9 "Text_9" 10 "Text_10" 11 "Text_11" 12 "Text_12" 13 "Text_13" 14 "Text_14" 15 "Text_15" ;
VAL_ 902 CHA_Ziel_FahrPr_KL 0 "keine_Funktion" 1 "Programm_1" 2 "Programm_2" 3 "Programm_3" 4 "Programm_4" 5 "Programm_5" 6 "Programm_6" 7 "Programm_7" 8 "Programm_8" 9 "Programm_9" 10 "Programm_10" 11 "Programm_11" 12 "Programm_12" 13 "Programm_13" 14 "Programm_14" 15 "Programm_15" ;
VAL_ 902 CHA_Ziel_FahrPr_HSP 0 "keine_Funktion" 1 "Programm_1" 2 "Programm_2" 3 "Programm_3" 4 "Programm_4" 5 "Programm_5" 6 "Programm_6" 7 "Programm_7" 8 "Programm_8" 9 "Programm_9" 10 "Programm_10" 11 "Programm_11" 12 "Programm_12" 13 "Programm_13" 14 "Programm_14" 15 "Programm_15" ;
VAL_ 902 CHA_Drehschalter_Istmodus 0 "keine_Schalterstellung" 1 "Schalterstellung_1" 2 "Schalterstellung_2" 3 "Schalterstellung_3" 4 "Schalterstellung_4" 5 "Schalterstellung_5" 6 "Schalterstellung_6" 7 "Schalterstellung_7" 8 "Schalterstellung_8" 9 "Schalterstellung_9" 10 "Schalterstellung_10" 11 "Schalterstellung_11" 12 "Schalterstellung_12" 13 "Schalterstellung_13" 14 "Schalterstellung_14" 15 "Schalterstellung_15" ;
VAL_ 902 CHA_Ziel_FahrPr_RWB 0 "keine_Funktion" 1 "Programm_1" 2 "Programm_2" 3 "Programm_3" 4 "Programm_4" 5 "Programm_5" 6 "Programm_6" 7 "Programm_7" 8 "Programm_8" 9 "Programm_9" 10 "Programm_10" 11 "Programm_11" 12 "Programm_12" 13 "Programm_13" 14 "Programm_14" 15 "Programm_15" ;
VAL_ 902 CHA_Ziel_FahrPr_03_01 0 "keine_Funktion" 1 "Programm_1" 2 "Programm_2" 3 "Programm_3" 4 "Programm_4" 5 "Programm_5" 6 "Programm_6" 7 "Programm_7" 8 "Programm_8" 9 "Programm_9" 10 "Programm_10" 11 "Programm_11" 12 "Programm_12" 13 "Programm_13" 14 "Programm_14" 15 "Programm_15" ;
VAL_ 902 CHA_Ziel_FahrPr_03_02 0 "keine_Funktion" 1 "Programm_1" 2 "Programm_2" 3 "Programm_3" 4 "Programm_4" 5 "Programm_5" 6 "Programm_6" 7 "Programm_7" 8 "Programm_8" 9 "Programm_9" 10 "Programm_10" 11 "Programm_11" 12 "Programm_12" 13 "Programm_13" 14 "Programm_14" 15 "Programm_15" ;
VAL_ 902 CHA_Current_Mode 0 "keine_Funktion" 1 "Programm_1" 2 "Programm_2" 3 "Programm_3" 4 "Programm_4" 5 "Programm_5" 6 "Programm_6" 7 "Programm_7" 8 "Programm_8" 9 "Programm_9" 10 "Programm_10" 11 "Programm_11" 12 "Programm_12" 13 "Programm_13" 14 "Programm_14" 15 "Programm_15" ;
VAL_ 902 CHA_Charge_LED 0 "LED_aus" 1 "LED_ein" ;
VAL_ 902 CHA_Offroad_LED 0 "LED_aus" 1 "LED_ein" 2 "LED_blinken" 3 "Fehler" ;
VAL_ 902 CHA_Kombi_Texte_02 0 "Init" 1 "Text_1" 2 "Text_2" 3 "Text_3" 4 "Text_4" 5 "Text_5" 6 "Text_6" 7 "Text_7" 8 "Text_8" 9 "Text_9" 10 "Text_10" 11 "Text_11" 12 "Text_12" 13 "Text_13" 14 "Text_14" 15 "Text_15" ;
VAL_ 1022 CHA_Fahrer_Umschaltung 0 "keine_oder_automatische_Umschaltung" 1 "manuelle_Umschaltung" ;
VAL_ 1022 CHA_Fahrer_Umschaltung_BMA 0 "keine_oder_autom_Umschaltung" 1 "manuelle_Umschaltung" ;
VAL_ 1022 CHA_Ziel_FahrPr_Reku_ZwGas 0 "kein_Funktion" 1 "Programm_1" 2 "Programm_2" 3 "Programm_3" 4 "Programm_4" 5 "Programm_5" 6 "Programm_6" 7 "Programm_7" 8 "Programm_8" 9 "Programm_9" 10 "Programm_10" 11 "Programm_11" 12 "Programm_12" 13 "Programm_13" 14 "Programm_14" 15 "Programm_15" ;
VAL_ 1022 CHA_Ziel_FahrPr_MO_Freilauf 0 "keine_Funktion" 1 "Programm_1" 2 "Programm_2" 3 "Programm_3" 4 "Programm_4" 5 "Programm_5" 6 "Programm_6" 7 "Programm_7" 8 "Programm_8" 9 "Programm_9" 10 "Programm_10" 11 "Programm_11" 12 "Programm_12" 13 "Programm_13" 14 "Programm_14" 15 "Programm_15" ;
VAL_ 1022 CHA_Ziel_FahrPr_BMS 0 "keine_Funktion" 1 "Programm_1" 2 "Programm_2" 3 "Programm_3" 4 "Programm_4" 5 "Programm_5" 6 "Programm_6" 7 "Programm_7" 8 "Programm_8" 9 "Programm_9" 10 "Programm_10" 11 "Programm_11" 12 "Programm_12" 13 "Programm_13" 14 "Programm_14" 15 "Programm_15" ;
VAL_ 1022 CHA_Current_Mode_BMA 0 "keine_Funktion" 1 "Programm_1" 2 "Programm_2" 3 "Programm_3" 4 "Programm_4" 5 "Programm_5" 6 "Programm_6" 7 "Programm_7" 8 "Programm_8" 9 "Programm_9" 10 "Programm_10" 11 "Programm_11" 12 "Programm_12" 13 "Programm_13" 14 "Programm_14" 15 "Programm_15" ;
VAL_ 1022 CHA_Ziel_FahrPr_PDC 0 "keine_Funktion" 1 "Programm_1" 2 "Programm_2" 3 "Programm_3" 4 "Programm_4" 5 "Programm_5" 6 "Programm_6" 7 "Programm_7" 8 "Programm_8" 9 "Programm_9" 10 "Programm_10" 11 "Programm_11" 12 "Programm_12" 13 "Programm_13" 14 "Programm_14" 15 "Programm_15" ;
VAL_ 1022 CHA_Ziel_FahrPr_HHC 0 "keine_Funktion" 1 "Programm_1" 2 "Programm_2" 3 "Programm_3" 4 "Programm_4" 5 "Programm_5" 6 "Programm_6" 7 "Programm_7" 8 "Programm_8" 9 "Programm_9" 10 "Programm_10" 11 "Programm_11" 12 "Programm_12" 13 "Programm_13" 14 "Programm_14" 15 "Programm_15" ;
VAL_ 1022 CHA_Ziel_FahrPr_EDS 0 "keine_Funktion" 1 "Programm_1" 2 "Programm_2" 3 "Programm_3" 4 "Programm_4" 5 "Programm_5" 6 "Programm_6" 7 "Programm_7" 8 "Programm_8" 9 "Programm_9" 10 "Programm_10" 11 "Programm_11" 12 "Programm_12" 13 "Programm_13" 14 "Programm_14" 15 "Programm_15" ;
VAL_ 1022 CHA_Ziel_FahrPr_PACC 0 "keine_Funktion" 1 "Programm_1" 2 "Programm_2" 3 "Programm_3" 4 "Programm_4" 5 "Programm_5" 6 "Programm_6" 7 "Programm_7" 8 "Programm_8" 9 "Programm_9" 10 "Programm_10" 11 "Programm_11" 12 "Programm_12" 13 "Programm_13" 14 "Programm_14" 15 "Programm_15" ;
VAL_ 1022 CHA_Ziel_FahrPr_AGK 0 "keine_Funktion" 1 "Programm_1" 2 "Programm_2" 3 "Programm_3" 4 "Programm_4" 5 "Programm_5" 6 "Programm_6" 7 "Programm_7" 8 "Programm_8" 9 "Programm_9" 10 "Programm_10" 11 "Programm_11" 12 "Programm_12" 13 "Programm_13" 14 "Programm_14" 15 "Programm_15" ;
VAL_ 2463978630 CHA_Charisma_LED1 0 "Aus" 1 "Ein" 2 "Blinken" ;
VAL_ 2463978630 CHA_Charisma_LED2 0 "Aus" 1 "Ein" 2 "Blinken" ;
VAL_ 2463978630 CHA_Charisma_LED3 0 "Aus" 1 "Ein" 2 "Blinken" ;
VAL_ 2463978630 CHA_Drehschalter_VW_Mode_LED 0 "LED_aus_und_Blinken_aus" 1 "LED_ein_und_Blinken_aus" 2 "LED_ein_und_Blinken_ein_50_percent" 3 "reserviert" ;
VAL_ 2463978630 CHA_Drehschalter_VW_Blinken 0 "Init_oder_kein_modus_ausgewaehlt" 1 "Modus_1" 2 "Modus_2" 3 "Modus_3" 4 "Modus_4" 5 "Modus_5" 6 "Modus_6" 7 "Modus_7" 8 "Modus_8" 9 "Modus_9" 10 "Modus_10" 11 "Modus_11" 12 "Modus_12" 13 "Modus_13" 14 "Modus_14" 15 "Fehler" ;
VAL_ 2463978630 CHA_Drehschalter_VW_Istmodus 0 "keine_Schalterstellung" 1 "Schalterstellung_1" 2 "Schalterstellung_2" 3 "Schalterstellung_3" 4 "Schalterstellung_4" 5 "Schalterstellung_5" 6 "Schalterstellung_6" 7 "Schalterstellung_7" 8 "Schalterstellung_8" 9 "Schalterstellung_9" 10 "Schalterstellung_10" 11 "Schalterstellung_11" 12 "Schalterstellung_12" 13 "Schalterstellung_13" 14 "Schalterstellung_14" 15 "Schalterstellung_15" ;
VAL_ 2527679663 CHA_Ziel_FahrPr_Antrieb_LB 0 "keine_Funktion" 1 "Programm_1" 2 "Programm_2" 3 "Programm_3" 4 "Programm_4" 5 "Programm_5" 6 "Programm_6" 7 "Programm_7" 8 "Programm_8" 9 "Programm_9" 10 "Programm_10" 11 "Programm_11" 12 "Programm_12" 13 "Programm_13" 14 "Programm_14" 15 "Programm_15" ;
VAL_ 2527679663 CHA_Ziel_FahrPr_Fahrwerk_LB 0 "keine_Funktion" 1 "Programm_1" 2 "Programm_2" 3 "Programm_3" 4 "Programm_4" 5 "Programm_5" 6 "Programm_6" 7 "Programm_7" 8 "Programm_8" 9 "Programm_9" 10 "Programm_10" 11 "Programm_11" 12 "Programm_12" 13 "Programm_13" 14 "Programm_14" 15 "Programm_15" ;
VAL_ 2527679663 CHA_Ziel_FahrPr_Lenkung_LB 0 "keine_Funktion" 1 "Programm_1" 2 "Programm_2" 3 "Programm_3" 4 "Programm_4" 5 "Programm_5" 6 "Programm_6" 7 "Programm_7" 8 "Programm_8" 9 "Programm_9" 10 "Programm_10" 11 "Programm_11" 12 "Programm_12" 13 "Programm_13" 14 "Programm_14" 15 "Programm_15" ;
VAL_ 615 DR_Systemstatus 0 "Init oder kein Wert verfuegbar" 1 "Komfortabel" 2 "Normal" 3 "Sport 1" 4 "Sport 2" 5 "nicht funktionsfähig" 6 "Funktionseinschränkung aktiv" 7 "Notfahrfunktion" ;
VAL_ 615 DR_ESP_Zuschaltung 0 "keine_ESP_Beeinflussung" 1 "ESP_Zwangszuschaltung_gefordert" ;
VAL_ 615 DR_DynAGL_Anf_Entkopplung 0 "inaktiv" 1 "aktiv" ;
VAL_ 615 DR_DynAGL_Anf_im_Leerlauf 0 "inaktiv" 1 "aktiv" ;
VAL_ 615 EFP_Niveauzustand_Lift 0 "Init" 1 "gesenkt" 2 "heben" 3 "gehoben" 4 "senken" 5 "Fehler" ;
VAL_ 615 EFP_Verfuegbarkeit_Lift 0 "Init" 1 "verfuegbar" 2 "temporaer_nicht_verfuegbar" 3 "Fehler_Service_notwendig" 4 "Temperaturschutz" 5 "Fehler_Niveauplausibilisierung" ;
VAL_ 615 DR_Charisma_FahrPr 0 "keine_Funktion" 1 "Programm_1" 2 "Programm_2" 3 "Programm_3" 4 "Programm_4" 5 "Programm_5" 6 "Programm_6" 7 "Programm_7" 8 "Programm_8" 9 "Programm_9" 10 "Programm_10" 11 "Programm_11" 12 "Programm_12" 13 "Programm_13" 14 "Programm_14" 15 "Programm_15" ;
VAL_ 615 DR_Charisma_Status 0 "Init" 1 "verfuegbar" 2 "nicht_verfuegbar" 3 "asynchron_durch_Fahrerwunsch" ;
VAL_ 615 EFP_Vorlaufzeit_Lift 6 "Init" 7 "Fehler" ;
VAL_ 615 EFP_LstgBegr 1022 "Init" 1023 "Fehler" ;
VAL_ 1012 DC_HYB_iAktReserveLV 1022 "Init" 1023 "Fehler" ;
VAL_ 1012 DC_Verbrauch_Ueberlauf 0 "kein_Ueberlauf" 1 "Ueberlauf" ;
VAL_ 1012 DC_Verlustleistung 62 "Init" 63 "Fehler" ;
VAL_ 1012 DC_HYB_Auslastungsgrad 254 "Init" 255 "Fehler" ;
VAL_ 1714 DGN_Verlernzaehler 255 "ungültiger Zählerstand oder kein gültiger Fahrzyklus" ;
VAL_ 1714 KBI_Kilometerstand 1048574 "Init" 1048575 "Fehler" ;
VAL_ 1714 UH_Monat 0 "Init" 14 "Relatives_Datum" 15 "Fehler" ;
VAL_ 1714 UH_Tag 0 "Init" ;
VAL_ 1714 Kombi_02_alt 0 "aktuell" 1 "veraltet" ;
VAL_ 1714 Uhrzeit_01_alt 0 "aktuell" 1 "veraltet" ;
